VERSION ""

NS_ :

BS_:

BU_: WCM4 WCM3 WCM2 WCM VPM VLM VKM VICM VECM VDM VCU_RTOS_ETH VCU_ENTRY_ETH VCU_AGVM_ETH VCU UVM UPM TIM TEST_TOOL_1 TCP_ETH TCP TCM TCCM SRR_SRR_ETH SRR_SRR SRR_SLR_ETH SRR_SLR SRR_RR SRR_RF_ETH SRR_RF SRR_LR_CR SRR_LF_ETH SRR_LF SIB SDM SCL SBZA_R SBZA_L SBM SAM_RR SAM_RF SAM_LR SAM_LF SAM_BH SADS RadioLow_ETH RadioLow RSI_RTOS_ETH RSI RDCM PTM PLCM PFCM PDR_ETH PDR PCM PA ODS2 ODS NVM MTCM_R MTCM_L MSM_RR MSM_P MSM_LR MSM_D MSB2 MSB1 MRCM_R MRCM_L MFC LRR_RR_ETH LRR_LR_ETH LRR_CF_ETH LRR LRL_CF_ETH LIB_48V LIB1 IPC_INT IPC_GP IPC ICS_Info ICCM HVAC_FP_R HVAC_FP_F HUD_CAN HDLM FPI_RTOS_ETH FPI FOPM FCM_LC FCM EPSb EPS_1 EPSRAb EPSRAa EPS EOCM_HC_Superset EOCM_HCP2 EOCM ELM ECP_X1 ECP_S2 ECP_S ECP_MC ECP_H3 ECP_H2 ECP_H1 ECP_E ECM EBCM DMS DEFC DCM CSM_ETH CSM_AV CSM CGM_OTA_ETH CGM BSM_MH BSM_HEV BSM BCM ARS ARB APA AOS AMP ALC AHS AHL_AFL ADIMb ADIMa ACP2_MCU

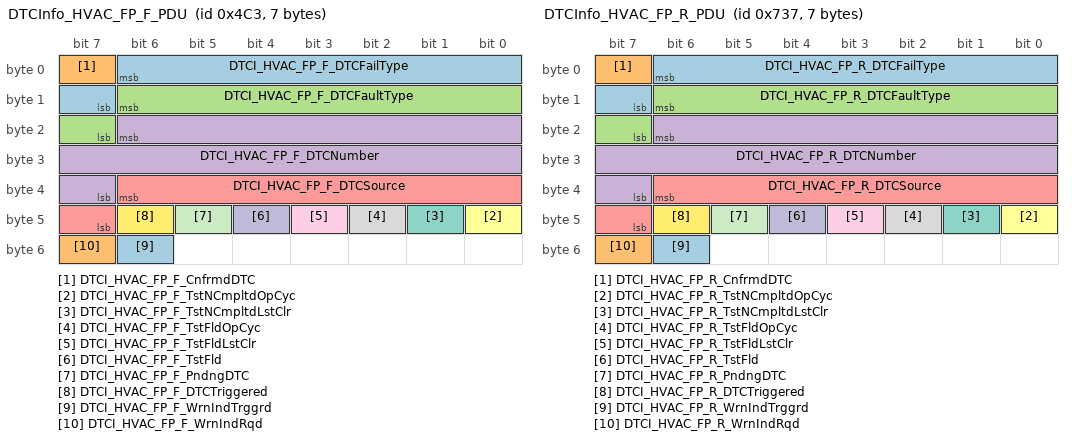
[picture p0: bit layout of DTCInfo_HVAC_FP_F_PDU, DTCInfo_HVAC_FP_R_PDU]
BO_ 1219 DTCInfo_HVAC_FP_F_PDU: 7 HVAC_FP_F
 SG_ DTCI_HVAC_FP_F_DTCFailType : 6|8@0+ (1,0) [0|255] "" TCP,CSM
 SG_ DTCI_HVAC_FP_F_CnfrmdDTC : 7|1@0+ (1,0) [0|1] "" TCP,CSM
 SG_ DTCI_HVAC_FP_F_DTCFaultType : 14|8@0+ (1,0) [0|3] "" TCP,CSM
 SG_ DTCI_HVAC_FP_F_DTCNumber : 22|16@0+ (1,0) [0|65535] "" TCP,CSM
 SG_ DTCI_HVAC_FP_F_DTCSource : 38|8@0+ (1,0) [0|255] "" CGM,TCP,CSM
 SG_ DTCI_HVAC_FP_F_TstNCmpltdOpCyc : 40|1@0+ (1,0) [0|1] "" TCP,CSM
 SG_ DTCI_HVAC_FP_F_TstNCmpltdLstClr : 41|1@0+ (1,0) [0|1] "" TCP,CSM
 SG_ DTCI_HVAC_FP_F_TstFldOpCyc : 42|1@0+ (1,0) [0|1] "" TCP,CSM
 SG_ DTCI_HVAC_FP_F_TstFldLstClr : 43|1@0+ (1,0) [0|1] "" TCP,CSM
 SG_ DTCI_HVAC_FP_F_TstFld : 44|1@0+ (1,0) [0|1] "" TCP,CSM
 SG_ DTCI_HVAC_FP_F_PndngDTC : 45|1@0+ (1,0) [0|1] "" TCP,CSM
 SG_ DTCI_HVAC_FP_F_DTCTriggered : 46|1@0+ (1,0) [0|1] "" TCP,CSM
 SG_ DTCI_HVAC_FP_F_WrnIndTrggrd : 54|1@0+ (1,0) [0|1] "" TCP,CSM
 SG_ DTCI_HVAC_FP_F_WrnIndRqd : 55|1@0+ (1,0) [0|1] "" TCP,CSM

BO_ 1847 DTCInfo_HVAC_FP_R_PDU: 7 HVAC_FP_R
 SG_ DTCI_HVAC_FP_R_DTCFailType : 6|8@0+ (1,0) [0|255] "" TCP,CSM
 SG_ DTCI_HVAC_FP_R_CnfrmdDTC : 7|1@0+ (1,0) [0|1] "" TCP,CSM
 SG_ DTCI_HVAC_FP_R_DTCFaultType : 14|8@0+ (1,0) [0|3] "" TCP,CSM
 SG_ DTCI_HVAC_FP_R_DTCNumber : 22|16@0+ (1,0) [0|65535] "" TCP,CSM
 SG_ DTCI_HVAC_FP_R_DTCSource : 38|8@0+ (1,0) [0|255] "" CGM,TCP,CSM
 SG_ DTCI_HVAC_FP_R_TstNCmpltdOpCyc : 40|1@0+ (1,0) [0|1] "" TCP,CSM
 SG_ DTCI_HVAC_FP_R_TstNCmpltdLstClr : 41|1@0+ (1,0) [0|1] "" TCP,CSM
 SG_ DTCI_HVAC_FP_R_TstFldOpCyc : 42|1@0+ (1,0) [0|1] "" TCP,CSM
 SG_ DTCI_HVAC_FP_R_TstFldLstClr : 43|1@0+ (1,0) [0|1] "" TCP,CSM
 SG_ DTCI_HVAC_FP_R_TstFld : 44|1@0+ (1,0) [0|1] "" TCP,CSM
 SG_ DTCI_HVAC_FP_R_PndngDTC : 45|1@0+ (1,0) [0|1] "" TCP,CSM
 SG_ DTCI_HVAC_FP_R_DTCTriggered : 46|1@0+ (1,0) [0|1] "" TCP,CSM
 SG_ DTCI_HVAC_FP_R_WrnIndTrggrd : 54|1@0+ (1,0) [0|1] "" TCP,CSM
 SG_ DTCI_HVAC_FP_R_WrnIndRqd : 55|1@0+ (1,0) [0|1] "" TCP,CSM

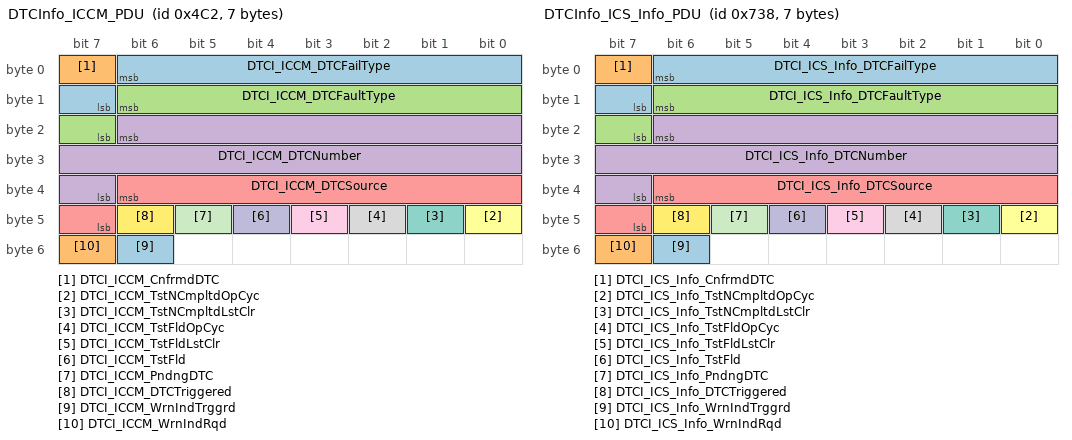
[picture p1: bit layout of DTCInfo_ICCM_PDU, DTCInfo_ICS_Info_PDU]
BO_ 1218 DTCInfo_ICCM_PDU: 7 CGM
 SG_ DTCI_ICCM_DTCFailType : 6|8@0+ (1,0) [0|255] "" TCP,CSM
 SG_ DTCI_ICCM_CnfrmdDTC : 7|1@0+ (1,0) [0|1] "" TCP,CSM
 SG_ DTCI_ICCM_DTCFaultType : 14|8@0+ (1,0) [0|3] "" TCP,CSM
 SG_ DTCI_ICCM_DTCNumber : 22|16@0+ (1,0) [0|65535] "" TCP,CSM
 SG_ DTCI_ICCM_DTCSource : 38|8@0+ (1,0) [0|255] "" TCP,CSM
 SG_ DTCI_ICCM_TstNCmpltdOpCyc : 40|1@0+ (1,0) [0|1] "" TCP,CSM
 SG_ DTCI_ICCM_TstNCmpltdLstClr : 41|1@0+ (1,0) [0|1] "" TCP,CSM
 SG_ DTCI_ICCM_TstFldOpCyc : 42|1@0+ (1,0) [0|1] "" TCP,CSM
 SG_ DTCI_ICCM_TstFldLstClr : 43|1@0+ (1,0) [0|1] "" TCP,CSM
 SG_ DTCI_ICCM_TstFld : 44|1@0+ (1,0) [0|1] "" TCP,CSM
 SG_ DTCI_ICCM_PndngDTC : 45|1@0+ (1,0) [0|1] "" TCP,CSM
 SG_ DTCI_ICCM_DTCTriggered : 46|1@0+ (1,0) [0|1] "" TCP,CSM
 SG_ DTCI_ICCM_WrnIndTrggrd : 54|1@0+ (1,0) [0|1] "" TCP,CSM
 SG_ DTCI_ICCM_WrnIndRqd : 55|1@0+ (1,0) [0|1] "" TCP,CSM

BO_ 1848 DTCInfo_ICS_Info_PDU: 7 ICS_Info
 SG_ DTCI_ICS_Info_DTCFailType : 6|8@0+ (1,0) [0|255] "" TCP,CSM
 SG_ DTCI_ICS_Info_CnfrmdDTC : 7|1@0+ (1,0) [0|1] "" TCP,CSM
 SG_ DTCI_ICS_Info_DTCFaultType : 14|8@0+ (1,0) [0|3] "" TCP,CSM
 SG_ DTCI_ICS_Info_DTCNumber : 22|16@0+ (1,0) [0|65535] "" TCP,CSM
 SG_ DTCI_ICS_Info_DTCSource : 38|8@0+ (1,0) [0|255] "" CGM,TCP,CSM
 SG_ DTCI_ICS_Info_TstNCmpltdOpCyc : 40|1@0+ (1,0) [0|1] "" TCP,CSM
 SG_ DTCI_ICS_Info_TstNCmpltdLstClr : 41|1@0+ (1,0) [0|1] "" TCP,CSM
 SG_ DTCI_ICS_Info_TstFldOpCyc : 42|1@0+ (1,0) [0|1] "" TCP,CSM
 SG_ DTCI_ICS_Info_TstFldLstClr : 43|1@0+ (1,0) [0|1] "" TCP,CSM
 SG_ DTCI_ICS_Info_TstFld : 44|1@0+ (1,0) [0|1] "" TCP,CSM
 SG_ DTCI_ICS_Info_PndngDTC : 45|1@0+ (1,0) [0|1] "" TCP,CSM
 SG_ DTCI_ICS_Info_DTCTriggered : 46|1@0+ (1,0) [0|1] "" TCP,CSM
 SG_ DTCI_ICS_Info_WrnIndTrggrd : 54|1@0+ (1,0) [0|1] "" TCP,CSM
 SG_ DTCI_ICS_Info_WrnIndRqd : 55|1@0+ (1,0) [0|1] "" TCP,CSM

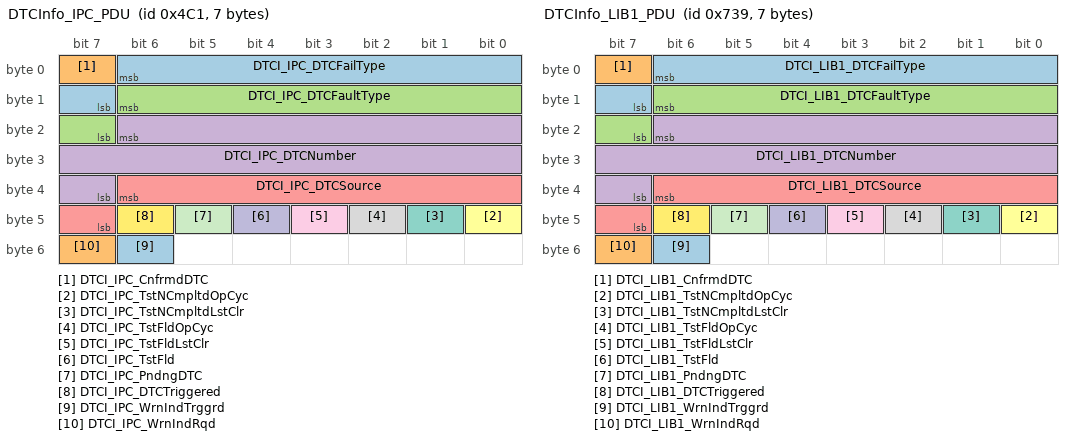
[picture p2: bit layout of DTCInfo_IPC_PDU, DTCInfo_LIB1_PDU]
BO_ 1217 DTCInfo_IPC_PDU: 7 IPC
 SG_ DTCI_IPC_DTCFailType : 6|8@0+ (1,0) [0|255] "" CGM,TCP,CSM
 SG_ DTCI_IPC_CnfrmdDTC : 7|1@0+ (1,0) [0|1] "" CGM,TCP,CSM
 SG_ DTCI_IPC_DTCFaultType : 14|8@0+ (1,0) [0|3] "" CGM,TCP,CSM
 SG_ DTCI_IPC_DTCNumber : 22|16@0+ (1,0) [0|65535] "" CGM,TCP,CSM
 SG_ DTCI_IPC_DTCSource : 38|8@0+ (1,0) [0|255] "" CGM,TCP,CSM
 SG_ DTCI_IPC_TstNCmpltdOpCyc : 40|1@0+ (1,0) [0|1] "" CGM,TCP,CSM
 SG_ DTCI_IPC_TstNCmpltdLstClr : 41|1@0+ (1,0) [0|1] "" CGM,TCP,CSM
 SG_ DTCI_IPC_TstFldOpCyc : 42|1@0+ (1,0) [0|1] "" CGM,TCP,CSM
 SG_ DTCI_IPC_TstFldLstClr : 43|1@0+ (1,0) [0|1] "" CGM,TCP,CSM
 SG_ DTCI_IPC_TstFld : 44|1@0+ (1,0) [0|1] "" CGM,TCP,CSM
 SG_ DTCI_IPC_PndngDTC : 45|1@0+ (1,0) [0|1] "" CGM,TCP,CSM
 SG_ DTCI_IPC_DTCTriggered : 46|1@0+ (1,0) [0|1] "" CGM,TCP,CSM
 SG_ DTCI_IPC_WrnIndTrggrd : 54|1@0+ (1,0) [0|1] "" CGM,TCP,CSM
 SG_ DTCI_IPC_WrnIndRqd : 55|1@0+ (1,0) [0|1] "" CGM,TCP,CSM

BO_ 1849 DTCInfo_LIB1_PDU: 7 CGM
 SG_ DTCI_LIB1_DTCFailType : 6|8@0+ (1,0) [0|255] "" TCP,CSM
 SG_ DTCI_LIB1_CnfrmdDTC : 7|1@0+ (1,0) [0|1] "" TCP,CSM
 SG_ DTCI_LIB1_DTCFaultType : 14|8@0+ (1,0) [0|3] "" TCP,CSM
 SG_ DTCI_LIB1_DTCNumber : 22|16@0+ (1,0) [0|65535] "" TCP,CSM
 SG_ DTCI_LIB1_DTCSource : 38|8@0+ (1,0) [0|255] "" TCP,CSM
 SG_ DTCI_LIB1_TstNCmpltdOpCyc : 40|1@0+ (1,0) [0|1] "" TCP,CSM
 SG_ DTCI_LIB1_TstNCmpltdLstClr : 41|1@0+ (1,0) [0|1] "" TCP,CSM
 SG_ DTCI_LIB1_TstFldOpCyc : 42|1@0+ (1,0) [0|1] "" TCP,CSM
 SG_ DTCI_LIB1_TstFldLstClr : 43|1@0+ (1,0) [0|1] "" TCP,CSM
 SG_ DTCI_LIB1_TstFld : 44|1@0+ (1,0) [0|1] "" TCP,CSM
 SG_ DTCI_LIB1_PndngDTC : 45|1@0+ (1,0) [0|1] "" TCP,CSM
 SG_ DTCI_LIB1_DTCTriggered : 46|1@0+ (1,0) [0|1] "" TCP,CSM
 SG_ DTCI_LIB1_WrnIndTrggrd : 54|1@0+ (1,0) [0|1] "" TCP,CSM
 SG_ DTCI_LIB1_WrnIndRqd : 55|1@0+ (1,0) [0|1] "" TCP,CSM

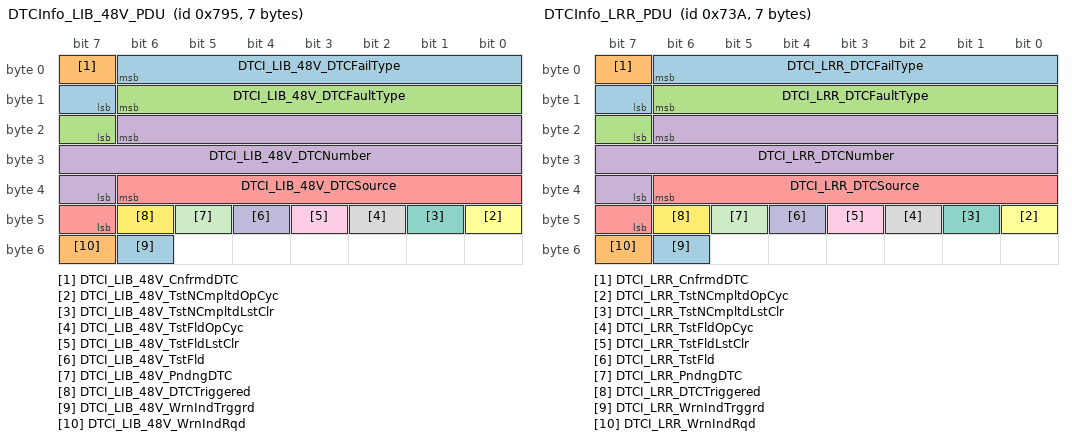
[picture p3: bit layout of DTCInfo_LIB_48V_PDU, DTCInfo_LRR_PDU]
BO_ 1941 DTCInfo_LIB_48V_PDU: 7 CGM
 SG_ DTCI_LIB_48V_DTCFailType : 6|8@0+ (1,0) [0|255] "" TCP
 SG_ DTCI_LIB_48V_CnfrmdDTC : 7|1@0+ (1,0) [0|1] "" TCP
 SG_ DTCI_LIB_48V_DTCFaultType : 14|8@0+ (1,0) [0|3] "" TCP
 SG_ DTCI_LIB_48V_DTCNumber : 22|16@0+ (1,0) [0|65535] "" TCP
 SG_ DTCI_LIB_48V_DTCSource : 38|8@0+ (1,0) [0|255] "" TCP
 SG_ DTCI_LIB_48V_TstNCmpltdOpCyc : 40|1@0+ (1,0) [0|1] "" TCP
 SG_ DTCI_LIB_48V_TstNCmpltdLstClr : 41|1@0+ (1,0) [0|1] "" TCP
 SG_ DTCI_LIB_48V_TstFldOpCyc : 42|1@0+ (1,0) [0|1] "" TCP
 SG_ DTCI_LIB_48V_TstFldLstClr : 43|1@0+ (1,0) [0|1] "" TCP
 SG_ DTCI_LIB_48V_TstFld : 44|1@0+ (1,0) [0|1] "" TCP
 SG_ DTCI_LIB_48V_PndngDTC : 45|1@0+ (1,0) [0|1] "" TCP
 SG_ DTCI_LIB_48V_DTCTriggered : 46|1@0+ (1,0) [0|1] "" TCP
 SG_ DTCI_LIB_48V_WrnIndTrggrd : 54|1@0+ (1,0) [0|1] "" TCP
 SG_ DTCI_LIB_48V_WrnIndRqd : 55|1@0+ (1,0) [0|1] "" TCP

BO_ 1850 DTCInfo_LRR_PDU: 7 CGM
 SG_ DTCI_LRR_DTCFailType : 6|8@0+ (1,0) [0|255] "" TCP,CSM
 SG_ DTCI_LRR_CnfrmdDTC : 7|1@0+ (1,0) [0|1] "" TCP,CSM
 SG_ DTCI_LRR_DTCFaultType : 14|8@0+ (1,0) [0|3] "" TCP,CSM
 SG_ DTCI_LRR_DTCNumber : 22|16@0+ (1,0) [0|65535] "" TCP,CSM
 SG_ DTCI_LRR_DTCSource : 38|8@0+ (1,0) [0|255] "" TCP,CSM
 SG_ DTCI_LRR_TstNCmpltdOpCyc : 40|1@0+ (1,0) [0|1] "" TCP,CSM
 SG_ DTCI_LRR_TstNCmpltdLstClr : 41|1@0+ (1,0) [0|1] "" TCP,CSM
 SG_ DTCI_LRR_TstFldOpCyc : 42|1@0+ (1,0) [0|1] "" TCP,CSM
 SG_ DTCI_LRR_TstFldLstClr : 43|1@0+ (1,0) [0|1] "" TCP,CSM
 SG_ DTCI_LRR_TstFld : 44|1@0+ (1,0) [0|1] "" TCP,CSM
 SG_ DTCI_LRR_PndngDTC : 45|1@0+ (1,0) [0|1] "" TCP,CSM
 SG_ DTCI_LRR_DTCTriggered : 46|1@0+ (1,0) [0|1] "" TCP,CSM
 SG_ DTCI_LRR_WrnIndTrggrd : 54|1@0+ (1,0) [0|1] "" TCP,CSM
 SG_ DTCI_LRR_WrnIndRqd : 55|1@0+ (1,0) [0|1] "" TCP,CSM

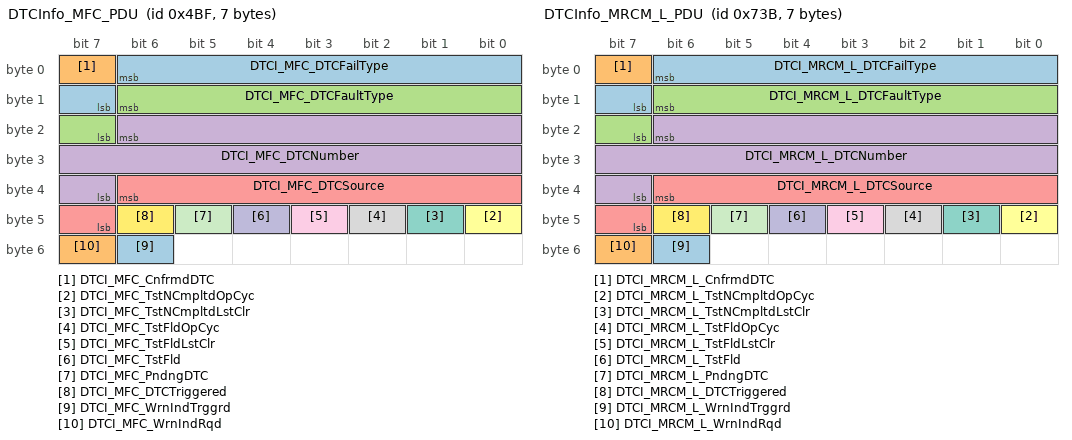
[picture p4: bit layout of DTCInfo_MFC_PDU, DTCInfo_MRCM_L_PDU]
BO_ 1215 DTCInfo_MFC_PDU: 7 MFC
 SG_ DTCI_MFC_DTCFailType : 6|8@0+ (1,0) [0|255] "" TCP,CSM
 SG_ DTCI_MFC_CnfrmdDTC : 7|1@0+ (1,0) [0|1] "" TCP,CSM
 SG_ DTCI_MFC_DTCFaultType : 14|8@0+ (1,0) [0|3] "" TCP,CSM
 SG_ DTCI_MFC_DTCNumber : 22|16@0+ (1,0) [0|65535] "" TCP,CSM
 SG_ DTCI_MFC_DTCSource : 38|8@0+ (1,0) [0|255] "" CGM,TCP,CSM
 SG_ DTCI_MFC_TstNCmpltdOpCyc : 40|1@0+ (1,0) [0|1] "" TCP,CSM
 SG_ DTCI_MFC_TstNCmpltdLstClr : 41|1@0+ (1,0) [0|1] "" TCP,CSM
 SG_ DTCI_MFC_TstFldOpCyc : 42|1@0+ (1,0) [0|1] "" TCP,CSM
 SG_ DTCI_MFC_TstFldLstClr : 43|1@0+ (1,0) [0|1] "" TCP,CSM
 SG_ DTCI_MFC_TstFld : 44|1@0+ (1,0) [0|1] "" TCP,CSM
 SG_ DTCI_MFC_PndngDTC : 45|1@0+ (1,0) [0|1] "" TCP,CSM
 SG_ DTCI_MFC_DTCTriggered : 46|1@0+ (1,0) [0|1] "" TCP,CSM
 SG_ DTCI_MFC_WrnIndTrggrd : 54|1@0+ (1,0) [0|1] "" TCP,CSM
 SG_ DTCI_MFC_WrnIndRqd : 55|1@0+ (1,0) [0|1] "" TCP,CSM

BO_ 1851 DTCInfo_MRCM_L_PDU: 7 CGM
 SG_ DTCI_MRCM_L_DTCFailType : 6|8@0+ (1,0) [0|255] "" TCP,CSM
 SG_ DTCI_MRCM_L_CnfrmdDTC : 7|1@0+ (1,0) [0|1] "" TCP,CSM
 SG_ DTCI_MRCM_L_DTCFaultType : 14|8@0+ (1,0) [0|3] "" TCP,CSM
 SG_ DTCI_MRCM_L_DTCNumber : 22|16@0+ (1,0) [0|65535] "" TCP,CSM
 SG_ DTCI_MRCM_L_DTCSource : 38|8@0+ (1,0) [0|255] "" TCP,CSM
 SG_ DTCI_MRCM_L_TstNCmpltdOpCyc : 40|1@0+ (1,0) [0|1] "" TCP,CSM
 SG_ DTCI_MRCM_L_TstNCmpltdLstClr : 41|1@0+ (1,0) [0|1] "" TCP,CSM
 SG_ DTCI_MRCM_L_TstFldOpCyc : 42|1@0+ (1,0) [0|1] "" TCP,CSM
 SG_ DTCI_MRCM_L_TstFldLstClr : 43|1@0+ (1,0) [0|1] "" TCP,CSM
 SG_ DTCI_MRCM_L_TstFld : 44|1@0+ (1,0) [0|1] "" TCP,CSM
 SG_ DTCI_MRCM_L_PndngDTC : 45|1@0+ (1,0) [0|1] "" TCP,CSM
 SG_ DTCI_MRCM_L_DTCTriggered : 46|1@0+ (1,0) [0|1] "" TCP,CSM
 SG_ DTCI_MRCM_L_WrnIndTrggrd : 54|1@0+ (1,0) [0|1] "" TCP,CSM
 SG_ DTCI_MRCM_L_WrnIndRqd : 55|1@0+ (1,0) [0|1] "" TCP,CSM

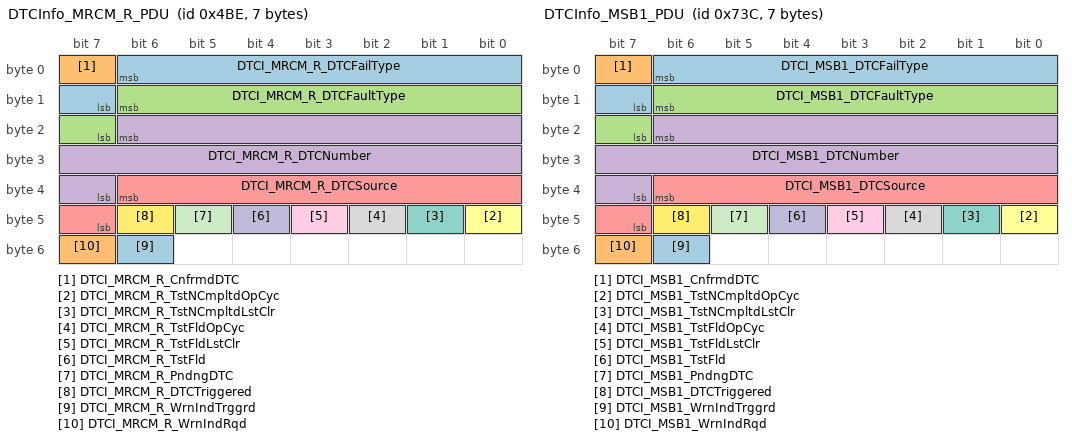
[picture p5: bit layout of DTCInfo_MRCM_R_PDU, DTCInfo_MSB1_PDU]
BO_ 1214 DTCInfo_MRCM_R_PDU: 7 CGM
 SG_ DTCI_MRCM_R_DTCFailType : 6|8@0+ (1,0) [0|255] "" TCP,CSM
 SG_ DTCI_MRCM_R_CnfrmdDTC : 7|1@0+ (1,0) [0|1] "" TCP,CSM
 SG_ DTCI_MRCM_R_DTCFaultType : 14|8@0+ (1,0) [0|3] "" TCP,CSM
 SG_ DTCI_MRCM_R_DTCNumber : 22|16@0+ (1,0) [0|65535] "" TCP,CSM
 SG_ DTCI_MRCM_R_DTCSource : 38|8@0+ (1,0) [0|255] "" TCP,CSM
 SG_ DTCI_MRCM_R_TstNCmpltdOpCyc : 40|1@0+ (1,0) [0|1] "" TCP,CSM
 SG_ DTCI_MRCM_R_TstNCmpltdLstClr : 41|1@0+ (1,0) [0|1] "" TCP,CSM
 SG_ DTCI_MRCM_R_TstFldOpCyc : 42|1@0+ (1,0) [0|1] "" TCP,CSM
 SG_ DTCI_MRCM_R_TstFldLstClr : 43|1@0+ (1,0) [0|1] "" TCP,CSM
 SG_ DTCI_MRCM_R_TstFld : 44|1@0+ (1,0) [0|1] "" TCP,CSM
 SG_ DTCI_MRCM_R_PndngDTC : 45|1@0+ (1,0) [0|1] "" TCP,CSM
 SG_ DTCI_MRCM_R_DTCTriggered : 46|1@0+ (1,0) [0|1] "" TCP,CSM
 SG_ DTCI_MRCM_R_WrnIndTrggrd : 54|1@0+ (1,0) [0|1] "" TCP,CSM
 SG_ DTCI_MRCM_R_WrnIndRqd : 55|1@0+ (1,0) [0|1] "" TCP,CSM

BO_ 1852 DTCInfo_MSB1_PDU: 7 CGM
 SG_ DTCI_MSB1_DTCFailType : 6|8@0+ (1,0) [0|255] "" TCP,CSM
 SG_ DTCI_MSB1_CnfrmdDTC : 7|1@0+ (1,0) [0|1] "" TCP,CSM
 SG_ DTCI_MSB1_DTCFaultType : 14|8@0+ (1,0) [0|3] "" TCP,CSM
 SG_ DTCI_MSB1_DTCNumber : 22|16@0+ (1,0) [0|65535] "" TCP,CSM
 SG_ DTCI_MSB1_DTCSource : 38|8@0+ (1,0) [0|255] "" TCP,CSM
 SG_ DTCI_MSB1_TstNCmpltdOpCyc : 40|1@0+ (1,0) [0|1] "" TCP,CSM
 SG_ DTCI_MSB1_TstNCmpltdLstClr : 41|1@0+ (1,0) [0|1] "" TCP,CSM
 SG_ DTCI_MSB1_TstFldOpCyc : 42|1@0+ (1,0) [0|1] "" TCP,CSM
 SG_ DTCI_MSB1_TstFldLstClr : 43|1@0+ (1,0) [0|1] "" TCP,CSM
 SG_ DTCI_MSB1_TstFld : 44|1@0+ (1,0) [0|1] "" TCP,CSM
 SG_ DTCI_MSB1_PndngDTC : 45|1@0+ (1,0) [0|1] "" TCP,CSM
 SG_ DTCI_MSB1_DTCTriggered : 46|1@0+ (1,0) [0|1] "" TCP,CSM
 SG_ DTCI_MSB1_WrnIndTrggrd : 54|1@0+ (1,0) [0|1] "" TCP,CSM
 SG_ DTCI_MSB1_WrnIndRqd : 55|1@0+ (1,0) [0|1] "" TCP,CSM

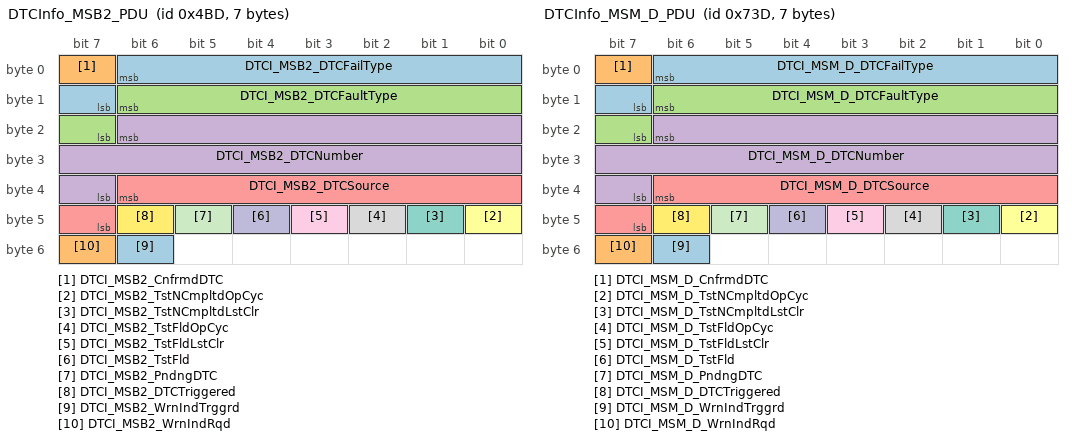
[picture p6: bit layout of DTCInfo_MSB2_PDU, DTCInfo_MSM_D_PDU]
BO_ 1213 DTCInfo_MSB2_PDU: 7 CGM
 SG_ DTCI_MSB2_DTCFailType : 6|8@0+ (1,0) [0|255] "" TCP,CSM
 SG_ DTCI_MSB2_CnfrmdDTC : 7|1@0+ (1,0) [0|1] "" TCP,CSM
 SG_ DTCI_MSB2_DTCFaultType : 14|8@0+ (1,0) [0|3] "" TCP,CSM
 SG_ DTCI_MSB2_DTCNumber : 22|16@0+ (1,0) [0|65535] "" TCP,CSM
 SG_ DTCI_MSB2_DTCSource : 38|8@0+ (1,0) [0|255] "" TCP,CSM
 SG_ DTCI_MSB2_TstNCmpltdOpCyc : 40|1@0+ (1,0) [0|1] "" TCP,CSM
 SG_ DTCI_MSB2_TstNCmpltdLstClr : 41|1@0+ (1,0) [0|1] "" TCP,CSM
 SG_ DTCI_MSB2_TstFldOpCyc : 42|1@0+ (1,0) [0|1] "" TCP,CSM
 SG_ DTCI_MSB2_TstFldLstClr : 43|1@0+ (1,0) [0|1] "" TCP,CSM
 SG_ DTCI_MSB2_TstFld : 44|1@0+ (1,0) [0|1] "" TCP,CSM
 SG_ DTCI_MSB2_PndngDTC : 45|1@0+ (1,0) [0|1] "" TCP,CSM
 SG_ DTCI_MSB2_DTCTriggered : 46|1@0+ (1,0) [0|1] "" TCP,CSM
 SG_ DTCI_MSB2_WrnIndTrggrd : 54|1@0+ (1,0) [0|1] "" TCP,CSM
 SG_ DTCI_MSB2_WrnIndRqd : 55|1@0+ (1,0) [0|1] "" TCP,CSM

BO_ 1853 DTCInfo_MSM_D_PDU: 7 CGM
 SG_ DTCI_MSM_D_DTCFailType : 6|8@0+ (1,0) [0|255] "" TCP,CSM
 SG_ DTCI_MSM_D_CnfrmdDTC : 7|1@0+ (1,0) [0|1] "" TCP,CSM
 SG_ DTCI_MSM_D_DTCFaultType : 14|8@0+ (1,0) [0|3] "" TCP,CSM
 SG_ DTCI_MSM_D_DTCNumber : 22|16@0+ (1,0) [0|65535] "" TCP,CSM
 SG_ DTCI_MSM_D_DTCSource : 38|8@0+ (1,0) [0|255] "" TCP,CSM
 SG_ DTCI_MSM_D_TstNCmpltdOpCyc : 40|1@0+ (1,0) [0|1] "" TCP,CSM
 SG_ DTCI_MSM_D_TstNCmpltdLstClr : 41|1@0+ (1,0) [0|1] "" TCP,CSM
 SG_ DTCI_MSM_D_TstFldOpCyc : 42|1@0+ (1,0) [0|1] "" TCP,CSM
 SG_ DTCI_MSM_D_TstFldLstClr : 43|1@0+ (1,0) [0|1] "" TCP,CSM
 SG_ DTCI_MSM_D_TstFld : 44|1@0+ (1,0) [0|1] "" TCP,CSM
 SG_ DTCI_MSM_D_PndngDTC : 45|1@0+ (1,0) [0|1] "" TCP,CSM
 SG_ DTCI_MSM_D_DTCTriggered : 46|1@0+ (1,0) [0|1] "" TCP,CSM
 SG_ DTCI_MSM_D_WrnIndTrggrd : 54|1@0+ (1,0) [0|1] "" TCP,CSM
 SG_ DTCI_MSM_D_WrnIndRqd : 55|1@0+ (1,0) [0|1] "" TCP,CSM

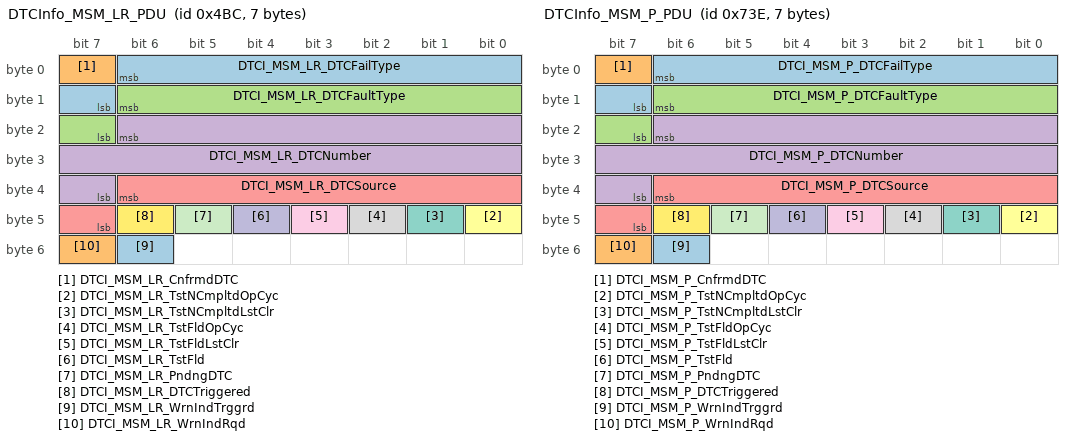
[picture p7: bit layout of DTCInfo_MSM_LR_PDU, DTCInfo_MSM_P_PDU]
BO_ 1212 DTCInfo_MSM_LR_PDU: 7 CGM
 SG_ DTCI_MSM_LR_DTCFailType : 6|8@0+ (1,0) [0|255] "" TCP,CSM
 SG_ DTCI_MSM_LR_CnfrmdDTC : 7|1@0+ (1,0) [0|1] "" TCP,CSM
 SG_ DTCI_MSM_LR_DTCFaultType : 14|8@0+ (1,0) [0|3] "" TCP,CSM
 SG_ DTCI_MSM_LR_DTCNumber : 22|16@0+ (1,0) [0|65535] "" TCP,CSM
 SG_ DTCI_MSM_LR_DTCSource : 38|8@0+ (1,0) [0|255] "" TCP,CSM
 SG_ DTCI_MSM_LR_TstNCmpltdOpCyc : 40|1@0+ (1,0) [0|1] "" TCP,CSM
 SG_ DTCI_MSM_LR_TstNCmpltdLstClr : 41|1@0+ (1,0) [0|1] "" TCP,CSM
 SG_ DTCI_MSM_LR_TstFldOpCyc : 42|1@0+ (1,0) [0|1] "" TCP,CSM
 SG_ DTCI_MSM_LR_TstFldLstClr : 43|1@0+ (1,0) [0|1] "" TCP,CSM
 SG_ DTCI_MSM_LR_TstFld : 44|1@0+ (1,0) [0|1] "" TCP,CSM
 SG_ DTCI_MSM_LR_PndngDTC : 45|1@0+ (1,0) [0|1] "" TCP,CSM
 SG_ DTCI_MSM_LR_DTCTriggered : 46|1@0+ (1,0) [0|1] "" TCP,CSM
 SG_ DTCI_MSM_LR_WrnIndTrggrd : 54|1@0+ (1,0) [0|1] "" TCP,CSM
 SG_ DTCI_MSM_LR_WrnIndRqd : 55|1@0+ (1,0) [0|1] "" TCP,CSM

BO_ 1854 DTCInfo_MSM_P_PDU: 7 CGM
 SG_ DTCI_MSM_P_DTCFailType : 6|8@0+ (1,0) [0|255] "" TCP,CSM
 SG_ DTCI_MSM_P_CnfrmdDTC : 7|1@0+ (1,0) [0|1] "" TCP,CSM
 SG_ DTCI_MSM_P_DTCFaultType : 14|8@0+ (1,0) [0|3] "" TCP,CSM
 SG_ DTCI_MSM_P_DTCNumber : 22|16@0+ (1,0) [0|65535] "" TCP,CSM
 SG_ DTCI_MSM_P_DTCSource : 38|8@0+ (1,0) [0|255] "" TCP,CSM
 SG_ DTCI_MSM_P_TstNCmpltdOpCyc : 40|1@0+ (1,0) [0|1] "" TCP,CSM
 SG_ DTCI_MSM_P_TstNCmpltdLstClr : 41|1@0+ (1,0) [0|1] "" TCP,CSM
 SG_ DTCI_MSM_P_TstFldOpCyc : 42|1@0+ (1,0) [0|1] "" TCP,CSM
 SG_ DTCI_MSM_P_TstFldLstClr : 43|1@0+ (1,0) [0|1] "" TCP,CSM
 SG_ DTCI_MSM_P_TstFld : 44|1@0+ (1,0) [0|1] "" TCP,CSM
 SG_ DTCI_MSM_P_PndngDTC : 45|1@0+ (1,0) [0|1] "" TCP,CSM
 SG_ DTCI_MSM_P_DTCTriggered : 46|1@0+ (1,0) [0|1] "" TCP,CSM
 SG_ DTCI_MSM_P_WrnIndTrggrd : 54|1@0+ (1,0) [0|1] "" TCP,CSM
 SG_ DTCI_MSM_P_WrnIndRqd : 55|1@0+ (1,0) [0|1] "" TCP,CSM

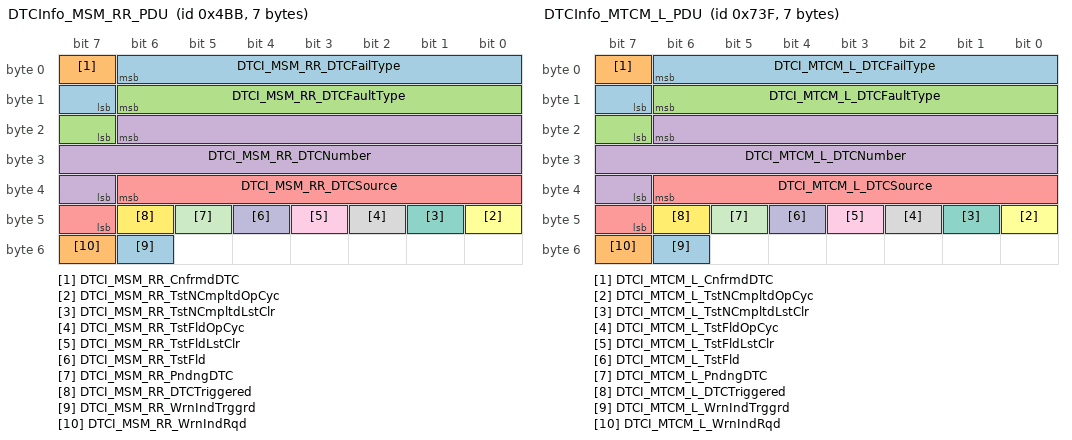
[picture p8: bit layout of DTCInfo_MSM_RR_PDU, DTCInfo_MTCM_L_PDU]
BO_ 1211 DTCInfo_MSM_RR_PDU: 7 CGM
 SG_ DTCI_MSM_RR_DTCFailType : 6|8@0+ (1,0) [0|255] "" TCP,CSM
 SG_ DTCI_MSM_RR_CnfrmdDTC : 7|1@0+ (1,0) [0|1] "" TCP,CSM
 SG_ DTCI_MSM_RR_DTCFaultType : 14|8@0+ (1,0) [0|3] "" TCP,CSM
 SG_ DTCI_MSM_RR_DTCNumber : 22|16@0+ (1,0) [0|65535] "" TCP,CSM
 SG_ DTCI_MSM_RR_DTCSource : 38|8@0+ (1,0) [0|255] "" TCP,CSM
 SG_ DTCI_MSM_RR_TstNCmpltdOpCyc : 40|1@0+ (1,0) [0|1] "" TCP,CSM
 SG_ DTCI_MSM_RR_TstNCmpltdLstClr : 41|1@0+ (1,0) [0|1] "" TCP,CSM
 SG_ DTCI_MSM_RR_TstFldOpCyc : 42|1@0+ (1,0) [0|1] "" TCP,CSM
 SG_ DTCI_MSM_RR_TstFldLstClr : 43|1@0+ (1,0) [0|1] "" TCP,CSM
 SG_ DTCI_MSM_RR_TstFld : 44|1@0+ (1,0) [0|1] "" TCP,CSM
 SG_ DTCI_MSM_RR_PndngDTC : 45|1@0+ (1,0) [0|1] "" TCP,CSM
 SG_ DTCI_MSM_RR_DTCTriggered : 46|1@0+ (1,0) [0|1] "" TCP,CSM
 SG_ DTCI_MSM_RR_WrnIndTrggrd : 54|1@0+ (1,0) [0|1] "" TCP,CSM
 SG_ DTCI_MSM_RR_WrnIndRqd : 55|1@0+ (1,0) [0|1] "" TCP,CSM

BO_ 1855 DTCInfo_MTCM_L_PDU: 7 CGM
 SG_ DTCI_MTCM_L_DTCFailType : 6|8@0+ (1,0) [0|255] "" TCP,CSM
 SG_ DTCI_MTCM_L_CnfrmdDTC : 7|1@0+ (1,0) [0|1] "" TCP,CSM
 SG_ DTCI_MTCM_L_DTCFaultType : 14|8@0+ (1,0) [0|3] "" TCP,CSM
 SG_ DTCI_MTCM_L_DTCNumber : 22|16@0+ (1,0) [0|65535] "" TCP,CSM
 SG_ DTCI_MTCM_L_DTCSource : 38|8@0+ (1,0) [0|255] "" TCP,CSM
 SG_ DTCI_MTCM_L_TstNCmpltdOpCyc : 40|1@0+ (1,0) [0|1] "" TCP,CSM
 SG_ DTCI_MTCM_L_TstNCmpltdLstClr : 41|1@0+ (1,0) [0|1] "" TCP,CSM
 SG_ DTCI_MTCM_L_TstFldOpCyc : 42|1@0+ (1,0) [0|1] "" TCP,CSM
 SG_ DTCI_MTCM_L_TstFldLstClr : 43|1@0+ (1,0) [0|1] "" TCP,CSM
 SG_ DTCI_MTCM_L_TstFld : 44|1@0+ (1,0) [0|1] "" TCP,CSM
 SG_ DTCI_MTCM_L_PndngDTC : 45|1@0+ (1,0) [0|1] "" TCP,CSM
 SG_ DTCI_MTCM_L_DTCTriggered : 46|1@0+ (1,0) [0|1] "" TCP,CSM
 SG_ DTCI_MTCM_L_WrnIndTrggrd : 54|1@0+ (1,0) [0|1] "" TCP,CSM
 SG_ DTCI_MTCM_L_WrnIndRqd : 55|1@0+ (1,0) [0|1] "" TCP,CSM

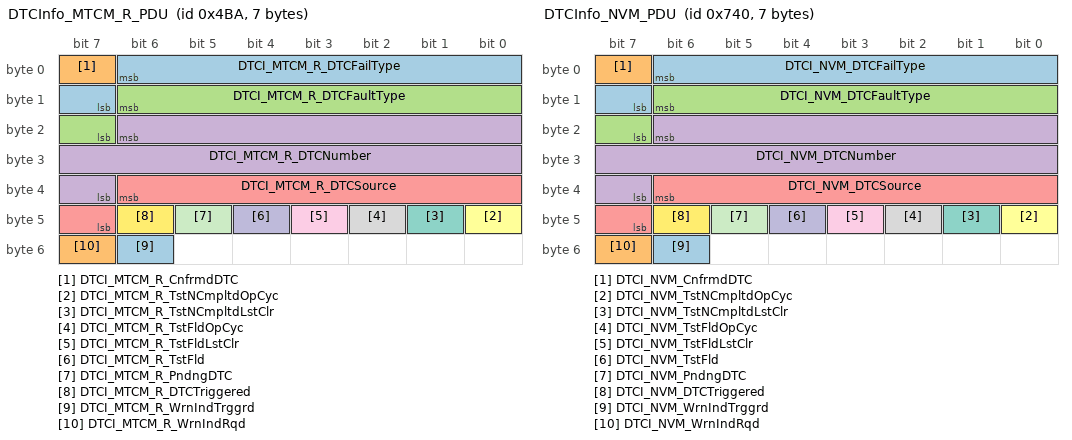
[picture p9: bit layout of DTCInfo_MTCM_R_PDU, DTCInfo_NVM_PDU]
BO_ 1210 DTCInfo_MTCM_R_PDU: 7 CGM
 SG_ DTCI_MTCM_R_DTCFailType : 6|8@0+ (1,0) [0|255] "" TCP,CSM
 SG_ DTCI_MTCM_R_CnfrmdDTC : 7|1@0+ (1,0) [0|1] "" TCP,CSM
 SG_ DTCI_MTCM_R_DTCFaultType : 14|8@0+ (1,0) [0|3] "" TCP,CSM
 SG_ DTCI_MTCM_R_DTCNumber : 22|16@0+ (1,0) [0|65535] "" TCP,CSM
 SG_ DTCI_MTCM_R_DTCSource : 38|8@0+ (1,0) [0|255] "" TCP,CSM
 SG_ DTCI_MTCM_R_TstNCmpltdOpCyc : 40|1@0+ (1,0) [0|1] "" TCP,CSM
 SG_ DTCI_MTCM_R_TstNCmpltdLstClr : 41|1@0+ (1,0) [0|1] "" TCP,CSM
 SG_ DTCI_MTCM_R_TstFldOpCyc : 42|1@0+ (1,0) [0|1] "" TCP,CSM
 SG_ DTCI_MTCM_R_TstFldLstClr : 43|1@0+ (1,0) [0|1] "" TCP,CSM
 SG_ DTCI_MTCM_R_TstFld : 44|1@0+ (1,0) [0|1] "" TCP,CSM
 SG_ DTCI_MTCM_R_PndngDTC : 45|1@0+ (1,0) [0|1] "" TCP,CSM
 SG_ DTCI_MTCM_R_DTCTriggered : 46|1@0+ (1,0) [0|1] "" TCP,CSM
 SG_ DTCI_MTCM_R_WrnIndTrggrd : 54|1@0+ (1,0) [0|1] "" TCP,CSM
 SG_ DTCI_MTCM_R_WrnIndRqd : 55|1@0+ (1,0) [0|1] "" TCP,CSM

BO_ 1856 DTCInfo_NVM_PDU: 7 CGM
 SG_ DTCI_NVM_DTCFailType : 6|8@0+ (1,0) [0|255] "" TCP,CSM
 SG_ DTCI_NVM_CnfrmdDTC : 7|1@0+ (1,0) [0|1] "" TCP,CSM
 SG_ DTCI_NVM_DTCFaultType : 14|8@0+ (1,0) [0|3] "" TCP,CSM
 SG_ DTCI_NVM_DTCNumber : 22|16@0+ (1,0) [0|65535] "" TCP,CSM
 SG_ DTCI_NVM_DTCSource : 38|8@0+ (1,0) [0|255] "" TCP,CSM
 SG_ DTCI_NVM_TstNCmpltdOpCyc : 40|1@0+ (1,0) [0|1] "" TCP,CSM
 SG_ DTCI_NVM_TstNCmpltdLstClr : 41|1@0+ (1,0) [0|1] "" TCP,CSM
 SG_ DTCI_NVM_TstFldOpCyc : 42|1@0+ (1,0) [0|1] "" TCP,CSM
 SG_ DTCI_NVM_TstFldLstClr : 43|1@0+ (1,0) [0|1] "" TCP,CSM
 SG_ DTCI_NVM_TstFld : 44|1@0+ (1,0) [0|1] "" TCP,CSM
 SG_ DTCI_NVM_PndngDTC : 45|1@0+ (1,0) [0|1] "" TCP,CSM
 SG_ DTCI_NVM_DTCTriggered : 46|1@0+ (1,0) [0|1] "" TCP,CSM
 SG_ DTCI_NVM_WrnIndTrggrd : 54|1@0+ (1,0) [0|1] "" TCP,CSM
 SG_ DTCI_NVM_WrnIndRqd : 55|1@0+ (1,0) [0|1] "" TCP,CSM

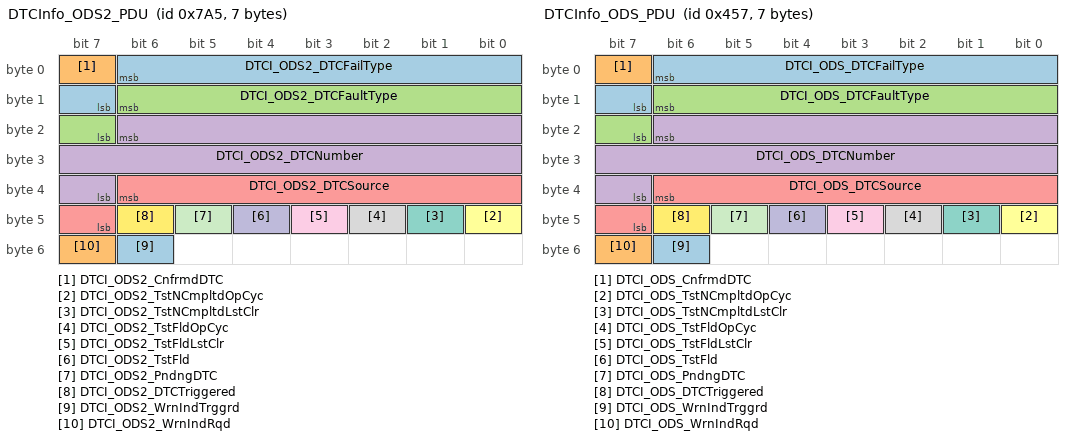
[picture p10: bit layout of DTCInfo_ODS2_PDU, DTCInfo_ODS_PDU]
BO_ 1957 DTCInfo_ODS2_PDU: 7 CGM
 SG_ DTCI_ODS2_DTCFailType : 6|8@0+ (1,0) [0|255] "" TCP
 SG_ DTCI_ODS2_CnfrmdDTC : 7|1@0+ (1,0) [0|1] "" TCP
 SG_ DTCI_ODS2_DTCFaultType : 14|8@0+ (1,0) [0|3] "" TCP
 SG_ DTCI_ODS2_DTCNumber : 22|16@0+ (1,0) [0|65535] "" TCP
 SG_ DTCI_ODS2_DTCSource : 38|8@0+ (1,0) [0|255] "" TCP
 SG_ DTCI_ODS2_TstNCmpltdOpCyc : 40|1@0+ (1,0) [0|1] "" TCP
 SG_ DTCI_ODS2_TstNCmpltdLstClr : 41|1@0+ (1,0) [0|1] "" TCP
 SG_ DTCI_ODS2_TstFldOpCyc : 42|1@0+ (1,0) [0|1] "" TCP
 SG_ DTCI_ODS2_TstFldLstClr : 43|1@0+ (1,0) [0|1] "" TCP
 SG_ DTCI_ODS2_TstFld : 44|1@0+ (1,0) [0|1] "" TCP
 SG_ DTCI_ODS2_PndngDTC : 45|1@0+ (1,0) [0|1] "" TCP
 SG_ DTCI_ODS2_DTCTriggered : 46|1@0+ (1,0) [0|1] "" TCP
 SG_ DTCI_ODS2_WrnIndTrggrd : 54|1@0+ (1,0) [0|1] "" TCP
 SG_ DTCI_ODS2_WrnIndRqd : 55|1@0+ (1,0) [0|1] "" TCP

BO_ 1111 DTCInfo_ODS_PDU: 7 CGM
 SG_ DTCI_ODS_DTCFailType : 6|8@0+ (1,0) [0|255] "" TCP
 SG_ DTCI_ODS_CnfrmdDTC : 7|1@0+ (1,0) [0|1] "" TCP
 SG_ DTCI_ODS_DTCFaultType : 14|8@0+ (1,0) [0|3] "" TCP
 SG_ DTCI_ODS_DTCNumber : 22|16@0+ (1,0) [0|65535] "" TCP
 SG_ DTCI_ODS_DTCSource : 38|8@0+ (1,0) [0|255] "" TCP
 SG_ DTCI_ODS_TstNCmpltdOpCyc : 40|1@0+ (1,0) [0|1] "" TCP
 SG_ DTCI_ODS_TstNCmpltdLstClr : 41|1@0+ (1,0) [0|1] "" TCP
 SG_ DTCI_ODS_TstFldOpCyc : 42|1@0+ (1,0) [0|1] "" TCP
 SG_ DTCI_ODS_TstFldLstClr : 43|1@0+ (1,0) [0|1] "" TCP
 SG_ DTCI_ODS_TstFld : 44|1@0+ (1,0) [0|1] "" TCP
 SG_ DTCI_ODS_PndngDTC : 45|1@0+ (1,0) [0|1] "" TCP
 SG_ DTCI_ODS_DTCTriggered : 46|1@0+ (1,0) [0|1] "" TCP
 SG_ DTCI_ODS_WrnIndTrggrd : 54|1@0+ (1,0) [0|1] "" TCP
 SG_ DTCI_ODS_WrnIndRqd : 55|1@0+ (1,0) [0|1] "" TCP

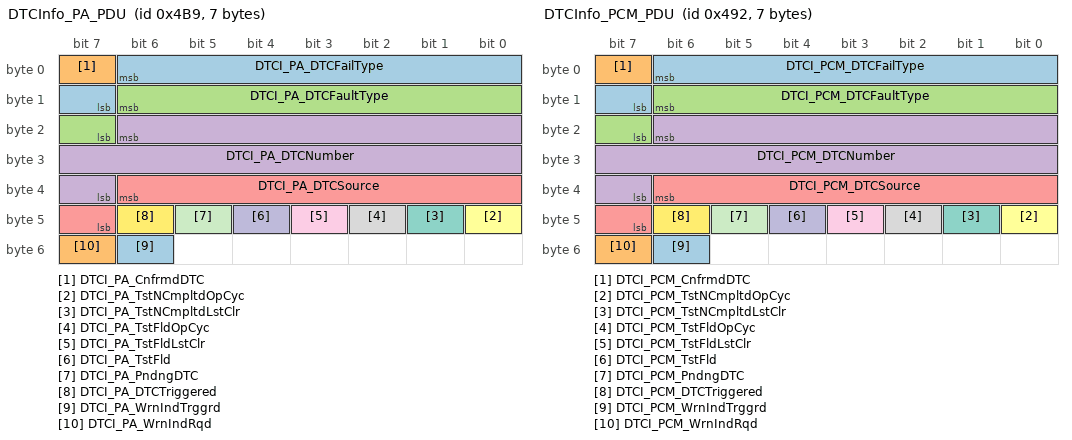
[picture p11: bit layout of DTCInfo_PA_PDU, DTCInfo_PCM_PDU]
BO_ 1209 DTCInfo_PA_PDU: 7 CGM
 SG_ DTCI_PA_DTCFailType : 6|8@0+ (1,0) [0|255] "" TCP,CSM
 SG_ DTCI_PA_CnfrmdDTC : 7|1@0+ (1,0) [0|1] "" TCP,CSM
 SG_ DTCI_PA_DTCFaultType : 14|8@0+ (1,0) [0|3] "" TCP,CSM
 SG_ DTCI_PA_DTCNumber : 22|16@0+ (1,0) [0|65535] "" TCP,CSM
 SG_ DTCI_PA_DTCSource : 38|8@0+ (1,0) [0|255] "" TCP,CSM
 SG_ DTCI_PA_TstNCmpltdOpCyc : 40|1@0+ (1,0) [0|1] "" TCP,CSM
 SG_ DTCI_PA_TstNCmpltdLstClr : 41|1@0+ (1,0) [0|1] "" TCP,CSM
 SG_ DTCI_PA_TstFldOpCyc : 42|1@0+ (1,0) [0|1] "" TCP,CSM
 SG_ DTCI_PA_TstFldLstClr : 43|1@0+ (1,0) [0|1] "" TCP,CSM
 SG_ DTCI_PA_TstFld : 44|1@0+ (1,0) [0|1] "" TCP,CSM
 SG_ DTCI_PA_PndngDTC : 45|1@0+ (1,0) [0|1] "" TCP,CSM
 SG_ DTCI_PA_DTCTriggered : 46|1@0+ (1,0) [0|1] "" TCP,CSM
 SG_ DTCI_PA_WrnIndTrggrd : 54|1@0+ (1,0) [0|1] "" TCP,CSM
 SG_ DTCI_PA_WrnIndRqd : 55|1@0+ (1,0) [0|1] "" TCP,CSM

BO_ 1170 DTCInfo_PCM_PDU: 7 CGM
 SG_ DTCI_PCM_DTCFailType : 6|8@0+ (1,0) [0|255] "" TCP
 SG_ DTCI_PCM_CnfrmdDTC : 7|1@0+ (1,0) [0|1] "" TCP
 SG_ DTCI_PCM_DTCFaultType : 14|8@0+ (1,0) [0|3] "" TCP
 SG_ DTCI_PCM_DTCNumber : 22|16@0+ (1,0) [0|65535] "" TCP
 SG_ DTCI_PCM_DTCSource : 38|8@0+ (1,0) [0|255] "" TCP
 SG_ DTCI_PCM_TstNCmpltdOpCyc : 40|1@0+ (1,0) [0|1] "" TCP
 SG_ DTCI_PCM_TstNCmpltdLstClr : 41|1@0+ (1,0) [0|1] "" TCP
 SG_ DTCI_PCM_TstFldOpCyc : 42|1@0+ (1,0) [0|1] "" TCP
 SG_ DTCI_PCM_TstFldLstClr : 43|1@0+ (1,0) [0|1] "" TCP
 SG_ DTCI_PCM_TstFld : 44|1@0+ (1,0) [0|1] "" TCP
 SG_ DTCI_PCM_PndngDTC : 45|1@0+ (1,0) [0|1] "" TCP
 SG_ DTCI_PCM_DTCTriggered : 46|1@0+ (1,0) [0|1] "" TCP
 SG_ DTCI_PCM_WrnIndTrggrd : 54|1@0+ (1,0) [0|1] "" TCP
 SG_ DTCI_PCM_WrnIndRqd : 55|1@0+ (1,0) [0|1] "" TCP

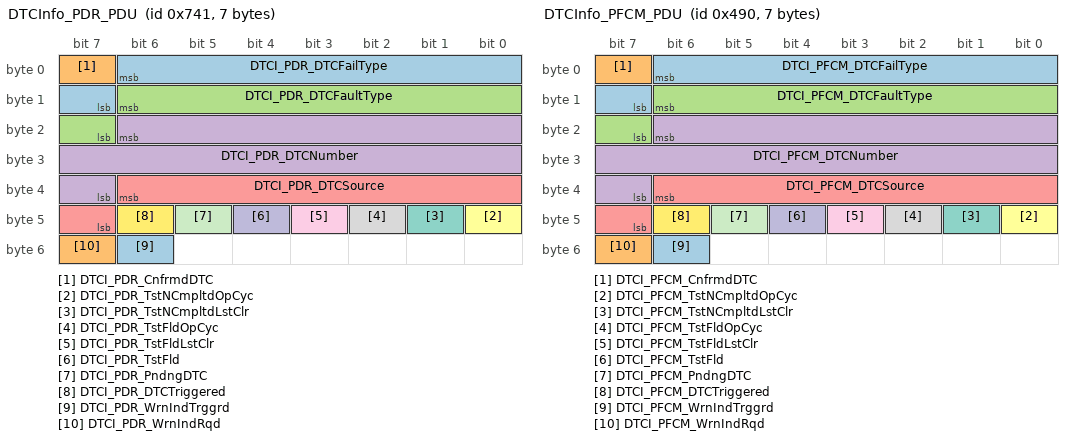
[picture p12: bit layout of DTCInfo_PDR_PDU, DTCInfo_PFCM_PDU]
BO_ 1857 DTCInfo_PDR_PDU: 7 PDR
 SG_ DTCI_PDR_DTCFailType : 6|8@0+ (1,0) [0|255] "" TCP,CSM
 SG_ DTCI_PDR_CnfrmdDTC : 7|1@0+ (1,0) [0|1] "" TCP,CSM
 SG_ DTCI_PDR_DTCFaultType : 14|8@0+ (1,0) [0|3] "" TCP,CSM
 SG_ DTCI_PDR_DTCNumber : 22|16@0+ (1,0) [0|65535] "" TCP,CSM
 SG_ DTCI_PDR_DTCSource : 38|8@0+ (1,0) [0|255] "" CGM,TCP,CSM
 SG_ DTCI_PDR_TstNCmpltdOpCyc : 40|1@0+ (1,0) [0|1] "" TCP,CSM
 SG_ DTCI_PDR_TstNCmpltdLstClr : 41|1@0+ (1,0) [0|1] "" TCP,CSM
 SG_ DTCI_PDR_TstFldOpCyc : 42|1@0+ (1,0) [0|1] "" TCP,CSM
 SG_ DTCI_PDR_TstFldLstClr : 43|1@0+ (1,0) [0|1] "" TCP,CSM
 SG_ DTCI_PDR_TstFld : 44|1@0+ (1,0) [0|1] "" TCP,CSM
 SG_ DTCI_PDR_PndngDTC : 45|1@0+ (1,0) [0|1] "" TCP,CSM
 SG_ DTCI_PDR_DTCTriggered : 46|1@0+ (1,0) [0|1] "" TCP,CSM
 SG_ DTCI_PDR_WrnIndTrggrd : 54|1@0+ (1,0) [0|1] "" TCP,CSM
 SG_ DTCI_PDR_WrnIndRqd : 55|1@0+ (1,0) [0|1] "" TCP,CSM

BO_ 1168 DTCInfo_PFCM_PDU: 7 CGM
 SG_ DTCI_PFCM_DTCFailType : 6|8@0+ (1,0) [0|255] "" TCP
 SG_ DTCI_PFCM_CnfrmdDTC : 7|1@0+ (1,0) [0|1] "" TCP
 SG_ DTCI_PFCM_DTCFaultType : 14|8@0+ (1,0) [0|3] "" TCP
 SG_ DTCI_PFCM_DTCNumber : 22|16@0+ (1,0) [0|65535] "" TCP
 SG_ DTCI_PFCM_DTCSource : 38|8@0+ (1,0) [0|255] "" TCP
 SG_ DTCI_PFCM_TstNCmpltdOpCyc : 40|1@0+ (1,0) [0|1] "" TCP
 SG_ DTCI_PFCM_TstNCmpltdLstClr : 41|1@0+ (1,0) [0|1] "" TCP
 SG_ DTCI_PFCM_TstFldOpCyc : 42|1@0+ (1,0) [0|1] "" TCP
 SG_ DTCI_PFCM_TstFldLstClr : 43|1@0+ (1,0) [0|1] "" TCP
 SG_ DTCI_PFCM_TstFld : 44|1@0+ (1,0) [0|1] "" TCP
 SG_ DTCI_PFCM_PndngDTC : 45|1@0+ (1,0) [0|1] "" TCP
 SG_ DTCI_PFCM_DTCTriggered : 46|1@0+ (1,0) [0|1] "" TCP
 SG_ DTCI_PFCM_WrnIndTrggrd : 54|1@0+ (1,0) [0|1] "" TCP
 SG_ DTCI_PFCM_WrnIndRqd : 55|1@0+ (1,0) [0|1] "" TCP

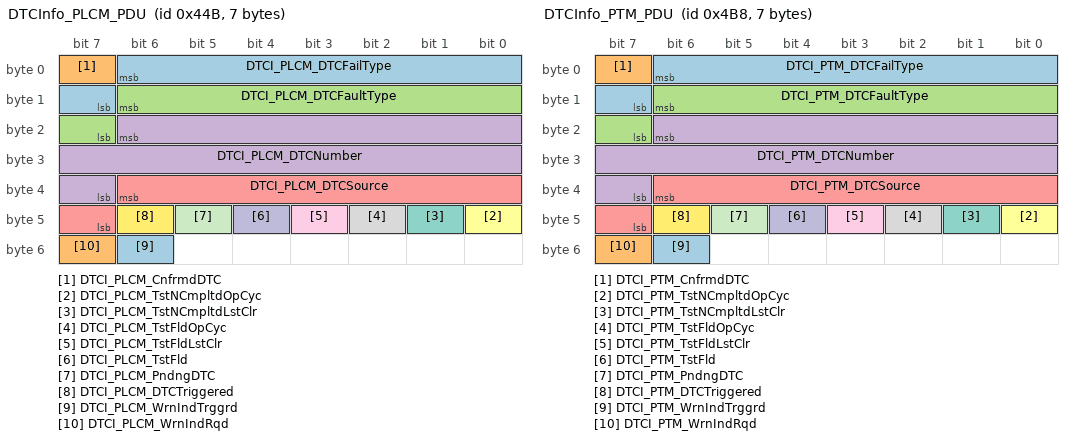
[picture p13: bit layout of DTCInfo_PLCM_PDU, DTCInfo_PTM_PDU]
BO_ 1099 DTCInfo_PLCM_PDU: 7 PLCM
 SG_ DTCI_PLCM_DTCFailType : 6|8@0+ (1,0) [0|255] "" TCP
 SG_ DTCI_PLCM_CnfrmdDTC : 7|1@0+ (1,0) [0|1] "" TCP
 SG_ DTCI_PLCM_DTCFaultType : 14|8@0+ (1,0) [0|3] "" TCP
 SG_ DTCI_PLCM_DTCNumber : 22|16@0+ (1,0) [0|65535] "" TCP
 SG_ DTCI_PLCM_DTCSource : 38|8@0+ (1,0) [0|255] "" CGM,TCP
 SG_ DTCI_PLCM_TstNCmpltdOpCyc : 40|1@0+ (1,0) [0|1] "" TCP
 SG_ DTCI_PLCM_TstNCmpltdLstClr : 41|1@0+ (1,0) [0|1] "" TCP
 SG_ DTCI_PLCM_TstFldOpCyc : 42|1@0+ (1,0) [0|1] "" TCP
 SG_ DTCI_PLCM_TstFldLstClr : 43|1@0+ (1,0) [0|1] "" TCP
 SG_ DTCI_PLCM_TstFld : 44|1@0+ (1,0) [0|1] "" TCP
 SG_ DTCI_PLCM_PndngDTC : 45|1@0+ (1,0) [0|1] "" TCP
 SG_ DTCI_PLCM_DTCTriggered : 46|1@0+ (1,0) [0|1] "" TCP
 SG_ DTCI_PLCM_WrnIndTrggrd : 54|1@0+ (1,0) [0|1] "" TCP
 SG_ DTCI_PLCM_WrnIndRqd : 55|1@0+ (1,0) [0|1] "" TCP

BO_ 1208 DTCInfo_PTM_PDU: 7 CGM
 SG_ DTCI_PTM_DTCFailType : 6|8@0+ (1,0) [0|255] "" TCP,CSM
 SG_ DTCI_PTM_CnfrmdDTC : 7|1@0+ (1,0) [0|1] "" TCP,CSM
 SG_ DTCI_PTM_DTCFaultType : 14|8@0+ (1,0) [0|3] "" TCP,CSM
 SG_ DTCI_PTM_DTCNumber : 22|16@0+ (1,0) [0|65535] "" TCP,CSM
 SG_ DTCI_PTM_DTCSource : 38|8@0+ (1,0) [0|255] "" TCP,CSM
 SG_ DTCI_PTM_TstNCmpltdOpCyc : 40|1@0+ (1,0) [0|1] "" TCP,CSM
 SG_ DTCI_PTM_TstNCmpltdLstClr : 41|1@0+ (1,0) [0|1] "" TCP,CSM
 SG_ DTCI_PTM_TstFldOpCyc : 42|1@0+ (1,0) [0|1] "" TCP,CSM
 SG_ DTCI_PTM_TstFldLstClr : 43|1@0+ (1,0) [0|1] "" TCP,CSM
 SG_ DTCI_PTM_TstFld : 44|1@0+ (1,0) [0|1] "" TCP,CSM
 SG_ DTCI_PTM_PndngDTC : 45|1@0+ (1,0) [0|1] "" TCP,CSM
 SG_ DTCI_PTM_DTCTriggered : 46|1@0+ (1,0) [0|1] "" TCP,CSM
 SG_ DTCI_PTM_WrnIndTrggrd : 54|1@0+ (1,0) [0|1] "" TCP,CSM
 SG_ DTCI_PTM_WrnIndRqd : 55|1@0+ (1,0) [0|1] "" TCP,CSM

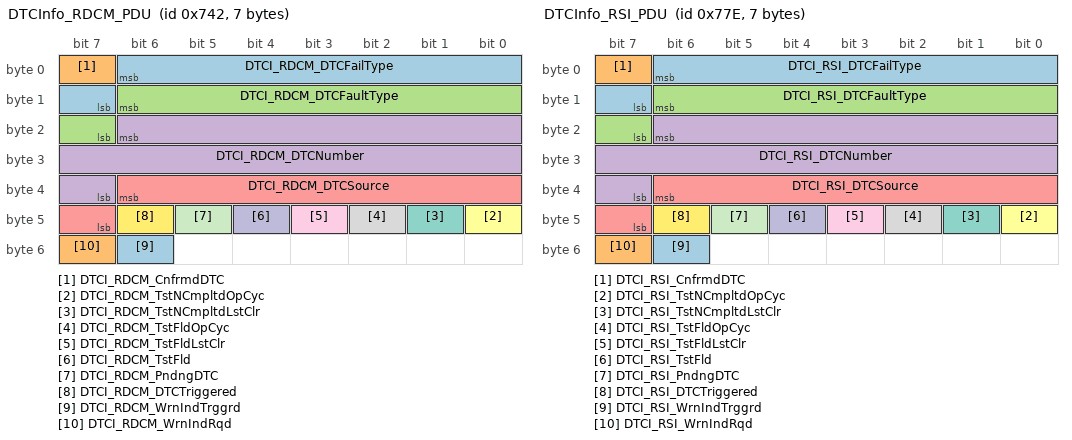
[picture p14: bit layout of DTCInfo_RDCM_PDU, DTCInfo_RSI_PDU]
BO_ 1858 DTCInfo_RDCM_PDU: 7 CGM
 SG_ DTCI_RDCM_DTCFailType : 6|8@0+ (1,0) [0|255] "" TCP,CSM
 SG_ DTCI_RDCM_CnfrmdDTC : 7|1@0+ (1,0) [0|1] "" TCP,CSM
 SG_ DTCI_RDCM_DTCFaultType : 14|8@0+ (1,0) [0|3] "" TCP,CSM
 SG_ DTCI_RDCM_DTCNumber : 22|16@0+ (1,0) [0|65535] "" TCP,CSM
 SG_ DTCI_RDCM_DTCSource : 38|8@0+ (1,0) [0|255] "" TCP,CSM
 SG_ DTCI_RDCM_TstNCmpltdOpCyc : 40|1@0+ (1,0) [0|1] "" TCP,CSM
 SG_ DTCI_RDCM_TstNCmpltdLstClr : 41|1@0+ (1,0) [0|1] "" TCP,CSM
 SG_ DTCI_RDCM_TstFldOpCyc : 42|1@0+ (1,0) [0|1] "" TCP,CSM
 SG_ DTCI_RDCM_TstFldLstClr : 43|1@0+ (1,0) [0|1] "" TCP,CSM
 SG_ DTCI_RDCM_TstFld : 44|1@0+ (1,0) [0|1] "" TCP,CSM
 SG_ DTCI_RDCM_PndngDTC : 45|1@0+ (1,0) [0|1] "" TCP,CSM
 SG_ DTCI_RDCM_DTCTriggered : 46|1@0+ (1,0) [0|1] "" TCP,CSM
 SG_ DTCI_RDCM_WrnIndTrggrd : 54|1@0+ (1,0) [0|1] "" TCP,CSM
 SG_ DTCI_RDCM_WrnIndRqd : 55|1@0+ (1,0) [0|1] "" TCP,CSM

BO_ 1918 DTCInfo_RSI_PDU: 7 RSI
 SG_ DTCI_RSI_DTCFailType : 6|8@0+ (1,0) [0|255] "" TCP
 SG_ DTCI_RSI_CnfrmdDTC : 7|1@0+ (1,0) [0|1] "" TCP
 SG_ DTCI_RSI_DTCFaultType : 14|8@0+ (1,0) [0|3] "" TCP
 SG_ DTCI_RSI_DTCNumber : 22|16@0+ (1,0) [0|65535] "" TCP
 SG_ DTCI_RSI_DTCSource : 38|8@0+ (1,0) [0|255] "" CGM,TCP
 SG_ DTCI_RSI_TstNCmpltdOpCyc : 40|1@0+ (1,0) [0|1] "" TCP
 SG_ DTCI_RSI_TstNCmpltdLstClr : 41|1@0+ (1,0) [0|1] "" TCP
 SG_ DTCI_RSI_TstFldOpCyc : 42|1@0+ (1,0) [0|1] "" TCP
 SG_ DTCI_RSI_TstFldLstClr : 43|1@0+ (1,0) [0|1] "" TCP
 SG_ DTCI_RSI_TstFld : 44|1@0+ (1,0) [0|1] "" TCP
 SG_ DTCI_RSI_PndngDTC : 45|1@0+ (1,0) [0|1] "" TCP
 SG_ DTCI_RSI_DTCTriggered : 46|1@0+ (1,0) [0|1] "" TCP
 SG_ DTCI_RSI_WrnIndTrggrd : 54|1@0+ (1,0) [0|1] "" TCP
 SG_ DTCI_RSI_WrnIndRqd : 55|1@0+ (1,0) [0|1] "" TCP

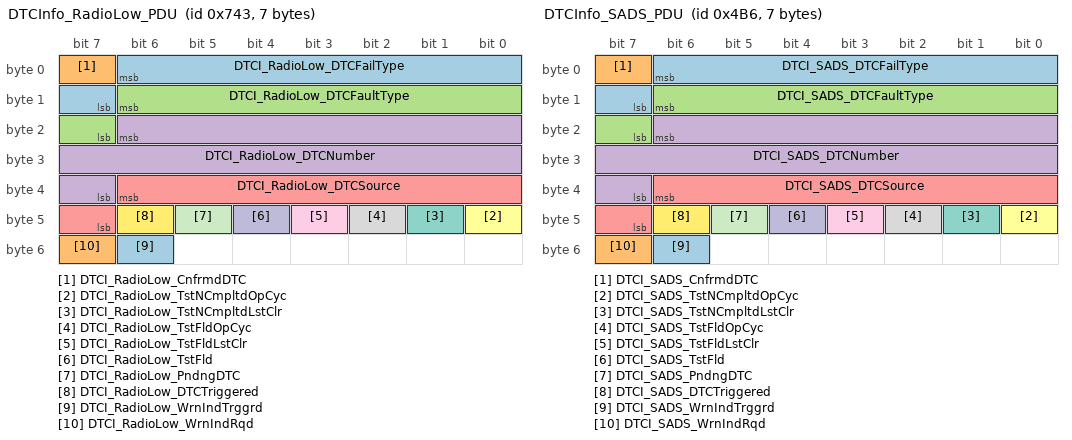
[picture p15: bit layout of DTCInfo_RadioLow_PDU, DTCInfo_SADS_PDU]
BO_ 1859 DTCInfo_RadioLow_PDU: 7 RadioLow
 SG_ DTCI_RadioLow_DTCFailType : 6|8@0+ (1,0) [0|255] "" TCP,CSM
 SG_ DTCI_RadioLow_CnfrmdDTC : 7|1@0+ (1,0) [0|1] "" TCP,CSM
 SG_ DTCI_RadioLow_DTCFaultType : 14|8@0+ (1,0) [0|3] "" TCP,CSM
 SG_ DTCI_RadioLow_DTCNumber : 22|16@0+ (1,0) [0|65535] "" TCP,CSM
 SG_ DTCI_RadioLow_DTCSource : 38|8@0+ (1,0) [0|255] "" CGM,TCP,CSM
 SG_ DTCI_RadioLow_TstNCmpltdOpCyc : 40|1@0+ (1,0) [0|1] "" TCP,CSM
 SG_ DTCI_RadioLow_TstNCmpltdLstClr : 41|1@0+ (1,0) [0|1] "" TCP,CSM
 SG_ DTCI_RadioLow_TstFldOpCyc : 42|1@0+ (1,0) [0|1] "" TCP,CSM
 SG_ DTCI_RadioLow_TstFldLstClr : 43|1@0+ (1,0) [0|1] "" TCP,CSM
 SG_ DTCI_RadioLow_TstFld : 44|1@0+ (1,0) [0|1] "" TCP,CSM
 SG_ DTCI_RadioLow_PndngDTC : 45|1@0+ (1,0) [0|1] "" TCP,CSM
 SG_ DTCI_RadioLow_DTCTriggered : 46|1@0+ (1,0) [0|1] "" TCP,CSM
 SG_ DTCI_RadioLow_WrnIndTrggrd : 54|1@0+ (1,0) [0|1] "" TCP,CSM
 SG_ DTCI_RadioLow_WrnIndRqd : 55|1@0+ (1,0) [0|1] "" TCP,CSM

BO_ 1206 DTCInfo_SADS_PDU: 7 CGM
 SG_ DTCI_SADS_DTCFailType : 6|8@0+ (1,0) [0|255] "" TCP,CSM
 SG_ DTCI_SADS_CnfrmdDTC : 7|1@0+ (1,0) [0|1] "" TCP,CSM
 SG_ DTCI_SADS_DTCFaultType : 14|8@0+ (1,0) [0|3] "" TCP,CSM
 SG_ DTCI_SADS_DTCNumber : 22|16@0+ (1,0) [0|65535] "" TCP,CSM
 SG_ DTCI_SADS_DTCSource : 38|8@0+ (1,0) [0|255] "" TCP,CSM
 SG_ DTCI_SADS_TstNCmpltdOpCyc : 40|1@0+ (1,0) [0|1] "" TCP,CSM
 SG_ DTCI_SADS_TstNCmpltdLstClr : 41|1@0+ (1,0) [0|1] "" TCP,CSM
 SG_ DTCI_SADS_TstFldOpCyc : 42|1@0+ (1,0) [0|1] "" TCP,CSM
 SG_ DTCI_SADS_TstFldLstClr : 43|1@0+ (1,0) [0|1] "" TCP,CSM
 SG_ DTCI_SADS_TstFld : 44|1@0+ (1,0) [0|1] "" TCP,CSM
 SG_ DTCI_SADS_PndngDTC : 45|1@0+ (1,0) [0|1] "" TCP,CSM
 SG_ DTCI_SADS_DTCTriggered : 46|1@0+ (1,0) [0|1] "" TCP,CSM
 SG_ DTCI_SADS_WrnIndTrggrd : 54|1@0+ (1,0) [0|1] "" TCP,CSM
 SG_ DTCI_SADS_WrnIndRqd : 55|1@0+ (1,0) [0|1] "" TCP,CSM

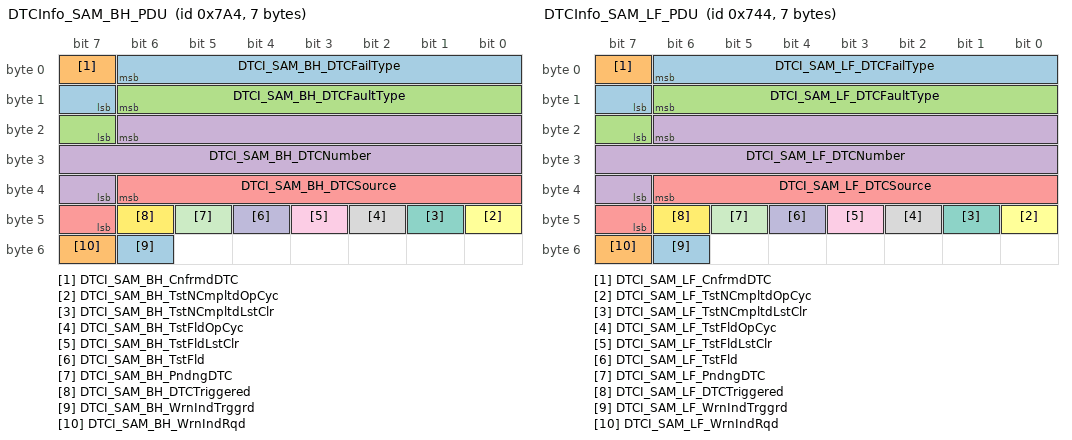
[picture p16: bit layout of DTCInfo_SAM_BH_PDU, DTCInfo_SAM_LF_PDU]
BO_ 1956 DTCInfo_SAM_BH_PDU: 7 CGM
 SG_ DTCI_SAM_BH_DTCFailType : 6|8@0+ (1,0) [0|255] "" TCP
 SG_ DTCI_SAM_BH_CnfrmdDTC : 7|1@0+ (1,0) [0|1] "" TCP
 SG_ DTCI_SAM_BH_DTCFaultType : 14|8@0+ (1,0) [0|3] "" TCP
 SG_ DTCI_SAM_BH_DTCNumber : 22|16@0+ (1,0) [0|65535] "" TCP
 SG_ DTCI_SAM_BH_DTCSource : 38|8@0+ (1,0) [0|255] "" TCP
 SG_ DTCI_SAM_BH_TstNCmpltdOpCyc : 40|1@0+ (1,0) [0|1] "" TCP
 SG_ DTCI_SAM_BH_TstNCmpltdLstClr : 41|1@0+ (1,0) [0|1] "" TCP
 SG_ DTCI_SAM_BH_TstFldOpCyc : 42|1@0+ (1,0) [0|1] "" TCP
 SG_ DTCI_SAM_BH_TstFldLstClr : 43|1@0+ (1,0) [0|1] "" TCP
 SG_ DTCI_SAM_BH_TstFld : 44|1@0+ (1,0) [0|1] "" TCP
 SG_ DTCI_SAM_BH_PndngDTC : 45|1@0+ (1,0) [0|1] "" TCP
 SG_ DTCI_SAM_BH_DTCTriggered : 46|1@0+ (1,0) [0|1] "" TCP
 SG_ DTCI_SAM_BH_WrnIndTrggrd : 54|1@0+ (1,0) [0|1] "" TCP
 SG_ DTCI_SAM_BH_WrnIndRqd : 55|1@0+ (1,0) [0|1] "" TCP

BO_ 1860 DTCInfo_SAM_LF_PDU: 7 CGM
 SG_ DTCI_SAM_LF_DTCFailType : 6|8@0+ (1,0) [0|255] "" TCP
 SG_ DTCI_SAM_LF_CnfrmdDTC : 7|1@0+ (1,0) [0|1] "" TCP
 SG_ DTCI_SAM_LF_DTCFaultType : 14|8@0+ (1,0) [0|3] "" TCP
 SG_ DTCI_SAM_LF_DTCNumber : 22|16@0+ (1,0) [0|65535] "" TCP
 SG_ DTCI_SAM_LF_DTCSource : 38|8@0+ (1,0) [0|255] "" TCP
 SG_ DTCI_SAM_LF_TstNCmpltdOpCyc : 40|1@0+ (1,0) [0|1] "" TCP
 SG_ DTCI_SAM_LF_TstNCmpltdLstClr : 41|1@0+ (1,0) [0|1] "" TCP
 SG_ DTCI_SAM_LF_TstFldOpCyc : 42|1@0+ (1,0) [0|1] "" TCP
 SG_ DTCI_SAM_LF_TstFldLstClr : 43|1@0+ (1,0) [0|1] "" TCP
 SG_ DTCI_SAM_LF_TstFld : 44|1@0+ (1,0) [0|1] "" TCP
 SG_ DTCI_SAM_LF_PndngDTC : 45|1@0+ (1,0) [0|1] "" TCP
 SG_ DTCI_SAM_LF_DTCTriggered : 46|1@0+ (1,0) [0|1] "" TCP
 SG_ DTCI_SAM_LF_WrnIndTrggrd : 54|1@0+ (1,0) [0|1] "" TCP
 SG_ DTCI_SAM_LF_WrnIndRqd : 55|1@0+ (1,0) [0|1] "" TCP

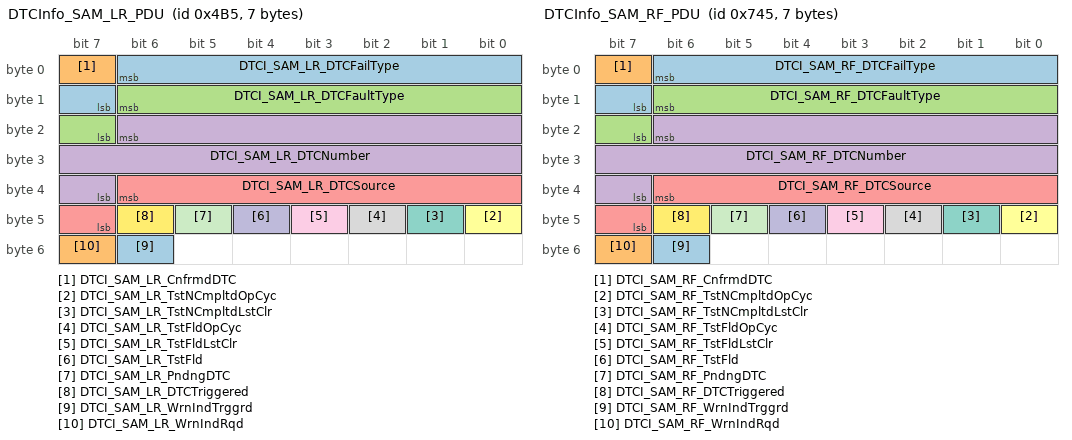
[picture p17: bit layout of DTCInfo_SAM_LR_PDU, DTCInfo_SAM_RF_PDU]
BO_ 1205 DTCInfo_SAM_LR_PDU: 7 CGM
 SG_ DTCI_SAM_LR_DTCFailType : 6|8@0+ (1,0) [0|255] "" TCP
 SG_ DTCI_SAM_LR_CnfrmdDTC : 7|1@0+ (1,0) [0|1] "" TCP
 SG_ DTCI_SAM_LR_DTCFaultType : 14|8@0+ (1,0) [0|3] "" TCP
 SG_ DTCI_SAM_LR_DTCNumber : 22|16@0+ (1,0) [0|65535] "" TCP
 SG_ DTCI_SAM_LR_DTCSource : 38|8@0+ (1,0) [0|255] "" TCP
 SG_ DTCI_SAM_LR_TstNCmpltdOpCyc : 40|1@0+ (1,0) [0|1] "" TCP
 SG_ DTCI_SAM_LR_TstNCmpltdLstClr : 41|1@0+ (1,0) [0|1] "" TCP
 SG_ DTCI_SAM_LR_TstFldOpCyc : 42|1@0+ (1,0) [0|1] "" TCP
 SG_ DTCI_SAM_LR_TstFldLstClr : 43|1@0+ (1,0) [0|1] "" TCP
 SG_ DTCI_SAM_LR_TstFld : 44|1@0+ (1,0) [0|1] "" TCP
 SG_ DTCI_SAM_LR_PndngDTC : 45|1@0+ (1,0) [0|1] "" TCP
 SG_ DTCI_SAM_LR_DTCTriggered : 46|1@0+ (1,0) [0|1] "" TCP
 SG_ DTCI_SAM_LR_WrnIndTrggrd : 54|1@0+ (1,0) [0|1] "" TCP
 SG_ DTCI_SAM_LR_WrnIndRqd : 55|1@0+ (1,0) [0|1] "" TCP

BO_ 1861 DTCInfo_SAM_RF_PDU: 7 CGM
 SG_ DTCI_SAM_RF_DTCFailType : 6|8@0+ (1,0) [0|255] "" TCP
 SG_ DTCI_SAM_RF_CnfrmdDTC : 7|1@0+ (1,0) [0|1] "" TCP
 SG_ DTCI_SAM_RF_DTCFaultType : 14|8@0+ (1,0) [0|3] "" TCP
 SG_ DTCI_SAM_RF_DTCNumber : 22|16@0+ (1,0) [0|65535] "" TCP
 SG_ DTCI_SAM_RF_DTCSource : 38|8@0+ (1,0) [0|255] "" TCP
 SG_ DTCI_SAM_RF_TstNCmpltdOpCyc : 40|1@0+ (1,0) [0|1] "" TCP
 SG_ DTCI_SAM_RF_TstNCmpltdLstClr : 41|1@0+ (1,0) [0|1] "" TCP
 SG_ DTCI_SAM_RF_TstFldOpCyc : 42|1@0+ (1,0) [0|1] "" TCP
 SG_ DTCI_SAM_RF_TstFldLstClr : 43|1@0+ (1,0) [0|1] "" TCP
 SG_ DTCI_SAM_RF_TstFld : 44|1@0+ (1,0) [0|1] "" TCP
 SG_ DTCI_SAM_RF_PndngDTC : 45|1@0+ (1,0) [0|1] "" TCP
 SG_ DTCI_SAM_RF_DTCTriggered : 46|1@0+ (1,0) [0|1] "" TCP
 SG_ DTCI_SAM_RF_WrnIndTrggrd : 54|1@0+ (1,0) [0|1] "" TCP
 SG_ DTCI_SAM_RF_WrnIndRqd : 55|1@0+ (1,0) [0|1] "" TCP

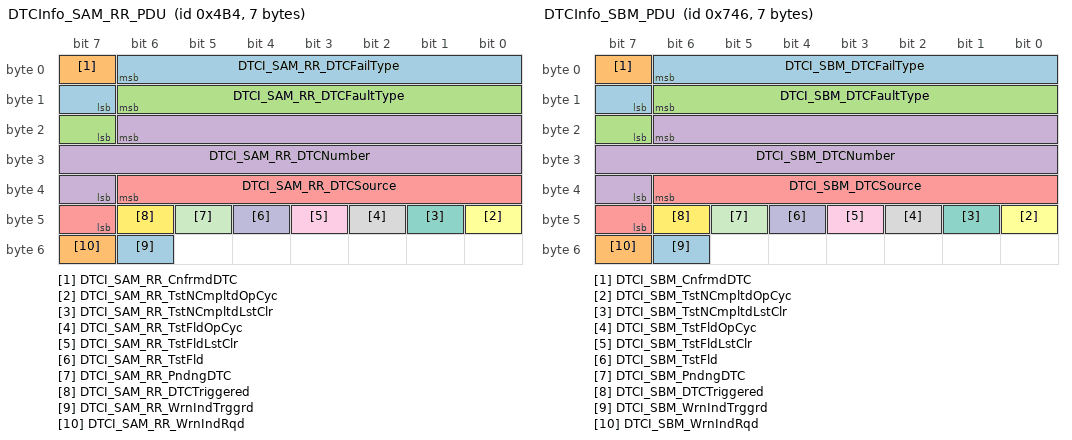
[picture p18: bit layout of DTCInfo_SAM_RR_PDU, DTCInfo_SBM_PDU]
BO_ 1204 DTCInfo_SAM_RR_PDU: 7 CGM
 SG_ DTCI_SAM_RR_DTCFailType : 6|8@0+ (1,0) [0|255] "" TCP
 SG_ DTCI_SAM_RR_CnfrmdDTC : 7|1@0+ (1,0) [0|1] "" TCP
 SG_ DTCI_SAM_RR_DTCFaultType : 14|8@0+ (1,0) [0|3] "" TCP
 SG_ DTCI_SAM_RR_DTCNumber : 22|16@0+ (1,0) [0|65535] "" TCP
 SG_ DTCI_SAM_RR_DTCSource : 38|8@0+ (1,0) [0|255] "" TCP
 SG_ DTCI_SAM_RR_TstNCmpltdOpCyc : 40|1@0+ (1,0) [0|1] "" TCP
 SG_ DTCI_SAM_RR_TstNCmpltdLstClr : 41|1@0+ (1,0) [0|1] "" TCP
 SG_ DTCI_SAM_RR_TstFldOpCyc : 42|1@0+ (1,0) [0|1] "" TCP
 SG_ DTCI_SAM_RR_TstFldLstClr : 43|1@0+ (1,0) [0|1] "" TCP
 SG_ DTCI_SAM_RR_TstFld : 44|1@0+ (1,0) [0|1] "" TCP
 SG_ DTCI_SAM_RR_PndngDTC : 45|1@0+ (1,0) [0|1] "" TCP
 SG_ DTCI_SAM_RR_DTCTriggered : 46|1@0+ (1,0) [0|1] "" TCP
 SG_ DTCI_SAM_RR_WrnIndTrggrd : 54|1@0+ (1,0) [0|1] "" TCP
 SG_ DTCI_SAM_RR_WrnIndRqd : 55|1@0+ (1,0) [0|1] "" TCP

BO_ 1862 DTCInfo_SBM_PDU: 7 CGM
 SG_ DTCI_SBM_DTCFailType : 6|8@0+ (1,0) [0|255] "" TCP,CSM
 SG_ DTCI_SBM_CnfrmdDTC : 7|1@0+ (1,0) [0|1] "" TCP,CSM
 SG_ DTCI_SBM_DTCFaultType : 14|8@0+ (1,0) [0|3] "" TCP,CSM
 SG_ DTCI_SBM_DTCNumber : 22|16@0+ (1,0) [0|65535] "" TCP,CSM
 SG_ DTCI_SBM_DTCSource : 38|8@0+ (1,0) [0|255] "" TCP,CSM
 SG_ DTCI_SBM_TstNCmpltdOpCyc : 40|1@0+ (1,0) [0|1] "" TCP,CSM
 SG_ DTCI_SBM_TstNCmpltdLstClr : 41|1@0+ (1,0) [0|1] "" TCP,CSM
 SG_ DTCI_SBM_TstFldOpCyc : 42|1@0+ (1,0) [0|1] "" TCP,CSM
 SG_ DTCI_SBM_TstFldLstClr : 43|1@0+ (1,0) [0|1] "" TCP,CSM
 SG_ DTCI_SBM_TstFld : 44|1@0+ (1,0) [0|1] "" TCP,CSM
 SG_ DTCI_SBM_PndngDTC : 45|1@0+ (1,0) [0|1] "" TCP,CSM
 SG_ DTCI_SBM_DTCTriggered : 46|1@0+ (1,0) [0|1] "" TCP,CSM
 SG_ DTCI_SBM_WrnIndTrggrd : 54|1@0+ (1,0) [0|1] "" TCP,CSM
 SG_ DTCI_SBM_WrnIndRqd : 55|1@0+ (1,0) [0|1] "" TCP,CSM

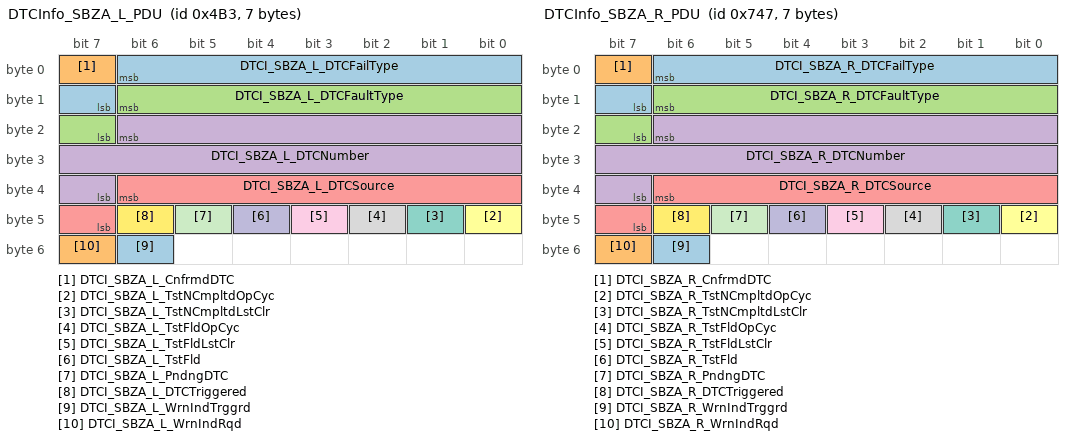
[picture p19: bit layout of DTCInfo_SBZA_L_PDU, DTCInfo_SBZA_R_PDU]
BO_ 1203 DTCInfo_SBZA_L_PDU: 7 CGM
 SG_ DTCI_SBZA_L_DTCFailType : 6|8@0+ (1,0) [0|255] "" TCP,CSM
 SG_ DTCI_SBZA_L_CnfrmdDTC : 7|1@0+ (1,0) [0|1] "" TCP,CSM
 SG_ DTCI_SBZA_L_DTCFaultType : 14|8@0+ (1,0) [0|3] "" TCP,CSM
 SG_ DTCI_SBZA_L_DTCNumber : 22|16@0+ (1,0) [0|65535] "" TCP,CSM
 SG_ DTCI_SBZA_L_DTCSource : 38|8@0+ (1,0) [0|255] "" TCP,CSM
 SG_ DTCI_SBZA_L_TstNCmpltdOpCyc : 40|1@0+ (1,0) [0|1] "" TCP,CSM
 SG_ DTCI_SBZA_L_TstNCmpltdLstClr : 41|1@0+ (1,0) [0|1] "" TCP,CSM
 SG_ DTCI_SBZA_L_TstFldOpCyc : 42|1@0+ (1,0) [0|1] "" TCP,CSM
 SG_ DTCI_SBZA_L_TstFldLstClr : 43|1@0+ (1,0) [0|1] "" TCP,CSM
 SG_ DTCI_SBZA_L_TstFld : 44|1@0+ (1,0) [0|1] "" TCP,CSM
 SG_ DTCI_SBZA_L_PndngDTC : 45|1@0+ (1,0) [0|1] "" TCP,CSM
 SG_ DTCI_SBZA_L_DTCTriggered : 46|1@0+ (1,0) [0|1] "" TCP,CSM
 SG_ DTCI_SBZA_L_WrnIndTrggrd : 54|1@0+ (1,0) [0|1] "" TCP,CSM
 SG_ DTCI_SBZA_L_WrnIndRqd : 55|1@0+ (1,0) [0|1] "" TCP,CSM

BO_ 1863 DTCInfo_SBZA_R_PDU: 7 CGM
 SG_ DTCI_SBZA_R_DTCFailType : 6|8@0+ (1,0) [0|255] "" TCP,CSM
 SG_ DTCI_SBZA_R_CnfrmdDTC : 7|1@0+ (1,0) [0|1] "" TCP,CSM
 SG_ DTCI_SBZA_R_DTCFaultType : 14|8@0+ (1,0) [0|3] "" TCP,CSM
 SG_ DTCI_SBZA_R_DTCNumber : 22|16@0+ (1,0) [0|65535] "" TCP,CSM
 SG_ DTCI_SBZA_R_DTCSource : 38|8@0+ (1,0) [0|255] "" TCP,CSM
 SG_ DTCI_SBZA_R_TstNCmpltdOpCyc : 40|1@0+ (1,0) [0|1] "" TCP,CSM
 SG_ DTCI_SBZA_R_TstNCmpltdLstClr : 41|1@0+ (1,0) [0|1] "" TCP,CSM
 SG_ DTCI_SBZA_R_TstFldOpCyc : 42|1@0+ (1,0) [0|1] "" TCP,CSM
 SG_ DTCI_SBZA_R_TstFldLstClr : 43|1@0+ (1,0) [0|1] "" TCP,CSM
 SG_ DTCI_SBZA_R_TstFld : 44|1@0+ (1,0) [0|1] "" TCP,CSM
 SG_ DTCI_SBZA_R_PndngDTC : 45|1@0+ (1,0) [0|1] "" TCP,CSM
 SG_ DTCI_SBZA_R_DTCTriggered : 46|1@0+ (1,0) [0|1] "" TCP,CSM
 SG_ DTCI_SBZA_R_WrnIndTrggrd : 54|1@0+ (1,0) [0|1] "" TCP,CSM
 SG_ DTCI_SBZA_R_WrnIndRqd : 55|1@0+ (1,0) [0|1] "" TCP,CSM

BO_ 1202 DTCInfo_SCL_PDU: 7 CGM
 SG_ DTCI_SCL_DTCFailType : 6|8@0+ (1,0) [0|255] "" TCP,CSM
 SG_ DTCI_SCL_CnfrmdDTC : 7|1@0+ (1,0) [0|1] "" TCP,CSM
 SG_ DTCI_SCL_DTCFaultType : 14|8@0+ (1,0) [0|3] "" TCP,CSM
 SG_ DTCI_SCL_DTCNumber : 22|16@0+ (1,0) [0|65535] "" TCP,CSM
 SG_ DTCI_SCL_DTCSource : 38|8@0+ (1,0) [0|255] "" TCP,CSM
 SG_ DTCI_SCL_TstNCmpltdOpCyc : 40|1@0+ (1,0) [0|1] "" TCP,CSM
 SG_ DTCI_SCL_TstNCmpltdLstClr : 41|1@0+ (1,0) [0|1] "" TCP,CSM
 SG_ DTCI_SCL_TstFldOpCyc : 42|1@0+ (1,0) [0|1] "" TCP,CSM
 SG_ DTCI_SCL_TstFldLstClr : 43|1@0+ (1,0) [0|1] "" TCP,CSM
 SG_ DTCI_SCL_TstFld : 44|1@0+ (1,0) [0|1] "" TCP,CSM
 SG_ DTCI_SCL_PndngDTC : 45|1@0+ (1,0) [0|1] "" TCP,CSM
 SG_ DTCI_SCL_DTCTriggered : 46|1@0+ (1,0) [0|1] "" TCP,CSM
 SG_ DTCI_SCL_WrnIndTrggrd : 54|1@0+ (1,0) [0|1] "" TCP,CSM
 SG_ DTCI_SCL_WrnIndRqd : 55|1@0+ (1,0) [0|1] "" TCP,CSM

BO_ 1919 DTCInfo_SDM_AV_PDU: 7 CGM
 SG_ DTCI_SDM_AV_DTCFailType : 6|8@0+ (1,0) [0|255] "" TCP
 SG_ DTCI_SDM_AV_CnfrmdDTC : 7|1@0+ (1,0) [0|1] "" TCP
 SG_ DTCI_SDM_AV_DTCFaultType : 14|8@0+ (1,0) [0|3] "" TCP
 SG_ DTCI_SDM_AV_DTCNumber : 22|16@0+ (1,0) [0|65535] "" TCP
 SG_ DTCI_SDM_AV_DTCSource : 38|8@0+ (1,0) [0|255] "" TCP
 SG_ DTCI_SDM_AV_TstNCmpltdOpCyc : 40|1@0+ (1,0) [0|1] "" TCP
 SG_ DTCI_SDM_AV_TstNCmpltdLstClr : 41|1@0+ (1,0) [0|1] "" TCP
 SG_ DTCI_SDM_AV_TstFldOpCyc : 42|1@0+ (1,0) [0|1] "" TCP
 SG_ DTCI_SDM_AV_TstFldLstClr : 43|1@0+ (1,0) [0|1] "" TCP
 SG_ DTCI_SDM_AV_TstFld : 44|1@0+ (1,0) [0|1] "" TCP
 SG_ DTCI_SDM_AV_PndngDTC : 45|1@0+ (1,0) [0|1] "" TCP
 SG_ DTCI_SDM_AV_DTCTriggered : 46|1@0+ (1,0) [0|1] "" TCP
 SG_ DTCI_SDM_AV_WrnIndTrggrd : 54|1@0+ (1,0) [0|1] "" TCP
 SG_ DTCI_SDM_AV_WrnIndRqd : 55|1@0+ (1,0) [0|1] "" TCP

BO_ 1864 DTCInfo_SDM_PDU: 7 CGM
 SG_ DTCI_SDM_DTCFailType : 6|8@0+ (1,0) [0|255] "" TCP,CSM
 SG_ DTCI_SDM_CnfrmdDTC : 7|1@0+ (1,0) [0|1] "" TCP,CSM
 SG_ DTCI_SDM_DTCFaultType : 14|8@0+ (1,0) [0|3] "" TCP,CSM
 SG_ DTCI_SDM_DTCNumber : 22|16@0+ (1,0) [0|65535] "" TCP,CSM
 SG_ DTCI_SDM_DTCSource : 38|8@0+ (1,0) [0|255] "" TCP,CSM
 SG_ DTCI_SDM_TstNCmpltdOpCyc : 40|1@0+ (1,0) [0|1] "" TCP,CSM
 SG_ DTCI_SDM_TstNCmpltdLstClr : 41|1@0+ (1,0) [0|1] "" TCP,CSM
 SG_ DTCI_SDM_TstFldOpCyc : 42|1@0+ (1,0) [0|1] "" TCP,CSM
 SG_ DTCI_SDM_TstFldLstClr : 43|1@0+ (1,0) [0|1] "" TCP,CSM
 SG_ DTCI_SDM_TstFld : 44|1@0+ (1,0) [0|1] "" TCP,CSM
 SG_ DTCI_SDM_PndngDTC : 45|1@0+ (1,0) [0|1] "" TCP,CSM
 SG_ DTCI_SDM_DTCTriggered : 46|1@0+ (1,0) [0|1] "" TCP,CSM
 SG_ DTCI_SDM_WrnIndTrggrd : 54|1@0+ (1,0) [0|1] "" TCP,CSM
 SG_ DTCI_SDM_WrnIndRqd : 55|1@0+ (1,0) [0|1] "" TCP,CSM

BO_ 1201 DTCInfo_SIB_PDU: 7 CGM
 SG_ DTCI_SIB_DTCFailType : 6|8@0+ (1,0) [0|255] "" TCP,CSM
 SG_ DTCI_SIB_CnfrmdDTC : 7|1@0+ (1,0) [0|1] "" TCP,CSM
 SG_ DTCI_SIB_DTCFaultType : 14|8@0+ (1,0) [0|3] "" TCP,CSM
 SG_ DTCI_SIB_DTCNumber : 22|16@0+ (1,0) [0|65535] "" TCP,CSM
 SG_ DTCI_SIB_DTCSource : 38|8@0+ (1,0) [0|255] "" TCP,CSM
 SG_ DTCI_SIB_TstNCmpltdOpCyc : 40|1@0+ (1,0) [0|1] "" TCP,CSM
 SG_ DTCI_SIB_TstNCmpltdLstClr : 41|1@0+ (1,0) [0|1] "" TCP,CSM
 SG_ DTCI_SIB_TstFldOpCyc : 42|1@0+ (1,0) [0|1] "" TCP,CSM
 SG_ DTCI_SIB_TstFldLstClr : 43|1@0+ (1,0) [0|1] "" TCP,CSM
 SG_ DTCI_SIB_TstFld : 44|1@0+ (1,0) [0|1] "" TCP,CSM
 SG_ DTCI_SIB_PndngDTC : 45|1@0+ (1,0) [0|1] "" TCP,CSM
 SG_ DTCI_SIB_DTCTriggered : 46|1@0+ (1,0) [0|1] "" TCP,CSM
 SG_ DTCI_SIB_WrnIndTrggrd : 54|1@0+ (1,0) [0|1] "" TCP,CSM
 SG_ DTCI_SIB_WrnIndRqd : 55|1@0+ (1,0) [0|1] "" TCP,CSM

BO_ 1865 DTCInfo_SRR_LF_PDU: 7 CGM
 SG_ DTCI_SRR_LF_DTCFailType : 6|8@0+ (1,0) [0|255] "" TCP,CSM
 SG_ DTCI_SRR_LF_CnfrmdDTC : 7|1@0+ (1,0) [0|1] "" TCP,CSM
 SG_ DTCI_SRR_LF_DTCFaultType : 14|8@0+ (1,0) [0|3] "" TCP,CSM
 SG_ DTCI_SRR_LF_DTCNumber : 22|16@0+ (1,0) [0|65535] "" TCP,CSM
 SG_ DTCI_SRR_LF_DTCSource : 38|8@0+ (1,0) [0|255] "" TCP,CSM
 SG_ DTCI_SRR_LF_TstNCmpltdOpCyc : 40|1@0+ (1,0) [0|1] "" TCP,CSM
 SG_ DTCI_SRR_LF_TstNCmpltdLstClr : 41|1@0+ (1,0) [0|1] "" TCP,CSM
 SG_ DTCI_SRR_LF_TstFldOpCyc : 42|1@0+ (1,0) [0|1] "" TCP,CSM
 SG_ DTCI_SRR_LF_TstFldLstClr : 43|1@0+ (1,0) [0|1] "" TCP,CSM
 SG_ DTCI_SRR_LF_TstFld : 44|1@0+ (1,0) [0|1] "" TCP,CSM
 SG_ DTCI_SRR_LF_PndngDTC : 45|1@0+ (1,0) [0|1] "" TCP,CSM
 SG_ DTCI_SRR_LF_DTCTriggered : 46|1@0+ (1,0) [0|1] "" TCP,CSM
 SG_ DTCI_SRR_LF_WrnIndTrggrd : 54|1@0+ (1,0) [0|1] "" TCP,CSM
 SG_ DTCI_SRR_LF_WrnIndRqd : 55|1@0+ (1,0) [0|1] "" TCP,CSM

BO_ 1200 DTCInfo_SRR_LR_CR_PDU: 7 CGM
 SG_ DTCI_SRR_LR_CR_DTCFailType : 6|8@0+ (1,0) [0|255] "" TCP,CSM
 SG_ DTCI_SRR_LR_CR_CnfrmdDTC : 7|1@0+ (1,0) [0|1] "" TCP,CSM
 SG_ DTCI_SRR_LR_CR_DTCFaultType : 14|8@0+ (1,0) [0|3] "" TCP,CSM
 SG_ DTCI_SRR_LR_CR_DTCNumber : 22|16@0+ (1,0) [0|65535] "" TCP,CSM
 SG_ DTCI_SRR_LR_CR_DTCSource : 38|8@0+ (1,0) [0|255] "" TCP,CSM
 SG_ DTCI_SRR_LR_CR_TstNCmpltdOpCyc : 40|1@0+ (1,0) [0|1] "" TCP,CSM
 SG_ DTCI_SRR_LR_CR_TstNCmpltdLstClr : 41|1@0+ (1,0) [0|1] "" TCP,CSM
 SG_ DTCI_SRR_LR_CR_TstFldOpCyc : 42|1@0+ (1,0) [0|1] "" TCP,CSM
 SG_ DTCI_SRR_LR_CR_TstFldLstClr : 43|1@0+ (1,0) [0|1] "" TCP,CSM
 SG_ DTCI_SRR_LR_CR_TstFld : 44|1@0+ (1,0) [0|1] "" TCP,CSM
 SG_ DTCI_SRR_LR_CR_PndngDTC : 45|1@0+ (1,0) [0|1] "" TCP,CSM
 SG_ DTCI_SRR_LR_CR_DTCTriggered : 46|1@0+ (1,0) [0|1] "" TCP,CSM
 SG_ DTCI_SRR_LR_CR_WrnIndTrggrd : 54|1@0+ (1,0) [0|1] "" TCP,CSM
 SG_ DTCI_SRR_LR_CR_WrnIndRqd : 55|1@0+ (1,0) [0|1] "" TCP,CSM

BO_ 1866 DTCInfo_SRR_RF_PDU: 7 CGM
 SG_ DTCI_SRR_RF_DTCFailType : 6|8@0+ (1,0) [0|255] "" TCP,CSM
 SG_ DTCI_SRR_RF_CnfrmdDTC : 7|1@0+ (1,0) [0|1] "" TCP,CSM
 SG_ DTCI_SRR_RF_DTCFaultType : 14|8@0+ (1,0) [0|3] "" TCP,CSM
 SG_ DTCI_SRR_RF_DTCNumber : 22|16@0+ (1,0) [0|65535] "" TCP,CSM
 SG_ DTCI_SRR_RF_DTCSource : 38|8@0+ (1,0) [0|255] "" TCP,CSM
 SG_ DTCI_SRR_RF_TstNCmpltdOpCyc : 40|1@0+ (1,0) [0|1] "" TCP,CSM
 SG_ DTCI_SRR_RF_TstNCmpltdLstClr : 41|1@0+ (1,0) [0|1] "" TCP,CSM
 SG_ DTCI_SRR_RF_TstFldOpCyc : 42|1@0+ (1,0) [0|1] "" TCP,CSM
 SG_ DTCI_SRR_RF_TstFldLstClr : 43|1@0+ (1,0) [0|1] "" TCP,CSM
 SG_ DTCI_SRR_RF_TstFld : 44|1@0+ (1,0) [0|1] "" TCP,CSM
 SG_ DTCI_SRR_RF_PndngDTC : 45|1@0+ (1,0) [0|1] "" TCP,CSM
 SG_ DTCI_SRR_RF_DTCTriggered : 46|1@0+ (1,0) [0|1] "" TCP,CSM
 SG_ DTCI_SRR_RF_WrnIndTrggrd : 54|1@0+ (1,0) [0|1] "" TCP,CSM
 SG_ DTCI_SRR_RF_WrnIndRqd : 55|1@0+ (1,0) [0|1] "" TCP,CSM

BA_DEF_ SG_  "SignalType" STRING ;
BA_DEF_ SG_  "SignalLongName" STRING ;
BA_DEF_ BO_  "GenMsgCycleTime" INT 0 10000;
BA_DEF_ BO_  "GenMsgSendType" ENUM "cyclicX","spontanX","cyclicIfActiveX","spontanWithDelay","cyclicAndSpontanX","cyclicAndSpontanWithDelay","spontanWithRepetition","cyclicIfActiveAndSpontanWD";
BA_DEF_DEF_  "SignalType" "";
BA_DEF_DEF_  "SignalLongName" "";
BA_DEF_DEF_  "GenMsgCycleTime" 0;
BA_DEF_DEF_  "GenMsgSendType" "cyclicX";
BA_ "GenMsgCycleTime" BO_ 1219 1000;
BA_ "GenMsgCycleTime" BO_ 1847 1000;
BA_ "GenMsgCycleTime" BO_ 1218 1000;
BA_ "GenMsgCycleTime" BO_ 1848 1000;
BA_ "GenMsgCycleTime" BO_ 1217 1000;
BA_ "GenMsgCycleTime" BO_ 1849 1000;
BA_ "GenMsgCycleTime" BO_ 1941 1000;
BA_ "GenMsgCycleTime" BO_ 1850 1000;
BA_ "GenMsgCycleTime" BO_ 1215 1000;
BA_ "GenMsgCycleTime" BO_ 1851 1000;
BA_ "GenMsgCycleTime" BO_ 1214 1000;
BA_ "GenMsgCycleTime" BO_ 1852 1000;
BA_ "GenMsgCycleTime" BO_ 1213 1000;
BA_ "GenMsgCycleTime" BO_ 1853 1000;
BA_ "GenMsgCycleTime" BO_ 1212 1000;
BA_ "GenMsgCycleTime" BO_ 1854 1000;
BA_ "GenMsgCycleTime" BO_ 1211 1000;
BA_ "GenMsgCycleTime" BO_ 1855 1000;
BA_ "GenMsgCycleTime" BO_ 1210 1000;
BA_ "GenMsgCycleTime" BO_ 1856 1000;
BA_ "GenMsgCycleTime" BO_ 1957 1000;
BA_ "GenMsgCycleTime" BO_ 1111 1000;
BA_ "GenMsgCycleTime" BO_ 1209 1000;
BA_ "GenMsgCycleTime" BO_ 1170 1000;
BA_ "GenMsgCycleTime" BO_ 1857 1000;
BA_ "GenMsgCycleTime" BO_ 1168 1000;
BA_ "GenMsgCycleTime" BO_ 1099 1000;
BA_ "GenMsgCycleTime" BO_ 1208 1000;
BA_ "GenMsgCycleTime" BO_ 1858 1000;
BA_ "GenMsgCycleTime" BO_ 1918 1000;
BA_ "GenMsgCycleTime" BO_ 1859 1000;
BA_ "GenMsgCycleTime" BO_ 1206 1000;
BA_ "GenMsgCycleTime" BO_ 1956 1000;
BA_ "GenMsgCycleTime" BO_ 1860 1000;
BA_ "GenMsgCycleTime" BO_ 1205 1000;
BA_ "GenMsgCycleTime" BO_ 1861 1000;
BA_ "GenMsgCycleTime" BO_ 1204 1000;
BA_ "GenMsgCycleTime" BO_ 1862 1000;
BA_ "GenMsgCycleTime" BO_ 1203 1000;
BA_ "GenMsgCycleTime" BO_ 1863 1000;
BA_ "GenMsgCycleTime" BO_ 1202 1000;
BA_ "GenMsgCycleTime" BO_ 1919 1000;
BA_ "GenMsgCycleTime" BO_ 1864 1000;
BA_ "GenMsgCycleTime" BO_ 1201 1000;
BA_ "GenMsgCycleTime" BO_ 1865 1000;
BA_ "GenMsgCycleTime" BO_ 1200 1000;
BA_ "GenMsgCycleTime" BO_ 1866 1000;
BA_ "SignalLongName" SG_ 1219 DTCI_HVAC_FP_F_DTCFailType "Diagnostic Trouble Code Information Extended - HVAC_FP_F : Diagnostic Trouble Code Failure Type";
BA_ "SignalType" SG_ 1219 DTCI_HVAC_FP_F_CnfrmdDTC "ENM";
BA_ "SignalLongName" SG_ 1219 DTCI_HVAC_FP_F_CnfrmdDTC "Diagnostic Trouble Code Information Extended - HVAC_FP_F : Confirmed DTC";
BA_ "SignalType" SG_ 1219 DTCI_HVAC_FP_F_DTCFaultType "ENM";
BA_ "SignalLongName" SG_ 1219 DTCI_HVAC_FP_F_DTCFaultType "Diagnostic Trouble Code Information Extended - HVAC_FP_F : Diagnostic Trouble Code Fault Type";
BA_ "SignalLongName" SG_ 1219 DTCI_HVAC_FP_F_DTCNumber "Diagnostic Trouble Code Information Extended - HVAC_FP_F : Diagnostic Trouble Code Number";
BA_ "SignalLongName" SG_ 1219 DTCI_HVAC_FP_F_DTCSource "Diagnostic Trouble Code Information Extended - HVAC_FP_F : Diagnostic Trouble Code Source";
BA_ "SignalType" SG_ 1219 DTCI_HVAC_FP_F_TstNCmpltdOpCyc "ENM";
BA_ "SignalLongName" SG_ 1219 DTCI_HVAC_FP_F_TstNCmpltdOpCyc "Diagnostic Trouble Code Information Extended - HVAC_FP_F : Test Not Completed This Operation Cycle";
BA_ "SignalType" SG_ 1219 DTCI_HVAC_FP_F_TstNCmpltdLstClr "ENM";
BA_ "SignalLongName" SG_ 1219 DTCI_HVAC_FP_F_TstNCmpltdLstClr "Diagnostic Trouble Code Information Extended - HVAC_FP_F : Test Not Completed Since Last Clear";
BA_ "SignalType" SG_ 1219 DTCI_HVAC_FP_F_TstFldOpCyc "ENM";
BA_ "SignalLongName" SG_ 1219 DTCI_HVAC_FP_F_TstFldOpCyc "Diagnostic Trouble Code Information Extended - HVAC_FP_F : Test Failed This Operation Cycle";
BA_ "SignalType" SG_ 1219 DTCI_HVAC_FP_F_TstFldLstClr "ENM";
BA_ "SignalLongName" SG_ 1219 DTCI_HVAC_FP_F_TstFldLstClr "Diagnostic Trouble Code Information Extended - HVAC_FP_F : Test Failed Since Last Clear";
BA_ "SignalType" SG_ 1219 DTCI_HVAC_FP_F_TstFld "ENM";
BA_ "SignalLongName" SG_ 1219 DTCI_HVAC_FP_F_TstFld "Diagnostic Trouble Code Information Extended - HVAC_FP_F : Test Failed";
BA_ "SignalType" SG_ 1219 DTCI_HVAC_FP_F_PndngDTC "ENM";
BA_ "SignalLongName" SG_ 1219 DTCI_HVAC_FP_F_PndngDTC "Diagnostic Trouble Code Information Extended - HVAC_FP_F : Pending DTC";
BA_ "SignalType" SG_ 1219 DTCI_HVAC_FP_F_DTCTriggered "ENM";
BA_ "SignalLongName" SG_ 1219 DTCI_HVAC_FP_F_DTCTriggered "Diagnostic Trouble Code Information Extended - HVAC_FP_F : Diagnostic Trouble Code Triggered";
BA_ "SignalType" SG_ 1219 DTCI_HVAC_FP_F_WrnIndTrggrd "ENM";
BA_ "SignalLongName" SG_ 1219 DTCI_HVAC_FP_F_WrnIndTrggrd "Diagnostic Trouble Code Information Extended - HVAC_FP_F : Warning Indicator Triggered";
BA_ "SignalType" SG_ 1219 DTCI_HVAC_FP_F_WrnIndRqd "ENM";
BA_ "SignalLongName" SG_ 1219 DTCI_HVAC_FP_F_WrnIndRqd "Diagnostic Trouble Code Information Extended - HVAC_FP_F : Warning Indicator Requested";
BA_ "SignalLongName" SG_ 1847 DTCI_HVAC_FP_R_DTCFailType "Diagnostic Trouble Code Information Extended - HVAC_FP_R : Diagnostic Trouble Code Failure Type";
BA_ "SignalType" SG_ 1847 DTCI_HVAC_FP_R_CnfrmdDTC "ENM";
BA_ "SignalLongName" SG_ 1847 DTCI_HVAC_FP_R_CnfrmdDTC "Diagnostic Trouble Code Information Extended - HVAC_FP_R : Confirmed DTC";
BA_ "SignalType" SG_ 1847 DTCI_HVAC_FP_R_DTCFaultType "ENM";
BA_ "SignalLongName" SG_ 1847 DTCI_HVAC_FP_R_DTCFaultType "Diagnostic Trouble Code Information Extended - HVAC_FP_R : Diagnostic Trouble Code Fault Type";
BA_ "SignalLongName" SG_ 1847 DTCI_HVAC_FP_R_DTCNumber "Diagnostic Trouble Code Information Extended - HVAC_FP_R : Diagnostic Trouble Code Number";
BA_ "SignalLongName" SG_ 1847 DTCI_HVAC_FP_R_DTCSource "Diagnostic Trouble Code Information Extended - HVAC_FP_R : Diagnostic Trouble Code Source";
BA_ "SignalType" SG_ 1847 DTCI_HVAC_FP_R_TstNCmpltdOpCyc "ENM";
BA_ "SignalLongName" SG_ 1847 DTCI_HVAC_FP_R_TstNCmpltdOpCyc "Diagnostic Trouble Code Information Extended - HVAC_FP_R : Test Not Completed This Operation Cycle";
BA_ "SignalType" SG_ 1847 DTCI_HVAC_FP_R_TstNCmpltdLstClr "ENM";
BA_ "SignalLongName" SG_ 1847 DTCI_HVAC_FP_R_TstNCmpltdLstClr "Diagnostic Trouble Code Information Extended - HVAC_FP_R : Test Not Completed Since Last Clear";
BA_ "SignalType" SG_ 1847 DTCI_HVAC_FP_R_TstFldOpCyc "ENM";
BA_ "SignalLongName" SG_ 1847 DTCI_HVAC_FP_R_TstFldOpCyc "Diagnostic Trouble Code Information Extended - HVAC_FP_R : Test Failed This Operation Cycle";
BA_ "SignalType" SG_ 1847 DTCI_HVAC_FP_R_TstFldLstClr "ENM";
BA_ "SignalLongName" SG_ 1847 DTCI_HVAC_FP_R_TstFldLstClr "Diagnostic Trouble Code Information Extended - HVAC_FP_R : Test Failed Since Last Clear";
BA_ "SignalType" SG_ 1847 DTCI_HVAC_FP_R_TstFld "ENM";
BA_ "SignalLongName" SG_ 1847 DTCI_HVAC_FP_R_TstFld "Diagnostic Trouble Code Information Extended - HVAC_FP_R : Test Failed";
BA_ "SignalType" SG_ 1847 DTCI_HVAC_FP_R_PndngDTC "ENM";
BA_ "SignalLongName" SG_ 1847 DTCI_HVAC_FP_R_PndngDTC "Diagnostic Trouble Code Information Extended - HVAC_FP_R : Pending DTC";
BA_ "SignalType" SG_ 1847 DTCI_HVAC_FP_R_DTCTriggered "ENM";
BA_ "SignalLongName" SG_ 1847 DTCI_HVAC_FP_R_DTCTriggered "Diagnostic Trouble Code Information Extended - HVAC_FP_R : Diagnostic Trouble Code Triggered";
BA_ "SignalType" SG_ 1847 DTCI_HVAC_FP_R_WrnIndTrggrd "ENM";
BA_ "SignalLongName" SG_ 1847 DTCI_HVAC_FP_R_WrnIndTrggrd "Diagnostic Trouble Code Information Extended - HVAC_FP_R : Warning Indicator Triggered";
BA_ "SignalType" SG_ 1847 DTCI_HVAC_FP_R_WrnIndRqd "ENM";
BA_ "SignalLongName" SG_ 1847 DTCI_HVAC_FP_R_WrnIndRqd "Diagnostic Trouble Code Information Extended - HVAC_FP_R : Warning Indicator Requested";
BA_ "SignalLongName" SG_ 1218 DTCI_ICCM_DTCFailType "Diagnostic Trouble Code Information Extended - ICCM : Diagnostic Trouble Code Failure Type";
BA_ "SignalType" SG_ 1218 DTCI_ICCM_CnfrmdDTC "ENM";
BA_ "SignalLongName" SG_ 1218 DTCI_ICCM_CnfrmdDTC "Diagnostic Trouble Code Information Extended - ICCM : Confirmed DTC";
BA_ "SignalType" SG_ 1218 DTCI_ICCM_DTCFaultType "ENM";
BA_ "SignalLongName" SG_ 1218 DTCI_ICCM_DTCFaultType "Diagnostic Trouble Code Information Extended - ICCM : Diagnostic Trouble Code Fault Type";
BA_ "SignalLongName" SG_ 1218 DTCI_ICCM_DTCNumber "Diagnostic Trouble Code Information Extended - ICCM : Diagnostic Trouble Code Number";
BA_ "SignalLongName" SG_ 1218 DTCI_ICCM_DTCSource "Diagnostic Trouble Code Information Extended - ICCM : Diagnostic Trouble Code Source";
BA_ "SignalType" SG_ 1218 DTCI_ICCM_TstNCmpltdOpCyc "ENM";
BA_ "SignalLongName" SG_ 1218 DTCI_ICCM_TstNCmpltdOpCyc "Diagnostic Trouble Code Information Extended - ICCM : Test Not Completed This Operation Cycle";
BA_ "SignalType" SG_ 1218 DTCI_ICCM_TstNCmpltdLstClr "ENM";
BA_ "SignalLongName" SG_ 1218 DTCI_ICCM_TstNCmpltdLstClr "Diagnostic Trouble Code Information Extended - ICCM : Test Not Completed Since Last Clear";
BA_ "SignalType" SG_ 1218 DTCI_ICCM_TstFldOpCyc "ENM";
BA_ "SignalLongName" SG_ 1218 DTCI_ICCM_TstFldOpCyc "Diagnostic Trouble Code Information Extended - ICCM : Test Failed This Operation Cycle";
BA_ "SignalType" SG_ 1218 DTCI_ICCM_TstFldLstClr "ENM";
BA_ "SignalLongName" SG_ 1218 DTCI_ICCM_TstFldLstClr "Diagnostic Trouble Code Information Extended - ICCM : Test Failed Since Last Clear";
BA_ "SignalType" SG_ 1218 DTCI_ICCM_TstFld "ENM";
BA_ "SignalLongName" SG_ 1218 DTCI_ICCM_TstFld "Diagnostic Trouble Code Information Extended - ICCM : Test Failed";
BA_ "SignalType" SG_ 1218 DTCI_ICCM_PndngDTC "ENM";
BA_ "SignalLongName" SG_ 1218 DTCI_ICCM_PndngDTC "Diagnostic Trouble Code Information Extended - ICCM : Pending DTC";
BA_ "SignalType" SG_ 1218 DTCI_ICCM_DTCTriggered "ENM";
BA_ "SignalLongName" SG_ 1218 DTCI_ICCM_DTCTriggered "Diagnostic Trouble Code Information Extended - ICCM : Diagnostic Trouble Code Triggered";
BA_ "SignalType" SG_ 1218 DTCI_ICCM_WrnIndTrggrd "ENM";
BA_ "SignalLongName" SG_ 1218 DTCI_ICCM_WrnIndTrggrd "Diagnostic Trouble Code Information Extended - ICCM : Warning Indicator Triggered";
BA_ "SignalType" SG_ 1218 DTCI_ICCM_WrnIndRqd "ENM";
BA_ "SignalLongName" SG_ 1218 DTCI_ICCM_WrnIndRqd "Diagnostic Trouble Code Information Extended - ICCM : Warning Indicator Requested";
BA_ "SignalLongName" SG_ 1848 DTCI_ICS_Info_DTCFailType "Diagnostic Trouble Code Information Extended - ICS_Info : Diagnostic Trouble Code Failure Type";
BA_ "SignalType" SG_ 1848 DTCI_ICS_Info_CnfrmdDTC "ENM";
BA_ "SignalLongName" SG_ 1848 DTCI_ICS_Info_CnfrmdDTC "Diagnostic Trouble Code Information Extended - ICS_Info : Confirmed DTC";
BA_ "SignalType" SG_ 1848 DTCI_ICS_Info_DTCFaultType "ENM";
BA_ "SignalLongName" SG_ 1848 DTCI_ICS_Info_DTCFaultType "Diagnostic Trouble Code Information Extended - ICS_Info : Diagnostic Trouble Code Fault Type";
BA_ "SignalLongName" SG_ 1848 DTCI_ICS_Info_DTCNumber "Diagnostic Trouble Code Information Extended - ICS_Info : Diagnostic Trouble Code Number";
BA_ "SignalLongName" SG_ 1848 DTCI_ICS_Info_DTCSource "Diagnostic Trouble Code Information Extended - ICS_Info : Diagnostic Trouble Code Source";
BA_ "SignalType" SG_ 1848 DTCI_ICS_Info_TstNCmpltdOpCyc "ENM";
BA_ "SignalLongName" SG_ 1848 DTCI_ICS_Info_TstNCmpltdOpCyc "Diagnostic Trouble Code Information Extended - ICS_Info : Test Not Completed This Operation Cycle";
BA_ "SignalType" SG_ 1848 DTCI_ICS_Info_TstNCmpltdLstClr "ENM";
BA_ "SignalLongName" SG_ 1848 DTCI_ICS_Info_TstNCmpltdLstClr "Diagnostic Trouble Code Information Extended - ICS_Info : Test Not Completed Since Last Clear";
BA_ "SignalType" SG_ 1848 DTCI_ICS_Info_TstFldOpCyc "ENM";
BA_ "SignalLongName" SG_ 1848 DTCI_ICS_Info_TstFldOpCyc "Diagnostic Trouble Code Information Extended - ICS_Info : Test Failed This Operation Cycle";
BA_ "SignalType" SG_ 1848 DTCI_ICS_Info_TstFldLstClr "ENM";
BA_ "SignalLongName" SG_ 1848 DTCI_ICS_Info_TstFldLstClr "Diagnostic Trouble Code Information Extended - ICS_Info : Test Failed Since Last Clear";
BA_ "SignalType" SG_ 1848 DTCI_ICS_Info_TstFld "ENM";
BA_ "SignalLongName" SG_ 1848 DTCI_ICS_Info_TstFld "Diagnostic Trouble Code Information Extended - ICS_Info : Test Failed";
BA_ "SignalType" SG_ 1848 DTCI_ICS_Info_PndngDTC "ENM";
BA_ "SignalLongName" SG_ 1848 DTCI_ICS_Info_PndngDTC "Diagnostic Trouble Code Information Extended - ICS_Info : Pending DTC";
BA_ "SignalType" SG_ 1848 DTCI_ICS_Info_DTCTriggered "ENM";
BA_ "SignalLongName" SG_ 1848 DTCI_ICS_Info_DTCTriggered "Diagnostic Trouble Code Information Extended - ICS_Info : Diagnostic Trouble Code Triggered";
BA_ "SignalType" SG_ 1848 DTCI_ICS_Info_WrnIndTrggrd "ENM";
BA_ "SignalLongName" SG_ 1848 DTCI_ICS_Info_WrnIndTrggrd "Diagnostic Trouble Code Information Extended - ICS_Info : Warning Indicator Triggered";
BA_ "SignalType" SG_ 1848 DTCI_ICS_Info_WrnIndRqd "ENM";
BA_ "SignalLongName" SG_ 1848 DTCI_ICS_Info_WrnIndRqd "Diagnostic Trouble Code Information Extended - ICS_Info : Warning Indicator Requested";
BA_ "SignalLongName" SG_ 1217 DTCI_IPC_DTCFailType "Diagnostic Trouble Code Information Extended - IPC : Diagnostic Trouble Code Failure Type";
BA_ "SignalType" SG_ 1217 DTCI_IPC_CnfrmdDTC "ENM";
BA_ "SignalLongName" SG_ 1217 DTCI_IPC_CnfrmdDTC "Diagnostic Trouble Code Information Extended - IPC : Confirmed DTC";
BA_ "SignalType" SG_ 1217 DTCI_IPC_DTCFaultType "ENM";
BA_ "SignalLongName" SG_ 1217 DTCI_IPC_DTCFaultType "Diagnostic Trouble Code Information Extended - IPC : Diagnostic Trouble Code Fault Type";
BA_ "SignalLongName" SG_ 1217 DTCI_IPC_DTCNumber "Diagnostic Trouble Code Information Extended - IPC : Diagnostic Trouble Code Number";
BA_ "SignalLongName" SG_ 1217 DTCI_IPC_DTCSource "Diagnostic Trouble Code Information Extended - IPC : Diagnostic Trouble Code Source";
BA_ "SignalType" SG_ 1217 DTCI_IPC_TstNCmpltdOpCyc "ENM";
BA_ "SignalLongName" SG_ 1217 DTCI_IPC_TstNCmpltdOpCyc "Diagnostic Trouble Code Information Extended - IPC : Test Not Completed This Operation Cycle";
BA_ "SignalType" SG_ 1217 DTCI_IPC_TstNCmpltdLstClr "ENM";
BA_ "SignalLongName" SG_ 1217 DTCI_IPC_TstNCmpltdLstClr "Diagnostic Trouble Code Information Extended - IPC : Test Not Completed Since Last Clear";
BA_ "SignalType" SG_ 1217 DTCI_IPC_TstFldOpCyc "ENM";
BA_ "SignalLongName" SG_ 1217 DTCI_IPC_TstFldOpCyc "Diagnostic Trouble Code Information Extended - IPC : Test Failed This Operation Cycle";
BA_ "SignalType" SG_ 1217 DTCI_IPC_TstFldLstClr "ENM";
BA_ "SignalLongName" SG_ 1217 DTCI_IPC_TstFldLstClr "Diagnostic Trouble Code Information Extended - IPC : Test Failed Since Last Clear";
BA_ "SignalType" SG_ 1217 DTCI_IPC_TstFld "ENM";
BA_ "SignalLongName" SG_ 1217 DTCI_IPC_TstFld "Diagnostic Trouble Code Information Extended - IPC : Test Failed";
BA_ "SignalType" SG_ 1217 DTCI_IPC_PndngDTC "ENM";
BA_ "SignalLongName" SG_ 1217 DTCI_IPC_PndngDTC "Diagnostic Trouble Code Information Extended - IPC : Pending DTC";
BA_ "SignalType" SG_ 1217 DTCI_IPC_DTCTriggered "ENM";
BA_ "SignalLongName" SG_ 1217 DTCI_IPC_DTCTriggered "Diagnostic Trouble Code Information Extended - IPC : Diagnostic Trouble Code Triggered";
BA_ "SignalType" SG_ 1217 DTCI_IPC_WrnIndTrggrd "ENM";
BA_ "SignalLongName" SG_ 1217 DTCI_IPC_WrnIndTrggrd "Diagnostic Trouble Code Information Extended - IPC : Warning Indicator Triggered";
BA_ "SignalType" SG_ 1217 DTCI_IPC_WrnIndRqd "ENM";
BA_ "SignalLongName" SG_ 1217 DTCI_IPC_WrnIndRqd "Diagnostic Trouble Code Information Extended - IPC : Warning Indicator Requested";
BA_ "SignalLongName" SG_ 1849 DTCI_LIB1_DTCFailType "Diagnostic Trouble Code Information Extended - LIB1 : Diagnostic Trouble Code Failure Type";
BA_ "SignalType" SG_ 1849 DTCI_LIB1_CnfrmdDTC "ENM";
BA_ "SignalLongName" SG_ 1849 DTCI_LIB1_CnfrmdDTC "Diagnostic Trouble Code Information Extended - LIB1 : Confirmed DTC";
BA_ "SignalType" SG_ 1849 DTCI_LIB1_DTCFaultType "ENM";
BA_ "SignalLongName" SG_ 1849 DTCI_LIB1_DTCFaultType "Diagnostic Trouble Code Information Extended - LIB1 : Diagnostic Trouble Code Fault Type";
BA_ "SignalLongName" SG_ 1849 DTCI_LIB1_DTCNumber "Diagnostic Trouble Code Information Extended - LIB1 : Diagnostic Trouble Code Number";
BA_ "SignalLongName" SG_ 1849 DTCI_LIB1_DTCSource "Diagnostic Trouble Code Information Extended - LIB1 : Diagnostic Trouble Code Source";
BA_ "SignalType" SG_ 1849 DTCI_LIB1_TstNCmpltdOpCyc "ENM";
BA_ "SignalLongName" SG_ 1849 DTCI_LIB1_TstNCmpltdOpCyc "Diagnostic Trouble Code Information Extended - LIB1 : Test Not Completed This Operation Cycle";
BA_ "SignalType" SG_ 1849 DTCI_LIB1_TstNCmpltdLstClr "ENM";
BA_ "SignalLongName" SG_ 1849 DTCI_LIB1_TstNCmpltdLstClr "Diagnostic Trouble Code Information Extended - LIB1 : Test Not Completed Since Last Clear";
BA_ "SignalType" SG_ 1849 DTCI_LIB1_TstFldOpCyc "ENM";
BA_ "SignalLongName" SG_ 1849 DTCI_LIB1_TstFldOpCyc "Diagnostic Trouble Code Information Extended - LIB1 : Test Failed This Operation Cycle";
BA_ "SignalType" SG_ 1849 DTCI_LIB1_TstFldLstClr "ENM";
BA_ "SignalLongName" SG_ 1849 DTCI_LIB1_TstFldLstClr "Diagnostic Trouble Code Information Extended - LIB1 : Test Failed Since Last Clear";
BA_ "SignalType" SG_ 1849 DTCI_LIB1_TstFld "ENM";
BA_ "SignalLongName" SG_ 1849 DTCI_LIB1_TstFld "Diagnostic Trouble Code Information Extended - LIB1 : Test Failed";
BA_ "SignalType" SG_ 1849 DTCI_LIB1_PndngDTC "ENM";
BA_ "SignalLongName" SG_ 1849 DTCI_LIB1_PndngDTC "Diagnostic Trouble Code Information Extended - LIB1 : Pending DTC";
BA_ "SignalType" SG_ 1849 DTCI_LIB1_DTCTriggered "ENM";
BA_ "SignalLongName" SG_ 1849 DTCI_LIB1_DTCTriggered "Diagnostic Trouble Code Information Extended - LIB1 : Diagnostic Trouble Code Triggered";
BA_ "SignalType" SG_ 1849 DTCI_LIB1_WrnIndTrggrd "ENM";
BA_ "SignalLongName" SG_ 1849 DTCI_LIB1_WrnIndTrggrd "Diagnostic Trouble Code Information Extended - LIB1 : Warning Indicator Triggered";
BA_ "SignalType" SG_ 1849 DTCI_LIB1_WrnIndRqd "ENM";
BA_ "SignalLongName" SG_ 1849 DTCI_LIB1_WrnIndRqd "Diagnostic Trouble Code Information Extended - LIB1 : Warning Indicator Requested";
BA_ "SignalLongName" SG_ 1941 DTCI_LIB_48V_DTCFailType "Diagnostic Trouble Code Information Extended - LIB_48V : Diagnostic Trouble Code Failure Type";
BA_ "SignalType" SG_ 1941 DTCI_LIB_48V_CnfrmdDTC "ENM";
BA_ "SignalLongName" SG_ 1941 DTCI_LIB_48V_CnfrmdDTC "Diagnostic Trouble Code Information Extended - LIB_48V : Confirmed DTC";
BA_ "SignalType" SG_ 1941 DTCI_LIB_48V_DTCFaultType "ENM";
BA_ "SignalLongName" SG_ 1941 DTCI_LIB_48V_DTCFaultType "Diagnostic Trouble Code Information Extended - LIB_48V : Diagnostic Trouble Code Fault Type";
BA_ "SignalLongName" SG_ 1941 DTCI_LIB_48V_DTCNumber "Diagnostic Trouble Code Information Extended - LIB_48V : Diagnostic Trouble Code Number";
BA_ "SignalLongName" SG_ 1941 DTCI_LIB_48V_DTCSource "Diagnostic Trouble Code Information Extended - LIB_48V : Diagnostic Trouble Code Source";
BA_ "SignalType" SG_ 1941 DTCI_LIB_48V_TstNCmpltdOpCyc "ENM";
BA_ "SignalLongName" SG_ 1941 DTCI_LIB_48V_TstNCmpltdOpCyc "Diagnostic Trouble Code Information Extended - LIB_48V : Test Not Completed This Operation Cycle";
BA_ "SignalType" SG_ 1941 DTCI_LIB_48V_TstNCmpltdLstClr "ENM";
BA_ "SignalLongName" SG_ 1941 DTCI_LIB_48V_TstNCmpltdLstClr "Diagnostic Trouble Code Information Extended - LIB_48V : Test Not Completed Since Last Clear";
BA_ "SignalType" SG_ 1941 DTCI_LIB_48V_TstFldOpCyc "ENM";
BA_ "SignalLongName" SG_ 1941 DTCI_LIB_48V_TstFldOpCyc "Diagnostic Trouble Code Information Extended - LIB_48V : Test Failed This Operation Cycle";
BA_ "SignalType" SG_ 1941 DTCI_LIB_48V_TstFldLstClr "ENM";
BA_ "SignalLongName" SG_ 1941 DTCI_LIB_48V_TstFldLstClr "Diagnostic Trouble Code Information Extended - LIB_48V : Test Failed Since Last Clear";
BA_ "SignalType" SG_ 1941 DTCI_LIB_48V_TstFld "ENM";
BA_ "SignalLongName" SG_ 1941 DTCI_LIB_48V_TstFld "Diagnostic Trouble Code Information Extended - LIB_48V : Test Failed";
BA_ "SignalType" SG_ 1941 DTCI_LIB_48V_PndngDTC "ENM";
BA_ "SignalLongName" SG_ 1941 DTCI_LIB_48V_PndngDTC "Diagnostic Trouble Code Information Extended - LIB_48V : Pending DTC";
BA_ "SignalType" SG_ 1941 DTCI_LIB_48V_DTCTriggered "ENM";
BA_ "SignalLongName" SG_ 1941 DTCI_LIB_48V_DTCTriggered "Diagnostic Trouble Code Information Extended - LIB_48V : Diagnostic Trouble Code Triggered";
BA_ "SignalType" SG_ 1941 DTCI_LIB_48V_WrnIndTrggrd "ENM";
BA_ "SignalLongName" SG_ 1941 DTCI_LIB_48V_WrnIndTrggrd "Diagnostic Trouble Code Information Extended - LIB_48V : Warning Indicator Triggered";
BA_ "SignalType" SG_ 1941 DTCI_LIB_48V_WrnIndRqd "ENM";
BA_ "SignalLongName" SG_ 1941 DTCI_LIB_48V_WrnIndRqd "Diagnostic Trouble Code Information Extended - LIB_48V : Warning Indicator Requested";
BA_ "SignalLongName" SG_ 1850 DTCI_LRR_DTCFailType "Diagnostic Trouble Code Information Extended - LRR : Diagnostic Trouble Code Failure Type";
BA_ "SignalType" SG_ 1850 DTCI_LRR_CnfrmdDTC "ENM";
BA_ "SignalLongName" SG_ 1850 DTCI_LRR_CnfrmdDTC "Diagnostic Trouble Code Information Extended - LRR : Confirmed DTC";
BA_ "SignalType" SG_ 1850 DTCI_LRR_DTCFaultType "ENM";
BA_ "SignalLongName" SG_ 1850 DTCI_LRR_DTCFaultType "Diagnostic Trouble Code Information Extended - LRR : Diagnostic Trouble Code Fault Type";
BA_ "SignalLongName" SG_ 1850 DTCI_LRR_DTCNumber "Diagnostic Trouble Code Information Extended - LRR : Diagnostic Trouble Code Number";
BA_ "SignalLongName" SG_ 1850 DTCI_LRR_DTCSource "Diagnostic Trouble Code Information Extended - LRR : Diagnostic Trouble Code Source";
BA_ "SignalType" SG_ 1850 DTCI_LRR_TstNCmpltdOpCyc "ENM";
BA_ "SignalLongName" SG_ 1850 DTCI_LRR_TstNCmpltdOpCyc "Diagnostic Trouble Code Information Extended - LRR : Test Not Completed This Operation Cycle";
BA_ "SignalType" SG_ 1850 DTCI_LRR_TstNCmpltdLstClr "ENM";
BA_ "SignalLongName" SG_ 1850 DTCI_LRR_TstNCmpltdLstClr "Diagnostic Trouble Code Information Extended - LRR : Test Not Completed Since Last Clear";
BA_ "SignalType" SG_ 1850 DTCI_LRR_TstFldOpCyc "ENM";
BA_ "SignalLongName" SG_ 1850 DTCI_LRR_TstFldOpCyc "Diagnostic Trouble Code Information Extended - LRR : Test Failed This Operation Cycle";
BA_ "SignalType" SG_ 1850 DTCI_LRR_TstFldLstClr "ENM";
BA_ "SignalLongName" SG_ 1850 DTCI_LRR_TstFldLstClr "Diagnostic Trouble Code Information Extended - LRR : Test Failed Since Last Clear";
BA_ "SignalType" SG_ 1850 DTCI_LRR_TstFld "ENM";
BA_ "SignalLongName" SG_ 1850 DTCI_LRR_TstFld "Diagnostic Trouble Code Information Extended - LRR : Test Failed";
BA_ "SignalType" SG_ 1850 DTCI_LRR_PndngDTC "ENM";
BA_ "SignalLongName" SG_ 1850 DTCI_LRR_PndngDTC "Diagnostic Trouble Code Information Extended - LRR : Pending DTC";
BA_ "SignalType" SG_ 1850 DTCI_LRR_DTCTriggered "ENM";
BA_ "SignalLongName" SG_ 1850 DTCI_LRR_DTCTriggered "Diagnostic Trouble Code Information Extended - LRR : Diagnostic Trouble Code Triggered";
BA_ "SignalType" SG_ 1850 DTCI_LRR_WrnIndTrggrd "ENM";
BA_ "SignalLongName" SG_ 1850 DTCI_LRR_WrnIndTrggrd "Diagnostic Trouble Code Information Extended - LRR : Warning Indicator Triggered";
BA_ "SignalType" SG_ 1850 DTCI_LRR_WrnIndRqd "ENM";
BA_ "SignalLongName" SG_ 1850 DTCI_LRR_WrnIndRqd "Diagnostic Trouble Code Information Extended - LRR : Warning Indicator Requested";
BA_ "SignalLongName" SG_ 1215 DTCI_MFC_DTCFailType "Diagnostic Trouble Code Information Extended - MFC : Diagnostic Trouble Code Failure Type";
BA_ "SignalType" SG_ 1215 DTCI_MFC_CnfrmdDTC "ENM";
BA_ "SignalLongName" SG_ 1215 DTCI_MFC_CnfrmdDTC "Diagnostic Trouble Code Information Extended - MFC : Confirmed DTC";
BA_ "SignalType" SG_ 1215 DTCI_MFC_DTCFaultType "ENM";
BA_ "SignalLongName" SG_ 1215 DTCI_MFC_DTCFaultType "Diagnostic Trouble Code Information Extended - MFC : Diagnostic Trouble Code Fault Type";
BA_ "SignalLongName" SG_ 1215 DTCI_MFC_DTCNumber "Diagnostic Trouble Code Information Extended - MFC : Diagnostic Trouble Code Number";
BA_ "SignalLongName" SG_ 1215 DTCI_MFC_DTCSource "Diagnostic Trouble Code Information Extended - MFC : Diagnostic Trouble Code Source";
BA_ "SignalType" SG_ 1215 DTCI_MFC_TstNCmpltdOpCyc "ENM";
BA_ "SignalLongName" SG_ 1215 DTCI_MFC_TstNCmpltdOpCyc "Diagnostic Trouble Code Information Extended - MFC : Test Not Completed This Operation Cycle";
BA_ "SignalType" SG_ 1215 DTCI_MFC_TstNCmpltdLstClr "ENM";
BA_ "SignalLongName" SG_ 1215 DTCI_MFC_TstNCmpltdLstClr "Diagnostic Trouble Code Information Extended - MFC : Test Not Completed Since Last Clear";
BA_ "SignalType" SG_ 1215 DTCI_MFC_TstFldOpCyc "ENM";
BA_ "SignalLongName" SG_ 1215 DTCI_MFC_TstFldOpCyc "Diagnostic Trouble Code Information Extended - MFC : Test Failed This Operation Cycle";
BA_ "SignalType" SG_ 1215 DTCI_MFC_TstFldLstClr "ENM";
BA_ "SignalLongName" SG_ 1215 DTCI_MFC_TstFldLstClr "Diagnostic Trouble Code Information Extended - MFC : Test Failed Since Last Clear";
BA_ "SignalType" SG_ 1215 DTCI_MFC_TstFld "ENM";
BA_ "SignalLongName" SG_ 1215 DTCI_MFC_TstFld "Diagnostic Trouble Code Information Extended - MFC : Test Failed";
BA_ "SignalType" SG_ 1215 DTCI_MFC_PndngDTC "ENM";
BA_ "SignalLongName" SG_ 1215 DTCI_MFC_PndngDTC "Diagnostic Trouble Code Information Extended - MFC : Pending DTC";
BA_ "SignalType" SG_ 1215 DTCI_MFC_DTCTriggered "ENM";
BA_ "SignalLongName" SG_ 1215 DTCI_MFC_DTCTriggered "Diagnostic Trouble Code Information Extended - MFC : Diagnostic Trouble Code Triggered";
BA_ "SignalType" SG_ 1215 DTCI_MFC_WrnIndTrggrd "ENM";
BA_ "SignalLongName" SG_ 1215 DTCI_MFC_WrnIndTrggrd "Diagnostic Trouble Code Information Extended - MFC : Warning Indicator Triggered";
BA_ "SignalType" SG_ 1215 DTCI_MFC_WrnIndRqd "ENM";
BA_ "SignalLongName" SG_ 1215 DTCI_MFC_WrnIndRqd "Diagnostic Trouble Code Information Extended - MFC : Warning Indicator Requested";
BA_ "SignalLongName" SG_ 1851 DTCI_MRCM_L_DTCFailType "Diagnostic Trouble Code Information Extended - MRCM_L : Diagnostic Trouble Code Failure Type";
BA_ "SignalType" SG_ 1851 DTCI_MRCM_L_CnfrmdDTC "ENM";
BA_ "SignalLongName" SG_ 1851 DTCI_MRCM_L_CnfrmdDTC "Diagnostic Trouble Code Information Extended - MRCM_L : Confirmed DTC";
BA_ "SignalType" SG_ 1851 DTCI_MRCM_L_DTCFaultType "ENM";
BA_ "SignalLongName" SG_ 1851 DTCI_MRCM_L_DTCFaultType "Diagnostic Trouble Code Information Extended - MRCM_L : Diagnostic Trouble Code Fault Type";
BA_ "SignalLongName" SG_ 1851 DTCI_MRCM_L_DTCNumber "Diagnostic Trouble Code Information Extended - MRCM_L : Diagnostic Trouble Code Number";
BA_ "SignalLongName" SG_ 1851 DTCI_MRCM_L_DTCSource "Diagnostic Trouble Code Information Extended - MRCM_L : Diagnostic Trouble Code Source";
BA_ "SignalType" SG_ 1851 DTCI_MRCM_L_TstNCmpltdOpCyc "ENM";
BA_ "SignalLongName" SG_ 1851 DTCI_MRCM_L_TstNCmpltdOpCyc "Diagnostic Trouble Code Information Extended - MRCM_L : Test Not Completed This Operation Cycle";
BA_ "SignalType" SG_ 1851 DTCI_MRCM_L_TstNCmpltdLstClr "ENM";
BA_ "SignalLongName" SG_ 1851 DTCI_MRCM_L_TstNCmpltdLstClr "Diagnostic Trouble Code Information Extended - MRCM_L : Test Not Completed Since Last Clear";
BA_ "SignalType" SG_ 1851 DTCI_MRCM_L_TstFldOpCyc "ENM";
BA_ "SignalLongName" SG_ 1851 DTCI_MRCM_L_TstFldOpCyc "Diagnostic Trouble Code Information Extended - MRCM_L : Test Failed This Operation Cycle";
BA_ "SignalType" SG_ 1851 DTCI_MRCM_L_TstFldLstClr "ENM";
BA_ "SignalLongName" SG_ 1851 DTCI_MRCM_L_TstFldLstClr "Diagnostic Trouble Code Information Extended - MRCM_L : Test Failed Since Last Clear";
BA_ "SignalType" SG_ 1851 DTCI_MRCM_L_TstFld "ENM";
BA_ "SignalLongName" SG_ 1851 DTCI_MRCM_L_TstFld "Diagnostic Trouble Code Information Extended - MRCM_L : Test Failed";
BA_ "SignalType" SG_ 1851 DTCI_MRCM_L_PndngDTC "ENM";
BA_ "SignalLongName" SG_ 1851 DTCI_MRCM_L_PndngDTC "Diagnostic Trouble Code Information Extended - MRCM_L : Pending DTC";
BA_ "SignalType" SG_ 1851 DTCI_MRCM_L_DTCTriggered "ENM";
BA_ "SignalLongName" SG_ 1851 DTCI_MRCM_L_DTCTriggered "Diagnostic Trouble Code Information Extended - MRCM_L : Diagnostic Trouble Code Triggered";
BA_ "SignalType" SG_ 1851 DTCI_MRCM_L_WrnIndTrggrd "ENM";
BA_ "SignalLongName" SG_ 1851 DTCI_MRCM_L_WrnIndTrggrd "Diagnostic Trouble Code Information Extended - MRCM_L : Warning Indicator Triggered";
BA_ "SignalType" SG_ 1851 DTCI_MRCM_L_WrnIndRqd "ENM";
BA_ "SignalLongName" SG_ 1851 DTCI_MRCM_L_WrnIndRqd "Diagnostic Trouble Code Information Extended - MRCM_L : Warning Indicator Requested";
BA_ "SignalLongName" SG_ 1214 DTCI_MRCM_R_DTCFailType "Diagnostic Trouble Code Information Extended - MRCM_R : Diagnostic Trouble Code Failure Type";
BA_ "SignalType" SG_ 1214 DTCI_MRCM_R_CnfrmdDTC "ENM";
BA_ "SignalLongName" SG_ 1214 DTCI_MRCM_R_CnfrmdDTC "Diagnostic Trouble Code Information Extended - MRCM_R : Confirmed DTC";
BA_ "SignalType" SG_ 1214 DTCI_MRCM_R_DTCFaultType "ENM";
BA_ "SignalLongName" SG_ 1214 DTCI_MRCM_R_DTCFaultType "Diagnostic Trouble Code Information Extended - MRCM_R : Diagnostic Trouble Code Fault Type";
BA_ "SignalLongName" SG_ 1214 DTCI_MRCM_R_DTCNumber "Diagnostic Trouble Code Information Extended - MRCM_R : Diagnostic Trouble Code Number";
BA_ "SignalLongName" SG_ 1214 DTCI_MRCM_R_DTCSource "Diagnostic Trouble Code Information Extended - MRCM_R : Diagnostic Trouble Code Source";
BA_ "SignalType" SG_ 1214 DTCI_MRCM_R_TstNCmpltdOpCyc "ENM";
BA_ "SignalLongName" SG_ 1214 DTCI_MRCM_R_TstNCmpltdOpCyc "Diagnostic Trouble Code Information Extended - MRCM_R : Test Not Completed This Operation Cycle";
BA_ "SignalType" SG_ 1214 DTCI_MRCM_R_TstNCmpltdLstClr "ENM";
BA_ "SignalLongName" SG_ 1214 DTCI_MRCM_R_TstNCmpltdLstClr "Diagnostic Trouble Code Information Extended - MRCM_R : Test Not Completed Since Last Clear";
BA_ "SignalType" SG_ 1214 DTCI_MRCM_R_TstFldOpCyc "ENM";
BA_ "SignalLongName" SG_ 1214 DTCI_MRCM_R_TstFldOpCyc "Diagnostic Trouble Code Information Extended - MRCM_R : Test Failed This Operation Cycle";
BA_ "SignalType" SG_ 1214 DTCI_MRCM_R_TstFldLstClr "ENM";
BA_ "SignalLongName" SG_ 1214 DTCI_MRCM_R_TstFldLstClr "Diagnostic Trouble Code Information Extended - MRCM_R : Test Failed Since Last Clear";
BA_ "SignalType" SG_ 1214 DTCI_MRCM_R_TstFld "ENM";
BA_ "SignalLongName" SG_ 1214 DTCI_MRCM_R_TstFld "Diagnostic Trouble Code Information Extended - MRCM_R : Test Failed";
BA_ "SignalType" SG_ 1214 DTCI_MRCM_R_PndngDTC "ENM";
BA_ "SignalLongName" SG_ 1214 DTCI_MRCM_R_PndngDTC "Diagnostic Trouble Code Information Extended - MRCM_R : Pending DTC";
BA_ "SignalType" SG_ 1214 DTCI_MRCM_R_DTCTriggered "ENM";
BA_ "SignalLongName" SG_ 1214 DTCI_MRCM_R_DTCTriggered "Diagnostic Trouble Code Information Extended - MRCM_R : Diagnostic Trouble Code Triggered";
BA_ "SignalType" SG_ 1214 DTCI_MRCM_R_WrnIndTrggrd "ENM";
BA_ "SignalLongName" SG_ 1214 DTCI_MRCM_R_WrnIndTrggrd "Diagnostic Trouble Code Information Extended - MRCM_R : Warning Indicator Triggered";
BA_ "SignalType" SG_ 1214 DTCI_MRCM_R_WrnIndRqd "ENM";
BA_ "SignalLongName" SG_ 1214 DTCI_MRCM_R_WrnIndRqd "Diagnostic Trouble Code Information Extended - MRCM_R : Warning Indicator Requested";
BA_ "SignalLongName" SG_ 1852 DTCI_MSB1_DTCFailType "Diagnostic Trouble Code Information Extended - MSB1 : Diagnostic Trouble Code Failure Type";
BA_ "SignalType" SG_ 1852 DTCI_MSB1_CnfrmdDTC "ENM";
BA_ "SignalLongName" SG_ 1852 DTCI_MSB1_CnfrmdDTC "Diagnostic Trouble Code Information Extended - MSB1 : Confirmed DTC";
BA_ "SignalType" SG_ 1852 DTCI_MSB1_DTCFaultType "ENM";
BA_ "SignalLongName" SG_ 1852 DTCI_MSB1_DTCFaultType "Diagnostic Trouble Code Information Extended - MSB1 : Diagnostic Trouble Code Fault Type";
BA_ "SignalLongName" SG_ 1852 DTCI_MSB1_DTCNumber "Diagnostic Trouble Code Information Extended - MSB1 : Diagnostic Trouble Code Number";
BA_ "SignalLongName" SG_ 1852 DTCI_MSB1_DTCSource "Diagnostic Trouble Code Information Extended - MSB1 : Diagnostic Trouble Code Source";
BA_ "SignalType" SG_ 1852 DTCI_MSB1_TstNCmpltdOpCyc "ENM";
BA_ "SignalLongName" SG_ 1852 DTCI_MSB1_TstNCmpltdOpCyc "Diagnostic Trouble Code Information Extended - MSB1 : Test Not Completed This Operation Cycle";
BA_ "SignalType" SG_ 1852 DTCI_MSB1_TstNCmpltdLstClr "ENM";
BA_ "SignalLongName" SG_ 1852 DTCI_MSB1_TstNCmpltdLstClr "Diagnostic Trouble Code Information Extended - MSB1 : Test Not Completed Since Last Clear";
BA_ "SignalType" SG_ 1852 DTCI_MSB1_TstFldOpCyc "ENM";
BA_ "SignalLongName" SG_ 1852 DTCI_MSB1_TstFldOpCyc "Diagnostic Trouble Code Information Extended - MSB1 : Test Failed This Operation Cycle";
BA_ "SignalType" SG_ 1852 DTCI_MSB1_TstFldLstClr "ENM";
BA_ "SignalLongName" SG_ 1852 DTCI_MSB1_TstFldLstClr "Diagnostic Trouble Code Information Extended - MSB1 : Test Failed Since Last Clear";
BA_ "SignalType" SG_ 1852 DTCI_MSB1_TstFld "ENM";
BA_ "SignalLongName" SG_ 1852 DTCI_MSB1_TstFld "Diagnostic Trouble Code Information Extended - MSB1 : Test Failed";
BA_ "SignalType" SG_ 1852 DTCI_MSB1_PndngDTC "ENM";
BA_ "SignalLongName" SG_ 1852 DTCI_MSB1_PndngDTC "Diagnostic Trouble Code Information Extended - MSB1 : Pending DTC";
BA_ "SignalType" SG_ 1852 DTCI_MSB1_DTCTriggered "ENM";
BA_ "SignalLongName" SG_ 1852 DTCI_MSB1_DTCTriggered "Diagnostic Trouble Code Information Extended - MSB1 : Diagnostic Trouble Code Triggered";
BA_ "SignalType" SG_ 1852 DTCI_MSB1_WrnIndTrggrd "ENM";
BA_ "SignalLongName" SG_ 1852 DTCI_MSB1_WrnIndTrggrd "Diagnostic Trouble Code Information Extended - MSB1 : Warning Indicator Triggered";
BA_ "SignalType" SG_ 1852 DTCI_MSB1_WrnIndRqd "ENM";
BA_ "SignalLongName" SG_ 1852 DTCI_MSB1_WrnIndRqd "Diagnostic Trouble Code Information Extended - MSB1 : Warning Indicator Requested";
BA_ "SignalLongName" SG_ 1213 DTCI_MSB2_DTCFailType "Diagnostic Trouble Code Information Extended - MSB2 : Diagnostic Trouble Code Failure Type";
BA_ "SignalType" SG_ 1213 DTCI_MSB2_CnfrmdDTC "ENM";
BA_ "SignalLongName" SG_ 1213 DTCI_MSB2_CnfrmdDTC "Diagnostic Trouble Code Information Extended - MSB2 : Confirmed DTC";
BA_ "SignalType" SG_ 1213 DTCI_MSB2_DTCFaultType "ENM";
BA_ "SignalLongName" SG_ 1213 DTCI_MSB2_DTCFaultType "Diagnostic Trouble Code Information Extended - MSB2 : Diagnostic Trouble Code Fault Type";
BA_ "SignalLongName" SG_ 1213 DTCI_MSB2_DTCNumber "Diagnostic Trouble Code Information Extended - MSB2 : Diagnostic Trouble Code Number";
BA_ "SignalLongName" SG_ 1213 DTCI_MSB2_DTCSource "Diagnostic Trouble Code Information Extended - MSB2 : Diagnostic Trouble Code Source";
BA_ "SignalType" SG_ 1213 DTCI_MSB2_TstNCmpltdOpCyc "ENM";
BA_ "SignalLongName" SG_ 1213 DTCI_MSB2_TstNCmpltdOpCyc "Diagnostic Trouble Code Information Extended - MSB2 : Test Not Completed This Operation Cycle";
BA_ "SignalType" SG_ 1213 DTCI_MSB2_TstNCmpltdLstClr "ENM";
BA_ "SignalLongName" SG_ 1213 DTCI_MSB2_TstNCmpltdLstClr "Diagnostic Trouble Code Information Extended - MSB2 : Test Not Completed Since Last Clear";
BA_ "SignalType" SG_ 1213 DTCI_MSB2_TstFldOpCyc "ENM";
BA_ "SignalLongName" SG_ 1213 DTCI_MSB2_TstFldOpCyc "Diagnostic Trouble Code Information Extended - MSB2 : Test Failed This Operation Cycle";
BA_ "SignalType" SG_ 1213 DTCI_MSB2_TstFldLstClr "ENM";
BA_ "SignalLongName" SG_ 1213 DTCI_MSB2_TstFldLstClr "Diagnostic Trouble Code Information Extended - MSB2 : Test Failed Since Last Clear";
BA_ "SignalType" SG_ 1213 DTCI_MSB2_TstFld "ENM";
BA_ "SignalLongName" SG_ 1213 DTCI_MSB2_TstFld "Diagnostic Trouble Code Information Extended - MSB2 : Test Failed";
BA_ "SignalType" SG_ 1213 DTCI_MSB2_PndngDTC "ENM";
BA_ "SignalLongName" SG_ 1213 DTCI_MSB2_PndngDTC "Diagnostic Trouble Code Information Extended - MSB2 : Pending DTC";
BA_ "SignalType" SG_ 1213 DTCI_MSB2_DTCTriggered "ENM";
BA_ "SignalLongName" SG_ 1213 DTCI_MSB2_DTCTriggered "Diagnostic Trouble Code Information Extended - MSB2 : Diagnostic Trouble Code Triggered";
BA_ "SignalType" SG_ 1213 DTCI_MSB2_WrnIndTrggrd "ENM";
BA_ "SignalLongName" SG_ 1213 DTCI_MSB2_WrnIndTrggrd "Diagnostic Trouble Code Information Extended - MSB2 : Warning Indicator Triggered";
BA_ "SignalType" SG_ 1213 DTCI_MSB2_WrnIndRqd "ENM";
BA_ "SignalLongName" SG_ 1213 DTCI_MSB2_WrnIndRqd "Diagnostic Trouble Code Information Extended - MSB2 : Warning Indicator Requested";
BA_ "SignalLongName" SG_ 1853 DTCI_MSM_D_DTCFailType "Diagnostic Trouble Code Information Extended - MSM_D : Diagnostic Trouble Code Failure Type";
BA_ "SignalType" SG_ 1853 DTCI_MSM_D_CnfrmdDTC "ENM";
BA_ "SignalLongName" SG_ 1853 DTCI_MSM_D_CnfrmdDTC "Diagnostic Trouble Code Information Extended - MSM_D : Confirmed DTC";
BA_ "SignalType" SG_ 1853 DTCI_MSM_D_DTCFaultType "ENM";
BA_ "SignalLongName" SG_ 1853 DTCI_MSM_D_DTCFaultType "Diagnostic Trouble Code Information Extended - MSM_D : Diagnostic Trouble Code Fault Type";
BA_ "SignalLongName" SG_ 1853 DTCI_MSM_D_DTCNumber "Diagnostic Trouble Code Information Extended - MSM_D : Diagnostic Trouble Code Number";
BA_ "SignalLongName" SG_ 1853 DTCI_MSM_D_DTCSource "Diagnostic Trouble Code Information Extended - MSM_D : Diagnostic Trouble Code Source";
BA_ "SignalType" SG_ 1853 DTCI_MSM_D_TstNCmpltdOpCyc "ENM";
BA_ "SignalLongName" SG_ 1853 DTCI_MSM_D_TstNCmpltdOpCyc "Diagnostic Trouble Code Information Extended - MSM_D : Test Not Completed This Operation Cycle";
BA_ "SignalType" SG_ 1853 DTCI_MSM_D_TstNCmpltdLstClr "ENM";
BA_ "SignalLongName" SG_ 1853 DTCI_MSM_D_TstNCmpltdLstClr "Diagnostic Trouble Code Information Extended - MSM_D : Test Not Completed Since Last Clear";
BA_ "SignalType" SG_ 1853 DTCI_MSM_D_TstFldOpCyc "ENM";
BA_ "SignalLongName" SG_ 1853 DTCI_MSM_D_TstFldOpCyc "Diagnostic Trouble Code Information Extended - MSM_D : Test Failed This Operation Cycle";
BA_ "SignalType" SG_ 1853 DTCI_MSM_D_TstFldLstClr "ENM";
BA_ "SignalLongName" SG_ 1853 DTCI_MSM_D_TstFldLstClr "Diagnostic Trouble Code Information Extended - MSM_D : Test Failed Since Last Clear";
BA_ "SignalType" SG_ 1853 DTCI_MSM_D_TstFld "ENM";
BA_ "SignalLongName" SG_ 1853 DTCI_MSM_D_TstFld "Diagnostic Trouble Code Information Extended - MSM_D : Test Failed";
BA_ "SignalType" SG_ 1853 DTCI_MSM_D_PndngDTC "ENM";
BA_ "SignalLongName" SG_ 1853 DTCI_MSM_D_PndngDTC "Diagnostic Trouble Code Information Extended - MSM_D : Pending DTC";
BA_ "SignalType" SG_ 1853 DTCI_MSM_D_DTCTriggered "ENM";
BA_ "SignalLongName" SG_ 1853 DTCI_MSM_D_DTCTriggered "Diagnostic Trouble Code Information Extended - MSM_D : Diagnostic Trouble Code Triggered";
BA_ "SignalType" SG_ 1853 DTCI_MSM_D_WrnIndTrggrd "ENM";
BA_ "SignalLongName" SG_ 1853 DTCI_MSM_D_WrnIndTrggrd "Diagnostic Trouble Code Information Extended - MSM_D : Warning Indicator Triggered";
BA_ "SignalType" SG_ 1853 DTCI_MSM_D_WrnIndRqd "ENM";
BA_ "SignalLongName" SG_ 1853 DTCI_MSM_D_WrnIndRqd "Diagnostic Trouble Code Information Extended - MSM_D : Warning Indicator Requested";
BA_ "SignalLongName" SG_ 1212 DTCI_MSM_LR_DTCFailType "Diagnostic Trouble Code Information Extended - MSM_LR : Diagnostic Trouble Code Failure Type";
BA_ "SignalType" SG_ 1212 DTCI_MSM_LR_CnfrmdDTC "ENM";
BA_ "SignalLongName" SG_ 1212 DTCI_MSM_LR_CnfrmdDTC "Diagnostic Trouble Code Information Extended - MSM_LR : Confirmed DTC";
BA_ "SignalType" SG_ 1212 DTCI_MSM_LR_DTCFaultType "ENM";
BA_ "SignalLongName" SG_ 1212 DTCI_MSM_LR_DTCFaultType "Diagnostic Trouble Code Information Extended - MSM_LR : Diagnostic Trouble Code Fault Type";
BA_ "SignalLongName" SG_ 1212 DTCI_MSM_LR_DTCNumber "Diagnostic Trouble Code Information Extended - MSM_LR : Diagnostic Trouble Code Number";
BA_ "SignalLongName" SG_ 1212 DTCI_MSM_LR_DTCSource "Diagnostic Trouble Code Information Extended - MSM_LR : Diagnostic Trouble Code Source";
BA_ "SignalType" SG_ 1212 DTCI_MSM_LR_TstNCmpltdOpCyc "ENM";
BA_ "SignalLongName" SG_ 1212 DTCI_MSM_LR_TstNCmpltdOpCyc "Diagnostic Trouble Code Information Extended - MSM_LR : Test Not Completed This Operation Cycle";
BA_ "SignalType" SG_ 1212 DTCI_MSM_LR_TstNCmpltdLstClr "ENM";
BA_ "SignalLongName" SG_ 1212 DTCI_MSM_LR_TstNCmpltdLstClr "Diagnostic Trouble Code Information Extended - MSM_LR : Test Not Completed Since Last Clear";
BA_ "SignalType" SG_ 1212 DTCI_MSM_LR_TstFldOpCyc "ENM";
BA_ "SignalLongName" SG_ 1212 DTCI_MSM_LR_TstFldOpCyc "Diagnostic Trouble Code Information Extended - MSM_LR : Test Failed This Operation Cycle";
BA_ "SignalType" SG_ 1212 DTCI_MSM_LR_TstFldLstClr "ENM";
BA_ "SignalLongName" SG_ 1212 DTCI_MSM_LR_TstFldLstClr "Diagnostic Trouble Code Information Extended - MSM_LR : Test Failed Since Last Clear";
BA_ "SignalType" SG_ 1212 DTCI_MSM_LR_TstFld "ENM";
BA_ "SignalLongName" SG_ 1212 DTCI_MSM_LR_TstFld "Diagnostic Trouble Code Information Extended - MSM_LR : Test Failed";
BA_ "SignalType" SG_ 1212 DTCI_MSM_LR_PndngDTC "ENM";
BA_ "SignalLongName" SG_ 1212 DTCI_MSM_LR_PndngDTC "Diagnostic Trouble Code Information Extended - MSM_LR : Pending DTC";
BA_ "SignalType" SG_ 1212 DTCI_MSM_LR_DTCTriggered "ENM";
BA_ "SignalLongName" SG_ 1212 DTCI_MSM_LR_DTCTriggered "Diagnostic Trouble Code Information Extended - MSM_LR : Diagnostic Trouble Code Triggered";
BA_ "SignalType" SG_ 1212 DTCI_MSM_LR_WrnIndTrggrd "ENM";
BA_ "SignalLongName" SG_ 1212 DTCI_MSM_LR_WrnIndTrggrd "Diagnostic Trouble Code Information Extended - MSM_LR : Warning Indicator Triggered";
BA_ "SignalType" SG_ 1212 DTCI_MSM_LR_WrnIndRqd "ENM";
BA_ "SignalLongName" SG_ 1212 DTCI_MSM_LR_WrnIndRqd "Diagnostic Trouble Code Information Extended - MSM_LR : Warning Indicator Requested";
BA_ "SignalLongName" SG_ 1854 DTCI_MSM_P_DTCFailType "Diagnostic Trouble Code Information Extended - MSM_P : Diagnostic Trouble Code Failure Type";
BA_ "SignalType" SG_ 1854 DTCI_MSM_P_CnfrmdDTC "ENM";
BA_ "SignalLongName" SG_ 1854 DTCI_MSM_P_CnfrmdDTC "Diagnostic Trouble Code Information Extended - MSM_P : Confirmed DTC";
BA_ "SignalType" SG_ 1854 DTCI_MSM_P_DTCFaultType "ENM";
BA_ "SignalLongName" SG_ 1854 DTCI_MSM_P_DTCFaultType "Diagnostic Trouble Code Information Extended - MSM_P : Diagnostic Trouble Code Fault Type";
BA_ "SignalLongName" SG_ 1854 DTCI_MSM_P_DTCNumber "Diagnostic Trouble Code Information Extended - MSM_P : Diagnostic Trouble Code Number";
BA_ "SignalLongName" SG_ 1854 DTCI_MSM_P_DTCSource "Diagnostic Trouble Code Information Extended - MSM_P : Diagnostic Trouble Code Source";
BA_ "SignalType" SG_ 1854 DTCI_MSM_P_TstNCmpltdOpCyc "ENM";
BA_ "SignalLongName" SG_ 1854 DTCI_MSM_P_TstNCmpltdOpCyc "Diagnostic Trouble Code Information Extended - MSM_P : Test Not Completed This Operation Cycle";
BA_ "SignalType" SG_ 1854 DTCI_MSM_P_TstNCmpltdLstClr "ENM";
BA_ "SignalLongName" SG_ 1854 DTCI_MSM_P_TstNCmpltdLstClr "Diagnostic Trouble Code Information Extended - MSM_P : Test Not Completed Since Last Clear";
BA_ "SignalType" SG_ 1854 DTCI_MSM_P_TstFldOpCyc "ENM";
BA_ "SignalLongName" SG_ 1854 DTCI_MSM_P_TstFldOpCyc "Diagnostic Trouble Code Information Extended - MSM_P : Test Failed This Operation Cycle";
BA_ "SignalType" SG_ 1854 DTCI_MSM_P_TstFldLstClr "ENM";
BA_ "SignalLongName" SG_ 1854 DTCI_MSM_P_TstFldLstClr "Diagnostic Trouble Code Information Extended - MSM_P : Test Failed Since Last Clear";
BA_ "SignalType" SG_ 1854 DTCI_MSM_P_TstFld "ENM";
BA_ "SignalLongName" SG_ 1854 DTCI_MSM_P_TstFld "Diagnostic Trouble Code Information Extended - MSM_P : Test Failed";
BA_ "SignalType" SG_ 1854 DTCI_MSM_P_PndngDTC "ENM";
BA_ "SignalLongName" SG_ 1854 DTCI_MSM_P_PndngDTC "Diagnostic Trouble Code Information Extended - MSM_P : Pending DTC";
BA_ "SignalType" SG_ 1854 DTCI_MSM_P_DTCTriggered "ENM";
BA_ "SignalLongName" SG_ 1854 DTCI_MSM_P_DTCTriggered "Diagnostic Trouble Code Information Extended - MSM_P : Diagnostic Trouble Code Triggered";
BA_ "SignalType" SG_ 1854 DTCI_MSM_P_WrnIndTrggrd "ENM";
BA_ "SignalLongName" SG_ 1854 DTCI_MSM_P_WrnIndTrggrd "Diagnostic Trouble Code Information Extended - MSM_P : Warning Indicator Triggered";
BA_ "SignalType" SG_ 1854 DTCI_MSM_P_WrnIndRqd "ENM";
BA_ "SignalLongName" SG_ 1854 DTCI_MSM_P_WrnIndRqd "Diagnostic Trouble Code Information Extended - MSM_P : Warning Indicator Requested";
BA_ "SignalLongName" SG_ 1211 DTCI_MSM_RR_DTCFailType "Diagnostic Trouble Code Information Extended - MSM_RR : Diagnostic Trouble Code Failure Type";
BA_ "SignalType" SG_ 1211 DTCI_MSM_RR_CnfrmdDTC "ENM";
BA_ "SignalLongName" SG_ 1211 DTCI_MSM_RR_CnfrmdDTC "Diagnostic Trouble Code Information Extended - MSM_RR : Confirmed DTC";
BA_ "SignalType" SG_ 1211 DTCI_MSM_RR_DTCFaultType "ENM";
BA_ "SignalLongName" SG_ 1211 DTCI_MSM_RR_DTCFaultType "Diagnostic Trouble Code Information Extended - MSM_RR : Diagnostic Trouble Code Fault Type";
BA_ "SignalLongName" SG_ 1211 DTCI_MSM_RR_DTCNumber "Diagnostic Trouble Code Information Extended - MSM_RR : Diagnostic Trouble Code Number";
BA_ "SignalLongName" SG_ 1211 DTCI_MSM_RR_DTCSource "Diagnostic Trouble Code Information Extended - MSM_RR : Diagnostic Trouble Code Source";
BA_ "SignalType" SG_ 1211 DTCI_MSM_RR_TstNCmpltdOpCyc "ENM";
BA_ "SignalLongName" SG_ 1211 DTCI_MSM_RR_TstNCmpltdOpCyc "Diagnostic Trouble Code Information Extended - MSM_RR : Test Not Completed This Operation Cycle";
BA_ "SignalType" SG_ 1211 DTCI_MSM_RR_TstNCmpltdLstClr "ENM";
BA_ "SignalLongName" SG_ 1211 DTCI_MSM_RR_TstNCmpltdLstClr "Diagnostic Trouble Code Information Extended - MSM_RR : Test Not Completed Since Last Clear";
BA_ "SignalType" SG_ 1211 DTCI_MSM_RR_TstFldOpCyc "ENM";
BA_ "SignalLongName" SG_ 1211 DTCI_MSM_RR_TstFldOpCyc "Diagnostic Trouble Code Information Extended - MSM_RR : Test Failed This Operation Cycle";
BA_ "SignalType" SG_ 1211 DTCI_MSM_RR_TstFldLstClr "ENM";
BA_ "SignalLongName" SG_ 1211 DTCI_MSM_RR_TstFldLstClr "Diagnostic Trouble Code Information Extended - MSM_RR : Test Failed Since Last Clear";
BA_ "SignalType" SG_ 1211 DTCI_MSM_RR_TstFld "ENM";
BA_ "SignalLongName" SG_ 1211 DTCI_MSM_RR_TstFld "Diagnostic Trouble Code Information Extended - MSM_RR : Test Failed";
BA_ "SignalType" SG_ 1211 DTCI_MSM_RR_PndngDTC "ENM";
BA_ "SignalLongName" SG_ 1211 DTCI_MSM_RR_PndngDTC "Diagnostic Trouble Code Information Extended - MSM_RR : Pending DTC";
BA_ "SignalType" SG_ 1211 DTCI_MSM_RR_DTCTriggered "ENM";
BA_ "SignalLongName" SG_ 1211 DTCI_MSM_RR_DTCTriggered "Diagnostic Trouble Code Information Extended - MSM_RR : Diagnostic Trouble Code Triggered";
BA_ "SignalType" SG_ 1211 DTCI_MSM_RR_WrnIndTrggrd "ENM";
BA_ "SignalLongName" SG_ 1211 DTCI_MSM_RR_WrnIndTrggrd "Diagnostic Trouble Code Information Extended - MSM_RR : Warning Indicator Triggered";
BA_ "SignalType" SG_ 1211 DTCI_MSM_RR_WrnIndRqd "ENM";
BA_ "SignalLongName" SG_ 1211 DTCI_MSM_RR_WrnIndRqd "Diagnostic Trouble Code Information Extended - MSM_RR : Warning Indicator Requested";
BA_ "SignalLongName" SG_ 1855 DTCI_MTCM_L_DTCFailType "Diagnostic Trouble Code Information Extended - MTCM_L : Diagnostic Trouble Code Failure Type";
BA_ "SignalType" SG_ 1855 DTCI_MTCM_L_CnfrmdDTC "ENM";
BA_ "SignalLongName" SG_ 1855 DTCI_MTCM_L_CnfrmdDTC "Diagnostic Trouble Code Information Extended - MTCM_L : Confirmed DTC";
BA_ "SignalType" SG_ 1855 DTCI_MTCM_L_DTCFaultType "ENM";
BA_ "SignalLongName" SG_ 1855 DTCI_MTCM_L_DTCFaultType "Diagnostic Trouble Code Information Extended - MTCM_L : Diagnostic Trouble Code Fault Type";
BA_ "SignalLongName" SG_ 1855 DTCI_MTCM_L_DTCNumber "Diagnostic Trouble Code Information Extended - MTCM_L : Diagnostic Trouble Code Number";
BA_ "SignalLongName" SG_ 1855 DTCI_MTCM_L_DTCSource "Diagnostic Trouble Code Information Extended - MTCM_L : Diagnostic Trouble Code Source";
BA_ "SignalType" SG_ 1855 DTCI_MTCM_L_TstNCmpltdOpCyc "ENM";
BA_ "SignalLongName" SG_ 1855 DTCI_MTCM_L_TstNCmpltdOpCyc "Diagnostic Trouble Code Information Extended - MTCM_L : Test Not Completed This Operation Cycle";
BA_ "SignalType" SG_ 1855 DTCI_MTCM_L_TstNCmpltdLstClr "ENM";
BA_ "SignalLongName" SG_ 1855 DTCI_MTCM_L_TstNCmpltdLstClr "Diagnostic Trouble Code Information Extended - MTCM_L : Test Not Completed Since Last Clear";
BA_ "SignalType" SG_ 1855 DTCI_MTCM_L_TstFldOpCyc "ENM";
BA_ "SignalLongName" SG_ 1855 DTCI_MTCM_L_TstFldOpCyc "Diagnostic Trouble Code Information Extended - MTCM_L : Test Failed This Operation Cycle";
BA_ "SignalType" SG_ 1855 DTCI_MTCM_L_TstFldLstClr "ENM";
BA_ "SignalLongName" SG_ 1855 DTCI_MTCM_L_TstFldLstClr "Diagnostic Trouble Code Information Extended - MTCM_L : Test Failed Since Last Clear";
BA_ "SignalType" SG_ 1855 DTCI_MTCM_L_TstFld "ENM";
BA_ "SignalLongName" SG_ 1855 DTCI_MTCM_L_TstFld "Diagnostic Trouble Code Information Extended - MTCM_L : Test Failed";
BA_ "SignalType" SG_ 1855 DTCI_MTCM_L_PndngDTC "ENM";
BA_ "SignalLongName" SG_ 1855 DTCI_MTCM_L_PndngDTC "Diagnostic Trouble Code Information Extended - MTCM_L : Pending DTC";
BA_ "SignalType" SG_ 1855 DTCI_MTCM_L_DTCTriggered "ENM";
BA_ "SignalLongName" SG_ 1855 DTCI_MTCM_L_DTCTriggered "Diagnostic Trouble Code Information Extended - MTCM_L : Diagnostic Trouble Code Triggered";
BA_ "SignalType" SG_ 1855 DTCI_MTCM_L_WrnIndTrggrd "ENM";
BA_ "SignalLongName" SG_ 1855 DTCI_MTCM_L_WrnIndTrggrd "Diagnostic Trouble Code Information Extended - MTCM_L : Warning Indicator Triggered";
BA_ "SignalType" SG_ 1855 DTCI_MTCM_L_WrnIndRqd "ENM";
BA_ "SignalLongName" SG_ 1855 DTCI_MTCM_L_WrnIndRqd "Diagnostic Trouble Code Information Extended - MTCM_L : Warning Indicator Requested";
BA_ "SignalLongName" SG_ 1210 DTCI_MTCM_R_DTCFailType "Diagnostic Trouble Code Information Extended - MTCM_R : Diagnostic Trouble Code Failure Type";
BA_ "SignalType" SG_ 1210 DTCI_MTCM_R_CnfrmdDTC "ENM";
BA_ "SignalLongName" SG_ 1210 DTCI_MTCM_R_CnfrmdDTC "Diagnostic Trouble Code Information Extended - MTCM_R : Confirmed DTC";
BA_ "SignalType" SG_ 1210 DTCI_MTCM_R_DTCFaultType "ENM";
BA_ "SignalLongName" SG_ 1210 DTCI_MTCM_R_DTCFaultType "Diagnostic Trouble Code Information Extended - MTCM_R : Diagnostic Trouble Code Fault Type";
BA_ "SignalLongName" SG_ 1210 DTCI_MTCM_R_DTCNumber "Diagnostic Trouble Code Information Extended - MTCM_R : Diagnostic Trouble Code Number";
BA_ "SignalLongName" SG_ 1210 DTCI_MTCM_R_DTCSource "Diagnostic Trouble Code Information Extended - MTCM_R : Diagnostic Trouble Code Source";
BA_ "SignalType" SG_ 1210 DTCI_MTCM_R_TstNCmpltdOpCyc "ENM";
BA_ "SignalLongName" SG_ 1210 DTCI_MTCM_R_TstNCmpltdOpCyc "Diagnostic Trouble Code Information Extended - MTCM_R : Test Not Completed This Operation Cycle";
BA_ "SignalType" SG_ 1210 DTCI_MTCM_R_TstNCmpltdLstClr "ENM";
BA_ "SignalLongName" SG_ 1210 DTCI_MTCM_R_TstNCmpltdLstClr "Diagnostic Trouble Code Information Extended - MTCM_R : Test Not Completed Since Last Clear";
BA_ "SignalType" SG_ 1210 DTCI_MTCM_R_TstFldOpCyc "ENM";
BA_ "SignalLongName" SG_ 1210 DTCI_MTCM_R_TstFldOpCyc "Diagnostic Trouble Code Information Extended - MTCM_R : Test Failed This Operation Cycle";
BA_ "SignalType" SG_ 1210 DTCI_MTCM_R_TstFldLstClr "ENM";
BA_ "SignalLongName" SG_ 1210 DTCI_MTCM_R_TstFldLstClr "Diagnostic Trouble Code Information Extended - MTCM_R : Test Failed Since Last Clear";
BA_ "SignalType" SG_ 1210 DTCI_MTCM_R_TstFld "ENM";
BA_ "SignalLongName" SG_ 1210 DTCI_MTCM_R_TstFld "Diagnostic Trouble Code Information Extended - MTCM_R : Test Failed";
BA_ "SignalType" SG_ 1210 DTCI_MTCM_R_PndngDTC "ENM";
BA_ "SignalLongName" SG_ 1210 DTCI_MTCM_R_PndngDTC "Diagnostic Trouble Code Information Extended - MTCM_R : Pending DTC";
BA_ "SignalType" SG_ 1210 DTCI_MTCM_R_DTCTriggered "ENM";
BA_ "SignalLongName" SG_ 1210 DTCI_MTCM_R_DTCTriggered "Diagnostic Trouble Code Information Extended - MTCM_R : Diagnostic Trouble Code Triggered";
BA_ "SignalType" SG_ 1210 DTCI_MTCM_R_WrnIndTrggrd "ENM";
BA_ "SignalLongName" SG_ 1210 DTCI_MTCM_R_WrnIndTrggrd "Diagnostic Trouble Code Information Extended - MTCM_R : Warning Indicator Triggered";
BA_ "SignalType" SG_ 1210 DTCI_MTCM_R_WrnIndRqd "ENM";
BA_ "SignalLongName" SG_ 1210 DTCI_MTCM_R_WrnIndRqd "Diagnostic Trouble Code Information Extended - MTCM_R : Warning Indicator Requested";
BA_ "SignalLongName" SG_ 1856 DTCI_NVM_DTCFailType "Diagnostic Trouble Code Information Extended - NVM : Diagnostic Trouble Code Failure Type";
BA_ "SignalType" SG_ 1856 DTCI_NVM_CnfrmdDTC "ENM";
BA_ "SignalLongName" SG_ 1856 DTCI_NVM_CnfrmdDTC "Diagnostic Trouble Code Information Extended - NVM : Confirmed DTC";
BA_ "SignalType" SG_ 1856 DTCI_NVM_DTCFaultType "ENM";
BA_ "SignalLongName" SG_ 1856 DTCI_NVM_DTCFaultType "Diagnostic Trouble Code Information Extended - NVM : Diagnostic Trouble Code Fault Type";
BA_ "SignalLongName" SG_ 1856 DTCI_NVM_DTCNumber "Diagnostic Trouble Code Information Extended - NVM : Diagnostic Trouble Code Number";
BA_ "SignalLongName" SG_ 1856 DTCI_NVM_DTCSource "Diagnostic Trouble Code Information Extended - NVM : Diagnostic Trouble Code Source";
BA_ "SignalType" SG_ 1856 DTCI_NVM_TstNCmpltdOpCyc "ENM";
BA_ "SignalLongName" SG_ 1856 DTCI_NVM_TstNCmpltdOpCyc "Diagnostic Trouble Code Information Extended - NVM : Test Not Completed This Operation Cycle";
BA_ "SignalType" SG_ 1856 DTCI_NVM_TstNCmpltdLstClr "ENM";
BA_ "SignalLongName" SG_ 1856 DTCI_NVM_TstNCmpltdLstClr "Diagnostic Trouble Code Information Extended - NVM : Test Not Completed Since Last Clear";
BA_ "SignalType" SG_ 1856 DTCI_NVM_TstFldOpCyc "ENM";
BA_ "SignalLongName" SG_ 1856 DTCI_NVM_TstFldOpCyc "Diagnostic Trouble Code Information Extended - NVM : Test Failed This Operation Cycle";
BA_ "SignalType" SG_ 1856 DTCI_NVM_TstFldLstClr "ENM";
BA_ "SignalLongName" SG_ 1856 DTCI_NVM_TstFldLstClr "Diagnostic Trouble Code Information Extended - NVM : Test Failed Since Last Clear";
BA_ "SignalType" SG_ 1856 DTCI_NVM_TstFld "ENM";
BA_ "SignalLongName" SG_ 1856 DTCI_NVM_TstFld "Diagnostic Trouble Code Information Extended - NVM : Test Failed";
BA_ "SignalType" SG_ 1856 DTCI_NVM_PndngDTC "ENM";
BA_ "SignalLongName" SG_ 1856 DTCI_NVM_PndngDTC "Diagnostic Trouble Code Information Extended - NVM : Pending DTC";
BA_ "SignalType" SG_ 1856 DTCI_NVM_DTCTriggered "ENM";
BA_ "SignalLongName" SG_ 1856 DTCI_NVM_DTCTriggered "Diagnostic Trouble Code Information Extended - NVM : Diagnostic Trouble Code Triggered";
BA_ "SignalType" SG_ 1856 DTCI_NVM_WrnIndTrggrd "ENM";
BA_ "SignalLongName" SG_ 1856 DTCI_NVM_WrnIndTrggrd "Diagnostic Trouble Code Information Extended - NVM : Warning Indicator Triggered";
BA_ "SignalType" SG_ 1856 DTCI_NVM_WrnIndRqd "ENM";
BA_ "SignalLongName" SG_ 1856 DTCI_NVM_WrnIndRqd "Diagnostic Trouble Code Information Extended - NVM : Warning Indicator Requested";
BA_ "SignalLongName" SG_ 1957 DTCI_ODS2_DTCFailType "Diagnostic Trouble Code Information Extended - ODS2 : Diagnostic Trouble Code Failure Type";
BA_ "SignalType" SG_ 1957 DTCI_ODS2_CnfrmdDTC "ENM";
BA_ "SignalLongName" SG_ 1957 DTCI_ODS2_CnfrmdDTC "Diagnostic Trouble Code Information Extended - ODS2 : Confirmed DTC";
BA_ "SignalType" SG_ 1957 DTCI_ODS2_DTCFaultType "ENM";
BA_ "SignalLongName" SG_ 1957 DTCI_ODS2_DTCFaultType "Diagnostic Trouble Code Information Extended - ODS2 : Diagnostic Trouble Code Fault Type";
BA_ "SignalLongName" SG_ 1957 DTCI_ODS2_DTCNumber "Diagnostic Trouble Code Information Extended - ODS2 : Diagnostic Trouble Code Number";
BA_ "SignalLongName" SG_ 1957 DTCI_ODS2_DTCSource "Diagnostic Trouble Code Information Extended - ODS2 : Diagnostic Trouble Code Source";
BA_ "SignalType" SG_ 1957 DTCI_ODS2_TstNCmpltdOpCyc "ENM";
BA_ "SignalLongName" SG_ 1957 DTCI_ODS2_TstNCmpltdOpCyc "Diagnostic Trouble Code Information Extended - ODS2 : Test Not Completed This Operation Cycle";
BA_ "SignalType" SG_ 1957 DTCI_ODS2_TstNCmpltdLstClr "ENM";
BA_ "SignalLongName" SG_ 1957 DTCI_ODS2_TstNCmpltdLstClr "Diagnostic Trouble Code Information Extended - ODS2 : Test Not Completed Since Last Clear";
BA_ "SignalType" SG_ 1957 DTCI_ODS2_TstFldOpCyc "ENM";
BA_ "SignalLongName" SG_ 1957 DTCI_ODS2_TstFldOpCyc "Diagnostic Trouble Code Information Extended - ODS2 : Test Failed This Operation Cycle";
BA_ "SignalType" SG_ 1957 DTCI_ODS2_TstFldLstClr "ENM";
BA_ "SignalLongName" SG_ 1957 DTCI_ODS2_TstFldLstClr "Diagnostic Trouble Code Information Extended - ODS2 : Test Failed Since Last Clear";
BA_ "SignalType" SG_ 1957 DTCI_ODS2_TstFld "ENM";
BA_ "SignalLongName" SG_ 1957 DTCI_ODS2_TstFld "Diagnostic Trouble Code Information Extended - ODS2 : Test Failed";
BA_ "SignalType" SG_ 1957 DTCI_ODS2_PndngDTC "ENM";
BA_ "SignalLongName" SG_ 1957 DTCI_ODS2_PndngDTC "Diagnostic Trouble Code Information Extended - ODS2 : Pending DTC";
BA_ "SignalType" SG_ 1957 DTCI_ODS2_DTCTriggered "ENM";
BA_ "SignalLongName" SG_ 1957 DTCI_ODS2_DTCTriggered "Diagnostic Trouble Code Information Extended - ODS2 : Diagnostic Trouble Code Triggered";
BA_ "SignalType" SG_ 1957 DTCI_ODS2_WrnIndTrggrd "ENM";
BA_ "SignalLongName" SG_ 1957 DTCI_ODS2_WrnIndTrggrd "Diagnostic Trouble Code Information Extended - ODS2 : Warning Indicator Triggered";
BA_ "SignalType" SG_ 1957 DTCI_ODS2_WrnIndRqd "ENM";
BA_ "SignalLongName" SG_ 1957 DTCI_ODS2_WrnIndRqd "Diagnostic Trouble Code Information Extended - ODS2 : Warning Indicator Requested";
BA_ "SignalLongName" SG_ 1111 DTCI_ODS_DTCFailType "Diagnostic Trouble Code Information Extended - ODS : Diagnostic Trouble Code Failure Type";
BA_ "SignalType" SG_ 1111 DTCI_ODS_CnfrmdDTC "ENM";
BA_ "SignalLongName" SG_ 1111 DTCI_ODS_CnfrmdDTC "Diagnostic Trouble Code Information Extended - ODS : Confirmed DTC";
BA_ "SignalType" SG_ 1111 DTCI_ODS_DTCFaultType "ENM";
BA_ "SignalLongName" SG_ 1111 DTCI_ODS_DTCFaultType "Diagnostic Trouble Code Information Extended - ODS : Diagnostic Trouble Code Fault Type";
BA_ "SignalLongName" SG_ 1111 DTCI_ODS_DTCNumber "Diagnostic Trouble Code Information Extended - ODS : Diagnostic Trouble Code Number";
BA_ "SignalLongName" SG_ 1111 DTCI_ODS_DTCSource "Diagnostic Trouble Code Information Extended - ODS : Diagnostic Trouble Code Source";
BA_ "SignalType" SG_ 1111 DTCI_ODS_TstNCmpltdOpCyc "ENM";
BA_ "SignalLongName" SG_ 1111 DTCI_ODS_TstNCmpltdOpCyc "Diagnostic Trouble Code Information Extended - ODS : Test Not Completed This Operation Cycle";
BA_ "SignalType" SG_ 1111 DTCI_ODS_TstNCmpltdLstClr "ENM";
BA_ "SignalLongName" SG_ 1111 DTCI_ODS_TstNCmpltdLstClr "Diagnostic Trouble Code Information Extended - ODS : Test Not Completed Since Last Clear";
BA_ "SignalType" SG_ 1111 DTCI_ODS_TstFldOpCyc "ENM";
BA_ "SignalLongName" SG_ 1111 DTCI_ODS_TstFldOpCyc "Diagnostic Trouble Code Information Extended - ODS : Test Failed This Operation Cycle";
BA_ "SignalType" SG_ 1111 DTCI_ODS_TstFldLstClr "ENM";
BA_ "SignalLongName" SG_ 1111 DTCI_ODS_TstFldLstClr "Diagnostic Trouble Code Information Extended - ODS : Test Failed Since Last Clear";
BA_ "SignalType" SG_ 1111 DTCI_ODS_TstFld "ENM";
BA_ "SignalLongName" SG_ 1111 DTCI_ODS_TstFld "Diagnostic Trouble Code Information Extended - ODS : Test Failed";
BA_ "SignalType" SG_ 1111 DTCI_ODS_PndngDTC "ENM";
BA_ "SignalLongName" SG_ 1111 DTCI_ODS_PndngDTC "Diagnostic Trouble Code Information Extended - ODS : Pending DTC";
BA_ "SignalType" SG_ 1111 DTCI_ODS_DTCTriggered "ENM";
BA_ "SignalLongName" SG_ 1111 DTCI_ODS_DTCTriggered "Diagnostic Trouble Code Information Extended - ODS : Diagnostic Trouble Code Triggered";
BA_ "SignalType" SG_ 1111 DTCI_ODS_WrnIndTrggrd "ENM";
BA_ "SignalLongName" SG_ 1111 DTCI_ODS_WrnIndTrggrd "Diagnostic Trouble Code Information Extended - ODS : Warning Indicator Triggered";
BA_ "SignalType" SG_ 1111 DTCI_ODS_WrnIndRqd "ENM";
BA_ "SignalLongName" SG_ 1111 DTCI_ODS_WrnIndRqd "Diagnostic Trouble Code Information Extended - ODS : Warning Indicator Requested";
BA_ "SignalLongName" SG_ 1209 DTCI_PA_DTCFailType "Diagnostic Trouble Code Information Extended - PA : Diagnostic Trouble Code Failure Type";
BA_ "SignalType" SG_ 1209 DTCI_PA_CnfrmdDTC "ENM";
BA_ "SignalLongName" SG_ 1209 DTCI_PA_CnfrmdDTC "Diagnostic Trouble Code Information Extended - PA : Confirmed DTC";
BA_ "SignalType" SG_ 1209 DTCI_PA_DTCFaultType "ENM";
BA_ "SignalLongName" SG_ 1209 DTCI_PA_DTCFaultType "Diagnostic Trouble Code Information Extended - PA : Diagnostic Trouble Code Fault Type";
BA_ "SignalLongName" SG_ 1209 DTCI_PA_DTCNumber "Diagnostic Trouble Code Information Extended - PA : Diagnostic Trouble Code Number";
BA_ "SignalLongName" SG_ 1209 DTCI_PA_DTCSource "Diagnostic Trouble Code Information Extended - PA : Diagnostic Trouble Code Source";
BA_ "SignalType" SG_ 1209 DTCI_PA_TstNCmpltdOpCyc "ENM";
BA_ "SignalLongName" SG_ 1209 DTCI_PA_TstNCmpltdOpCyc "Diagnostic Trouble Code Information Extended - PA : Test Not Completed This Operation Cycle";
BA_ "SignalType" SG_ 1209 DTCI_PA_TstNCmpltdLstClr "ENM";
BA_ "SignalLongName" SG_ 1209 DTCI_PA_TstNCmpltdLstClr "Diagnostic Trouble Code Information Extended - PA : Test Not Completed Since Last Clear";
BA_ "SignalType" SG_ 1209 DTCI_PA_TstFldOpCyc "ENM";
BA_ "SignalLongName" SG_ 1209 DTCI_PA_TstFldOpCyc "Diagnostic Trouble Code Information Extended - PA : Test Failed This Operation Cycle";
BA_ "SignalType" SG_ 1209 DTCI_PA_TstFldLstClr "ENM";
BA_ "SignalLongName" SG_ 1209 DTCI_PA_TstFldLstClr "Diagnostic Trouble Code Information Extended - PA : Test Failed Since Last Clear";
BA_ "SignalType" SG_ 1209 DTCI_PA_TstFld "ENM";
BA_ "SignalLongName" SG_ 1209 DTCI_PA_TstFld "Diagnostic Trouble Code Information Extended - PA : Test Failed";
BA_ "SignalType" SG_ 1209 DTCI_PA_PndngDTC "ENM";
BA_ "SignalLongName" SG_ 1209 DTCI_PA_PndngDTC "Diagnostic Trouble Code Information Extended - PA : Pending DTC";
BA_ "SignalType" SG_ 1209 DTCI_PA_DTCTriggered "ENM";
BA_ "SignalLongName" SG_ 1209 DTCI_PA_DTCTriggered "Diagnostic Trouble Code Information Extended - PA : Diagnostic Trouble Code Triggered";
BA_ "SignalType" SG_ 1209 DTCI_PA_WrnIndTrggrd "ENM";
BA_ "SignalLongName" SG_ 1209 DTCI_PA_WrnIndTrggrd "Diagnostic Trouble Code Information Extended - PA : Warning Indicator Triggered";
BA_ "SignalType" SG_ 1209 DTCI_PA_WrnIndRqd "ENM";
BA_ "SignalLongName" SG_ 1209 DTCI_PA_WrnIndRqd "Diagnostic Trouble Code Information Extended - PA : Warning Indicator Requested";
BA_ "SignalLongName" SG_ 1170 DTCI_PCM_DTCFailType "Diagnostic Trouble Code Information Extended - PCM : Diagnostic Trouble Code Failure Type";
BA_ "SignalType" SG_ 1170 DTCI_PCM_CnfrmdDTC "ENM";
BA_ "SignalLongName" SG_ 1170 DTCI_PCM_CnfrmdDTC "Diagnostic Trouble Code Information Extended - PCM : Confirmed DTC";
BA_ "SignalType" SG_ 1170 DTCI_PCM_DTCFaultType "ENM";
BA_ "SignalLongName" SG_ 1170 DTCI_PCM_DTCFaultType "Diagnostic Trouble Code Information Extended - PCM : Diagnostic Trouble Code Fault Type";
BA_ "SignalLongName" SG_ 1170 DTCI_PCM_DTCNumber "Diagnostic Trouble Code Information Extended - PCM : Diagnostic Trouble Code Number";
BA_ "SignalLongName" SG_ 1170 DTCI_PCM_DTCSource "Diagnostic Trouble Code Information Extended - PCM : Diagnostic Trouble Code Source";
BA_ "SignalType" SG_ 1170 DTCI_PCM_TstNCmpltdOpCyc "ENM";
BA_ "SignalLongName" SG_ 1170 DTCI_PCM_TstNCmpltdOpCyc "Diagnostic Trouble Code Information Extended - PCM : Test Not Completed This Operation Cycle";
BA_ "SignalType" SG_ 1170 DTCI_PCM_TstNCmpltdLstClr "ENM";
BA_ "SignalLongName" SG_ 1170 DTCI_PCM_TstNCmpltdLstClr "Diagnostic Trouble Code Information Extended - PCM : Test Not Completed Since Last Clear";
BA_ "SignalType" SG_ 1170 DTCI_PCM_TstFldOpCyc "ENM";
BA_ "SignalLongName" SG_ 1170 DTCI_PCM_TstFldOpCyc "Diagnostic Trouble Code Information Extended - PCM : Test Failed This Operation Cycle";
BA_ "SignalType" SG_ 1170 DTCI_PCM_TstFldLstClr "ENM";
BA_ "SignalLongName" SG_ 1170 DTCI_PCM_TstFldLstClr "Diagnostic Trouble Code Information Extended - PCM : Test Failed Since Last Clear";
BA_ "SignalType" SG_ 1170 DTCI_PCM_TstFld "ENM";
BA_ "SignalLongName" SG_ 1170 DTCI_PCM_TstFld "Diagnostic Trouble Code Information Extended - PCM : Test Failed";
BA_ "SignalType" SG_ 1170 DTCI_PCM_PndngDTC "ENM";
BA_ "SignalLongName" SG_ 1170 DTCI_PCM_PndngDTC "Diagnostic Trouble Code Information Extended - PCM : Pending DTC";
BA_ "SignalType" SG_ 1170 DTCI_PCM_DTCTriggered "ENM";
BA_ "SignalLongName" SG_ 1170 DTCI_PCM_DTCTriggered "Diagnostic Trouble Code Information Extended - PCM : Diagnostic Trouble Code Triggered";
BA_ "SignalType" SG_ 1170 DTCI_PCM_WrnIndTrggrd "ENM";
BA_ "SignalLongName" SG_ 1170 DTCI_PCM_WrnIndTrggrd "Diagnostic Trouble Code Information Extended - PCM : Warning Indicator Triggered";
BA_ "SignalType" SG_ 1170 DTCI_PCM_WrnIndRqd "ENM";
BA_ "SignalLongName" SG_ 1170 DTCI_PCM_WrnIndRqd "Diagnostic Trouble Code Information Extended - PCM : Warning Indicator Requested";
BA_ "SignalLongName" SG_ 1857 DTCI_PDR_DTCFailType "Diagnostic Trouble Code Information Extended - PDR : Diagnostic Trouble Code Failure Type";
BA_ "SignalType" SG_ 1857 DTCI_PDR_CnfrmdDTC "ENM";
BA_ "SignalLongName" SG_ 1857 DTCI_PDR_CnfrmdDTC "Diagnostic Trouble Code Information Extended - PDR : Confirmed DTC";
BA_ "SignalType" SG_ 1857 DTCI_PDR_DTCFaultType "ENM";
BA_ "SignalLongName" SG_ 1857 DTCI_PDR_DTCFaultType "Diagnostic Trouble Code Information Extended - PDR : Diagnostic Trouble Code Fault Type";
BA_ "SignalLongName" SG_ 1857 DTCI_PDR_DTCNumber "Diagnostic Trouble Code Information Extended - PDR : Diagnostic Trouble Code Number";
BA_ "SignalLongName" SG_ 1857 DTCI_PDR_DTCSource "Diagnostic Trouble Code Information Extended - PDR : Diagnostic Trouble Code Source";
BA_ "SignalType" SG_ 1857 DTCI_PDR_TstNCmpltdOpCyc "ENM";
BA_ "SignalLongName" SG_ 1857 DTCI_PDR_TstNCmpltdOpCyc "Diagnostic Trouble Code Information Extended - PDR : Test Not Completed This Operation Cycle";
BA_ "SignalType" SG_ 1857 DTCI_PDR_TstNCmpltdLstClr "ENM";
BA_ "SignalLongName" SG_ 1857 DTCI_PDR_TstNCmpltdLstClr "Diagnostic Trouble Code Information Extended - PDR : Test Not Completed Since Last Clear";
BA_ "SignalType" SG_ 1857 DTCI_PDR_TstFldOpCyc "ENM";
BA_ "SignalLongName" SG_ 1857 DTCI_PDR_TstFldOpCyc "Diagnostic Trouble Code Information Extended - PDR : Test Failed This Operation Cycle";
BA_ "SignalType" SG_ 1857 DTCI_PDR_TstFldLstClr "ENM";
BA_ "SignalLongName" SG_ 1857 DTCI_PDR_TstFldLstClr "Diagnostic Trouble Code Information Extended - PDR : Test Failed Since Last Clear";
BA_ "SignalType" SG_ 1857 DTCI_PDR_TstFld "ENM";
BA_ "SignalLongName" SG_ 1857 DTCI_PDR_TstFld "Diagnostic Trouble Code Information Extended - PDR : Test Failed";
BA_ "SignalType" SG_ 1857 DTCI_PDR_PndngDTC "ENM";
BA_ "SignalLongName" SG_ 1857 DTCI_PDR_PndngDTC "Diagnostic Trouble Code Information Extended - PDR : Pending DTC";
BA_ "SignalType" SG_ 1857 DTCI_PDR_DTCTriggered "ENM";
BA_ "SignalLongName" SG_ 1857 DTCI_PDR_DTCTriggered "Diagnostic Trouble Code Information Extended - PDR : Diagnostic Trouble Code Triggered";
BA_ "SignalType" SG_ 1857 DTCI_PDR_WrnIndTrggrd "ENM";
BA_ "SignalLongName" SG_ 1857 DTCI_PDR_WrnIndTrggrd "Diagnostic Trouble Code Information Extended - PDR : Warning Indicator Triggered";
BA_ "SignalType" SG_ 1857 DTCI_PDR_WrnIndRqd "ENM";
BA_ "SignalLongName" SG_ 1857 DTCI_PDR_WrnIndRqd "Diagnostic Trouble Code Information Extended - PDR : Warning Indicator Requested";
BA_ "SignalLongName" SG_ 1168 DTCI_PFCM_DTCFailType "Diagnostic Trouble Code Information Extended - PFCM : Diagnostic Trouble Code Failure Type";
BA_ "SignalType" SG_ 1168 DTCI_PFCM_CnfrmdDTC "ENM";
BA_ "SignalLongName" SG_ 1168 DTCI_PFCM_CnfrmdDTC "Diagnostic Trouble Code Information Extended - PFCM : Confirmed DTC";
BA_ "SignalType" SG_ 1168 DTCI_PFCM_DTCFaultType "ENM";
BA_ "SignalLongName" SG_ 1168 DTCI_PFCM_DTCFaultType "Diagnostic Trouble Code Information Extended - PFCM : Diagnostic Trouble Code Fault Type";
BA_ "SignalLongName" SG_ 1168 DTCI_PFCM_DTCNumber "Diagnostic Trouble Code Information Extended - PFCM : Diagnostic Trouble Code Number";
BA_ "SignalLongName" SG_ 1168 DTCI_PFCM_DTCSource "Diagnostic Trouble Code Information Extended - PFCM : Diagnostic Trouble Code Source";
BA_ "SignalType" SG_ 1168 DTCI_PFCM_TstNCmpltdOpCyc "ENM";
BA_ "SignalLongName" SG_ 1168 DTCI_PFCM_TstNCmpltdOpCyc "Diagnostic Trouble Code Information Extended - PFCM : Test Not Completed This Operation Cycle";
BA_ "SignalType" SG_ 1168 DTCI_PFCM_TstNCmpltdLstClr "ENM";
BA_ "SignalLongName" SG_ 1168 DTCI_PFCM_TstNCmpltdLstClr "Diagnostic Trouble Code Information Extended - PFCM : Test Not Completed Since Last Clear";
BA_ "SignalType" SG_ 1168 DTCI_PFCM_TstFldOpCyc "ENM";
BA_ "SignalLongName" SG_ 1168 DTCI_PFCM_TstFldOpCyc "Diagnostic Trouble Code Information Extended - PFCM : Test Failed This Operation Cycle";
BA_ "SignalType" SG_ 1168 DTCI_PFCM_TstFldLstClr "ENM";
BA_ "SignalLongName" SG_ 1168 DTCI_PFCM_TstFldLstClr "Diagnostic Trouble Code Information Extended - PFCM : Test Failed Since Last Clear";
BA_ "SignalType" SG_ 1168 DTCI_PFCM_TstFld "ENM";
BA_ "SignalLongName" SG_ 1168 DTCI_PFCM_TstFld "Diagnostic Trouble Code Information Extended - PFCM : Test Failed";
BA_ "SignalType" SG_ 1168 DTCI_PFCM_PndngDTC "ENM";
BA_ "SignalLongName" SG_ 1168 DTCI_PFCM_PndngDTC "Diagnostic Trouble Code Information Extended - PFCM : Pending DTC";
BA_ "SignalType" SG_ 1168 DTCI_PFCM_DTCTriggered "ENM";
BA_ "SignalLongName" SG_ 1168 DTCI_PFCM_DTCTriggered "Diagnostic Trouble Code Information Extended - PFCM : Diagnostic Trouble Code Triggered";
BA_ "SignalType" SG_ 1168 DTCI_PFCM_WrnIndTrggrd "ENM";
BA_ "SignalLongName" SG_ 1168 DTCI_PFCM_WrnIndTrggrd "Diagnostic Trouble Code Information Extended - PFCM : Warning Indicator Triggered";
BA_ "SignalType" SG_ 1168 DTCI_PFCM_WrnIndRqd "ENM";
BA_ "SignalLongName" SG_ 1168 DTCI_PFCM_WrnIndRqd "Diagnostic Trouble Code Information Extended - PFCM : Warning Indicator Requested";
BA_ "SignalLongName" SG_ 1099 DTCI_PLCM_DTCFailType "Diagnostic Trouble Code Information Extended - PLCM : Diagnostic Trouble Code Failure Type";
BA_ "SignalType" SG_ 1099 DTCI_PLCM_CnfrmdDTC "ENM";
BA_ "SignalLongName" SG_ 1099 DTCI_PLCM_CnfrmdDTC "Diagnostic Trouble Code Information Extended - PLCM : Confirmed DTC";
BA_ "SignalType" SG_ 1099 DTCI_PLCM_DTCFaultType "ENM";
BA_ "SignalLongName" SG_ 1099 DTCI_PLCM_DTCFaultType "Diagnostic Trouble Code Information Extended - PLCM : Diagnostic Trouble Code Fault Type";
BA_ "SignalLongName" SG_ 1099 DTCI_PLCM_DTCNumber "Diagnostic Trouble Code Information Extended - PLCM : Diagnostic Trouble Code Number";
BA_ "SignalLongName" SG_ 1099 DTCI_PLCM_DTCSource "Diagnostic Trouble Code Information Extended - PLCM : Diagnostic Trouble Code Source";
BA_ "SignalType" SG_ 1099 DTCI_PLCM_TstNCmpltdOpCyc "ENM";
BA_ "SignalLongName" SG_ 1099 DTCI_PLCM_TstNCmpltdOpCyc "Diagnostic Trouble Code Information Extended - PLCM : Test Not Completed This Operation Cycle";
BA_ "SignalType" SG_ 1099 DTCI_PLCM_TstNCmpltdLstClr "ENM";
BA_ "SignalLongName" SG_ 1099 DTCI_PLCM_TstNCmpltdLstClr "Diagnostic Trouble Code Information Extended - PLCM : Test Not Completed Since Last Clear";
BA_ "SignalType" SG_ 1099 DTCI_PLCM_TstFldOpCyc "ENM";
BA_ "SignalLongName" SG_ 1099 DTCI_PLCM_TstFldOpCyc "Diagnostic Trouble Code Information Extended - PLCM : Test Failed This Operation Cycle";
BA_ "SignalType" SG_ 1099 DTCI_PLCM_TstFldLstClr "ENM";
BA_ "SignalLongName" SG_ 1099 DTCI_PLCM_TstFldLstClr "Diagnostic Trouble Code Information Extended - PLCM : Test Failed Since Last Clear";
BA_ "SignalType" SG_ 1099 DTCI_PLCM_TstFld "ENM";
BA_ "SignalLongName" SG_ 1099 DTCI_PLCM_TstFld "Diagnostic Trouble Code Information Extended - PLCM : Test Failed";
BA_ "SignalType" SG_ 1099 DTCI_PLCM_PndngDTC "ENM";
BA_ "SignalLongName" SG_ 1099 DTCI_PLCM_PndngDTC "Diagnostic Trouble Code Information Extended - PLCM : Pending DTC";
BA_ "SignalType" SG_ 1099 DTCI_PLCM_DTCTriggered "ENM";
BA_ "SignalLongName" SG_ 1099 DTCI_PLCM_DTCTriggered "Diagnostic Trouble Code Information Extended - PLCM : Diagnostic Trouble Code Triggered";
BA_ "SignalType" SG_ 1099 DTCI_PLCM_WrnIndTrggrd "ENM";
BA_ "SignalLongName" SG_ 1099 DTCI_PLCM_WrnIndTrggrd "Diagnostic Trouble Code Information Extended - PLCM : Warning Indicator Triggered";
BA_ "SignalType" SG_ 1099 DTCI_PLCM_WrnIndRqd "ENM";
BA_ "SignalLongName" SG_ 1099 DTCI_PLCM_WrnIndRqd "Diagnostic Trouble Code Information Extended - PLCM : Warning Indicator Requested";
BA_ "SignalLongName" SG_ 1208 DTCI_PTM_DTCFailType "Diagnostic Trouble Code Information Extended - PTM : Diagnostic Trouble Code Failure Type";
BA_ "SignalType" SG_ 1208 DTCI_PTM_CnfrmdDTC "ENM";
BA_ "SignalLongName" SG_ 1208 DTCI_PTM_CnfrmdDTC "Diagnostic Trouble Code Information Extended - PTM : Confirmed DTC";
BA_ "SignalType" SG_ 1208 DTCI_PTM_DTCFaultType "ENM";
BA_ "SignalLongName" SG_ 1208 DTCI_PTM_DTCFaultType "Diagnostic Trouble Code Information Extended - PTM : Diagnostic Trouble Code Fault Type";
BA_ "SignalLongName" SG_ 1208 DTCI_PTM_DTCNumber "Diagnostic Trouble Code Information Extended - PTM : Diagnostic Trouble Code Number";
BA_ "SignalLongName" SG_ 1208 DTCI_PTM_DTCSource "Diagnostic Trouble Code Information Extended - PTM : Diagnostic Trouble Code Source";
BA_ "SignalType" SG_ 1208 DTCI_PTM_TstNCmpltdOpCyc "ENM";
BA_ "SignalLongName" SG_ 1208 DTCI_PTM_TstNCmpltdOpCyc "Diagnostic Trouble Code Information Extended - PTM : Test Not Completed This Operation Cycle";
BA_ "SignalType" SG_ 1208 DTCI_PTM_TstNCmpltdLstClr "ENM";
BA_ "SignalLongName" SG_ 1208 DTCI_PTM_TstNCmpltdLstClr "Diagnostic Trouble Code Information Extended - PTM : Test Not Completed Since Last Clear";
BA_ "SignalType" SG_ 1208 DTCI_PTM_TstFldOpCyc "ENM";
BA_ "SignalLongName" SG_ 1208 DTCI_PTM_TstFldOpCyc "Diagnostic Trouble Code Information Extended - PTM : Test Failed This Operation Cycle";
BA_ "SignalType" SG_ 1208 DTCI_PTM_TstFldLstClr "ENM";
BA_ "SignalLongName" SG_ 1208 DTCI_PTM_TstFldLstClr "Diagnostic Trouble Code Information Extended - PTM : Test Failed Since Last Clear";
BA_ "SignalType" SG_ 1208 DTCI_PTM_TstFld "ENM";
BA_ "SignalLongName" SG_ 1208 DTCI_PTM_TstFld "Diagnostic Trouble Code Information Extended - PTM : Test Failed";
BA_ "SignalType" SG_ 1208 DTCI_PTM_PndngDTC "ENM";
BA_ "SignalLongName" SG_ 1208 DTCI_PTM_PndngDTC "Diagnostic Trouble Code Information Extended - PTM : Pending DTC";
BA_ "SignalType" SG_ 1208 DTCI_PTM_DTCTriggered "ENM";
BA_ "SignalLongName" SG_ 1208 DTCI_PTM_DTCTriggered "Diagnostic Trouble Code Information Extended - PTM : Diagnostic Trouble Code Triggered";
BA_ "SignalType" SG_ 1208 DTCI_PTM_WrnIndTrggrd "ENM";
BA_ "SignalLongName" SG_ 1208 DTCI_PTM_WrnIndTrggrd "Diagnostic Trouble Code Information Extended - PTM : Warning Indicator Triggered";
BA_ "SignalType" SG_ 1208 DTCI_PTM_WrnIndRqd "ENM";
BA_ "SignalLongName" SG_ 1208 DTCI_PTM_WrnIndRqd "Diagnostic Trouble Code Information Extended - PTM : Warning Indicator Requested";
BA_ "SignalLongName" SG_ 1858 DTCI_RDCM_DTCFailType "Diagnostic Trouble Code Information Extended - RDCM : Diagnostic Trouble Code Failure Type";
BA_ "SignalType" SG_ 1858 DTCI_RDCM_CnfrmdDTC "ENM";
BA_ "SignalLongName" SG_ 1858 DTCI_RDCM_CnfrmdDTC "Diagnostic Trouble Code Information Extended - RDCM : Confirmed DTC";
BA_ "SignalType" SG_ 1858 DTCI_RDCM_DTCFaultType "ENM";
BA_ "SignalLongName" SG_ 1858 DTCI_RDCM_DTCFaultType "Diagnostic Trouble Code Information Extended - RDCM : Diagnostic Trouble Code Fault Type";
BA_ "SignalLongName" SG_ 1858 DTCI_RDCM_DTCNumber "Diagnostic Trouble Code Information Extended - RDCM : Diagnostic Trouble Code Number";
BA_ "SignalLongName" SG_ 1858 DTCI_RDCM_DTCSource "Diagnostic Trouble Code Information Extended - RDCM : Diagnostic Trouble Code Source";
BA_ "SignalType" SG_ 1858 DTCI_RDCM_TstNCmpltdOpCyc "ENM";
BA_ "SignalLongName" SG_ 1858 DTCI_RDCM_TstNCmpltdOpCyc "Diagnostic Trouble Code Information Extended - RDCM : Test Not Completed This Operation Cycle";
BA_ "SignalType" SG_ 1858 DTCI_RDCM_TstNCmpltdLstClr "ENM";
BA_ "SignalLongName" SG_ 1858 DTCI_RDCM_TstNCmpltdLstClr "Diagnostic Trouble Code Information Extended - RDCM : Test Not Completed Since Last Clear";
BA_ "SignalType" SG_ 1858 DTCI_RDCM_TstFldOpCyc "ENM";
BA_ "SignalLongName" SG_ 1858 DTCI_RDCM_TstFldOpCyc "Diagnostic Trouble Code Information Extended - RDCM : Test Failed This Operation Cycle";
BA_ "SignalType" SG_ 1858 DTCI_RDCM_TstFldLstClr "ENM";
BA_ "SignalLongName" SG_ 1858 DTCI_RDCM_TstFldLstClr "Diagnostic Trouble Code Information Extended - RDCM : Test Failed Since Last Clear";
BA_ "SignalType" SG_ 1858 DTCI_RDCM_TstFld "ENM";
BA_ "SignalLongName" SG_ 1858 DTCI_RDCM_TstFld "Diagnostic Trouble Code Information Extended - RDCM : Test Failed";
BA_ "SignalType" SG_ 1858 DTCI_RDCM_PndngDTC "ENM";
BA_ "SignalLongName" SG_ 1858 DTCI_RDCM_PndngDTC "Diagnostic Trouble Code Information Extended - RDCM : Pending DTC";
BA_ "SignalType" SG_ 1858 DTCI_RDCM_DTCTriggered "ENM";
BA_ "SignalLongName" SG_ 1858 DTCI_RDCM_DTCTriggered "Diagnostic Trouble Code Information Extended - RDCM : Diagnostic Trouble Code Triggered";
BA_ "SignalType" SG_ 1858 DTCI_RDCM_WrnIndTrggrd "ENM";
BA_ "SignalLongName" SG_ 1858 DTCI_RDCM_WrnIndTrggrd "Diagnostic Trouble Code Information Extended - RDCM : Warning Indicator Triggered";
BA_ "SignalType" SG_ 1858 DTCI_RDCM_WrnIndRqd "ENM";
BA_ "SignalLongName" SG_ 1858 DTCI_RDCM_WrnIndRqd "Diagnostic Trouble Code Information Extended - RDCM : Warning Indicator Requested";
BA_ "SignalLongName" SG_ 1918 DTCI_RSI_DTCFailType "Diagnostic Trouble Code Information Extended - RSI : Diagnostic Trouble Code Failure Type";
BA_ "SignalType" SG_ 1918 DTCI_RSI_CnfrmdDTC "ENM";
BA_ "SignalLongName" SG_ 1918 DTCI_RSI_CnfrmdDTC "Diagnostic Trouble Code Information Extended - RSI : Confirmed DTC";
BA_ "SignalType" SG_ 1918 DTCI_RSI_DTCFaultType "ENM";
BA_ "SignalLongName" SG_ 1918 DTCI_RSI_DTCFaultType "Diagnostic Trouble Code Information Extended - RSI : Diagnostic Trouble Code Fault Type";
BA_ "SignalLongName" SG_ 1918 DTCI_RSI_DTCNumber "Diagnostic Trouble Code Information Extended - RSI : Diagnostic Trouble Code Number";
BA_ "SignalLongName" SG_ 1918 DTCI_RSI_DTCSource "Diagnostic Trouble Code Information Extended - RSI : Diagnostic Trouble Code Source";
BA_ "SignalType" SG_ 1918 DTCI_RSI_TstNCmpltdOpCyc "ENM";
BA_ "SignalLongName" SG_ 1918 DTCI_RSI_TstNCmpltdOpCyc "Diagnostic Trouble Code Information Extended - RSI : Test Not Completed This Operation Cycle";
BA_ "SignalType" SG_ 1918 DTCI_RSI_TstNCmpltdLstClr "ENM";
BA_ "SignalLongName" SG_ 1918 DTCI_RSI_TstNCmpltdLstClr "Diagnostic Trouble Code Information Extended - RSI : Test Not Completed Since Last Clear";
BA_ "SignalType" SG_ 1918 DTCI_RSI_TstFldOpCyc "ENM";
BA_ "SignalLongName" SG_ 1918 DTCI_RSI_TstFldOpCyc "Diagnostic Trouble Code Information Extended - RSI : Test Failed This Operation Cycle";
BA_ "SignalType" SG_ 1918 DTCI_RSI_TstFldLstClr "ENM";
BA_ "SignalLongName" SG_ 1918 DTCI_RSI_TstFldLstClr "Diagnostic Trouble Code Information Extended - RSI : Test Failed Since Last Clear";
BA_ "SignalType" SG_ 1918 DTCI_RSI_TstFld "ENM";
BA_ "SignalLongName" SG_ 1918 DTCI_RSI_TstFld "Diagnostic Trouble Code Information Extended - RSI : Test Failed";
BA_ "SignalType" SG_ 1918 DTCI_RSI_PndngDTC "ENM";
BA_ "SignalLongName" SG_ 1918 DTCI_RSI_PndngDTC "Diagnostic Trouble Code Information Extended - RSI : Pending DTC";
BA_ "SignalType" SG_ 1918 DTCI_RSI_DTCTriggered "ENM";
BA_ "SignalLongName" SG_ 1918 DTCI_RSI_DTCTriggered "Diagnostic Trouble Code Information Extended - RSI : Diagnostic Trouble Code Triggered";
BA_ "SignalType" SG_ 1918 DTCI_RSI_WrnIndTrggrd "ENM";
BA_ "SignalLongName" SG_ 1918 DTCI_RSI_WrnIndTrggrd "Diagnostic Trouble Code Information Extended - RSI : Warning Indicator Triggered";
BA_ "SignalType" SG_ 1918 DTCI_RSI_WrnIndRqd "ENM";
BA_ "SignalLongName" SG_ 1918 DTCI_RSI_WrnIndRqd "Diagnostic Trouble Code Information Extended - RSI : Warning Indicator Requested";
BA_ "SignalLongName" SG_ 1859 DTCI_RadioLow_DTCFailType "Diagnostic Trouble Code Information Extended - RadioLow : Diagnostic Trouble Code Failure Type";
BA_ "SignalType" SG_ 1859 DTCI_RadioLow_CnfrmdDTC "ENM";
BA_ "SignalLongName" SG_ 1859 DTCI_RadioLow_CnfrmdDTC "Diagnostic Trouble Code Information Extended - RadioLow : Confirmed DTC";
BA_ "SignalType" SG_ 1859 DTCI_RadioLow_DTCFaultType "ENM";
BA_ "SignalLongName" SG_ 1859 DTCI_RadioLow_DTCFaultType "Diagnostic Trouble Code Information Extended - RadioLow : Diagnostic Trouble Code Fault Type";
BA_ "SignalLongName" SG_ 1859 DTCI_RadioLow_DTCNumber "Diagnostic Trouble Code Information Extended - RadioLow : Diagnostic Trouble Code Number";
BA_ "SignalLongName" SG_ 1859 DTCI_RadioLow_DTCSource "Diagnostic Trouble Code Information Extended - RadioLow : Diagnostic Trouble Code Source";
BA_ "SignalType" SG_ 1859 DTCI_RadioLow_TstNCmpltdOpCyc "ENM";
BA_ "SignalLongName" SG_ 1859 DTCI_RadioLow_TstNCmpltdOpCyc "Diagnostic Trouble Code Information Extended - RadioLow : Test Not Completed This Operation Cycle";
BA_ "SignalType" SG_ 1859 DTCI_RadioLow_TstNCmpltdLstClr "ENM";
BA_ "SignalLongName" SG_ 1859 DTCI_RadioLow_TstNCmpltdLstClr "Diagnostic Trouble Code Information Extended - RadioLow : Test Not Completed Since Last Clear";
BA_ "SignalType" SG_ 1859 DTCI_RadioLow_TstFldOpCyc "ENM";
BA_ "SignalLongName" SG_ 1859 DTCI_RadioLow_TstFldOpCyc "Diagnostic Trouble Code Information Extended - RadioLow : Test Failed This Operation Cycle";
BA_ "SignalType" SG_ 1859 DTCI_RadioLow_TstFldLstClr "ENM";
BA_ "SignalLongName" SG_ 1859 DTCI_RadioLow_TstFldLstClr "Diagnostic Trouble Code Information Extended - RadioLow : Test Failed Since Last Clear";
BA_ "SignalType" SG_ 1859 DTCI_RadioLow_TstFld "ENM";
BA_ "SignalLongName" SG_ 1859 DTCI_RadioLow_TstFld "Diagnostic Trouble Code Information Extended - RadioLow : Test Failed";
BA_ "SignalType" SG_ 1859 DTCI_RadioLow_PndngDTC "ENM";
BA_ "SignalLongName" SG_ 1859 DTCI_RadioLow_PndngDTC "Diagnostic Trouble Code Information Extended - RadioLow : Pending DTC";
BA_ "SignalType" SG_ 1859 DTCI_RadioLow_DTCTriggered "ENM";
BA_ "SignalLongName" SG_ 1859 DTCI_RadioLow_DTCTriggered "Diagnostic Trouble Code Information Extended - RadioLow : Diagnostic Trouble Code Triggered";
BA_ "SignalType" SG_ 1859 DTCI_RadioLow_WrnIndTrggrd "ENM";
BA_ "SignalLongName" SG_ 1859 DTCI_RadioLow_WrnIndTrggrd "Diagnostic Trouble Code Information Extended - RadioLow : Warning Indicator Triggered";
BA_ "SignalType" SG_ 1859 DTCI_RadioLow_WrnIndRqd "ENM";
BA_ "SignalLongName" SG_ 1859 DTCI_RadioLow_WrnIndRqd "Diagnostic Trouble Code Information Extended - RadioLow : Warning Indicator Requested";
BA_ "SignalLongName" SG_ 1206 DTCI_SADS_DTCFailType "Diagnostic Trouble Code Information Extended - SADS : Diagnostic Trouble Code Failure Type";
BA_ "SignalType" SG_ 1206 DTCI_SADS_CnfrmdDTC "ENM";
BA_ "SignalLongName" SG_ 1206 DTCI_SADS_CnfrmdDTC "Diagnostic Trouble Code Information Extended - SADS : Confirmed DTC";
BA_ "SignalType" SG_ 1206 DTCI_SADS_DTCFaultType "ENM";
BA_ "SignalLongName" SG_ 1206 DTCI_SADS_DTCFaultType "Diagnostic Trouble Code Information Extended - SADS : Diagnostic Trouble Code Fault Type";
BA_ "SignalLongName" SG_ 1206 DTCI_SADS_DTCNumber "Diagnostic Trouble Code Information Extended - SADS : Diagnostic Trouble Code Number";
BA_ "SignalLongName" SG_ 1206 DTCI_SADS_DTCSource "Diagnostic Trouble Code Information Extended - SADS : Diagnostic Trouble Code Source";
BA_ "SignalType" SG_ 1206 DTCI_SADS_TstNCmpltdOpCyc "ENM";
BA_ "SignalLongName" SG_ 1206 DTCI_SADS_TstNCmpltdOpCyc "Diagnostic Trouble Code Information Extended - SADS : Test Not Completed This Operation Cycle";
BA_ "SignalType" SG_ 1206 DTCI_SADS_TstNCmpltdLstClr "ENM";
BA_ "SignalLongName" SG_ 1206 DTCI_SADS_TstNCmpltdLstClr "Diagnostic Trouble Code Information Extended - SADS : Test Not Completed Since Last Clear";
BA_ "SignalType" SG_ 1206 DTCI_SADS_TstFldOpCyc "ENM";
BA_ "SignalLongName" SG_ 1206 DTCI_SADS_TstFldOpCyc "Diagnostic Trouble Code Information Extended - SADS : Test Failed This Operation Cycle";
BA_ "SignalType" SG_ 1206 DTCI_SADS_TstFldLstClr "ENM";
BA_ "SignalLongName" SG_ 1206 DTCI_SADS_TstFldLstClr "Diagnostic Trouble Code Information Extended - SADS : Test Failed Since Last Clear";
BA_ "SignalType" SG_ 1206 DTCI_SADS_TstFld "ENM";
BA_ "SignalLongName" SG_ 1206 DTCI_SADS_TstFld "Diagnostic Trouble Code Information Extended - SADS : Test Failed";
BA_ "SignalType" SG_ 1206 DTCI_SADS_PndngDTC "ENM";
BA_ "SignalLongName" SG_ 1206 DTCI_SADS_PndngDTC "Diagnostic Trouble Code Information Extended - SADS : Pending DTC";
BA_ "SignalType" SG_ 1206 DTCI_SADS_DTCTriggered "ENM";
BA_ "SignalLongName" SG_ 1206 DTCI_SADS_DTCTriggered "Diagnostic Trouble Code Information Extended - SADS : Diagnostic Trouble Code Triggered";
BA_ "SignalType" SG_ 1206 DTCI_SADS_WrnIndTrggrd "ENM";
BA_ "SignalLongName" SG_ 1206 DTCI_SADS_WrnIndTrggrd "Diagnostic Trouble Code Information Extended - SADS : Warning Indicator Triggered";
BA_ "SignalType" SG_ 1206 DTCI_SADS_WrnIndRqd "ENM";
BA_ "SignalLongName" SG_ 1206 DTCI_SADS_WrnIndRqd "Diagnostic Trouble Code Information Extended - SADS : Warning Indicator Requested";
BA_ "SignalLongName" SG_ 1956 DTCI_SAM_BH_DTCFailType "Diagnostic Trouble Code Information Extended - SAM_BH : Diagnostic Trouble Code Failure Type";
BA_ "SignalType" SG_ 1956 DTCI_SAM_BH_CnfrmdDTC "ENM";
BA_ "SignalLongName" SG_ 1956 DTCI_SAM_BH_CnfrmdDTC "Diagnostic Trouble Code Information Extended - SAM_BH : Confirmed DTC";
BA_ "SignalType" SG_ 1956 DTCI_SAM_BH_DTCFaultType "ENM";
BA_ "SignalLongName" SG_ 1956 DTCI_SAM_BH_DTCFaultType "Diagnostic Trouble Code Information Extended - SAM_BH : Diagnostic Trouble Code Fault Type";
BA_ "SignalLongName" SG_ 1956 DTCI_SAM_BH_DTCNumber "Diagnostic Trouble Code Information Extended - SAM_BH : Diagnostic Trouble Code Number";
BA_ "SignalLongName" SG_ 1956 DTCI_SAM_BH_DTCSource "Diagnostic Trouble Code Information Extended - SAM_BH : Diagnostic Trouble Code Source";
BA_ "SignalType" SG_ 1956 DTCI_SAM_BH_TstNCmpltdOpCyc "ENM";
BA_ "SignalLongName" SG_ 1956 DTCI_SAM_BH_TstNCmpltdOpCyc "Diagnostic Trouble Code Information Extended - SAM_BH : Test Not Completed This Operation Cycle";
BA_ "SignalType" SG_ 1956 DTCI_SAM_BH_TstNCmpltdLstClr "ENM";
BA_ "SignalLongName" SG_ 1956 DTCI_SAM_BH_TstNCmpltdLstClr "Diagnostic Trouble Code Information Extended - SAM_BH : Test Not Completed Since Last Clear";
BA_ "SignalType" SG_ 1956 DTCI_SAM_BH_TstFldOpCyc "ENM";
BA_ "SignalLongName" SG_ 1956 DTCI_SAM_BH_TstFldOpCyc "Diagnostic Trouble Code Information Extended - SAM_BH : Test Failed This Operation Cycle";
BA_ "SignalType" SG_ 1956 DTCI_SAM_BH_TstFldLstClr "ENM";
BA_ "SignalLongName" SG_ 1956 DTCI_SAM_BH_TstFldLstClr "Diagnostic Trouble Code Information Extended - SAM_BH : Test Failed Since Last Clear";
BA_ "SignalType" SG_ 1956 DTCI_SAM_BH_TstFld "ENM";
BA_ "SignalLongName" SG_ 1956 DTCI_SAM_BH_TstFld "Diagnostic Trouble Code Information Extended - SAM_BH : Test Failed";
BA_ "SignalType" SG_ 1956 DTCI_SAM_BH_PndngDTC "ENM";
BA_ "SignalLongName" SG_ 1956 DTCI_SAM_BH_PndngDTC "Diagnostic Trouble Code Information Extended - SAM_BH : Pending DTC";
BA_ "SignalType" SG_ 1956 DTCI_SAM_BH_DTCTriggered "ENM";
BA_ "SignalLongName" SG_ 1956 DTCI_SAM_BH_DTCTriggered "Diagnostic Trouble Code Information Extended - SAM_BH : Diagnostic Trouble Code Triggered";
BA_ "SignalType" SG_ 1956 DTCI_SAM_BH_WrnIndTrggrd "ENM";
BA_ "SignalLongName" SG_ 1956 DTCI_SAM_BH_WrnIndTrggrd "Diagnostic Trouble Code Information Extended - SAM_BH : Warning Indicator Triggered";
BA_ "SignalType" SG_ 1956 DTCI_SAM_BH_WrnIndRqd "ENM";
BA_ "SignalLongName" SG_ 1956 DTCI_SAM_BH_WrnIndRqd "Diagnostic Trouble Code Information Extended - SAM_BH : Warning Indicator Requested";
BA_ "SignalLongName" SG_ 1860 DTCI_SAM_LF_DTCFailType "Diagnostic Trouble Code Information Extended - SAM_LF : Diagnostic Trouble Code Failure Type";
BA_ "SignalType" SG_ 1860 DTCI_SAM_LF_CnfrmdDTC "ENM";
BA_ "SignalLongName" SG_ 1860 DTCI_SAM_LF_CnfrmdDTC "Diagnostic Trouble Code Information Extended - SAM_LF : Confirmed DTC";
BA_ "SignalType" SG_ 1860 DTCI_SAM_LF_DTCFaultType "ENM";
BA_ "SignalLongName" SG_ 1860 DTCI_SAM_LF_DTCFaultType "Diagnostic Trouble Code Information Extended - SAM_LF : Diagnostic Trouble Code Fault Type";
BA_ "SignalLongName" SG_ 1860 DTCI_SAM_LF_DTCNumber "Diagnostic Trouble Code Information Extended - SAM_LF : Diagnostic Trouble Code Number";
BA_ "SignalLongName" SG_ 1860 DTCI_SAM_LF_DTCSource "Diagnostic Trouble Code Information Extended - SAM_LF : Diagnostic Trouble Code Source";
BA_ "SignalType" SG_ 1860 DTCI_SAM_LF_TstNCmpltdOpCyc "ENM";
BA_ "SignalLongName" SG_ 1860 DTCI_SAM_LF_TstNCmpltdOpCyc "Diagnostic Trouble Code Information Extended - SAM_LF : Test Not Completed This Operation Cycle";
BA_ "SignalType" SG_ 1860 DTCI_SAM_LF_TstNCmpltdLstClr "ENM";
BA_ "SignalLongName" SG_ 1860 DTCI_SAM_LF_TstNCmpltdLstClr "Diagnostic Trouble Code Information Extended - SAM_LF : Test Not Completed Since Last Clear";
BA_ "SignalType" SG_ 1860 DTCI_SAM_LF_TstFldOpCyc "ENM";
BA_ "SignalLongName" SG_ 1860 DTCI_SAM_LF_TstFldOpCyc "Diagnostic Trouble Code Information Extended - SAM_LF : Test Failed This Operation Cycle";
BA_ "SignalType" SG_ 1860 DTCI_SAM_LF_TstFldLstClr "ENM";
BA_ "SignalLongName" SG_ 1860 DTCI_SAM_LF_TstFldLstClr "Diagnostic Trouble Code Information Extended - SAM_LF : Test Failed Since Last Clear";
BA_ "SignalType" SG_ 1860 DTCI_SAM_LF_TstFld "ENM";
BA_ "SignalLongName" SG_ 1860 DTCI_SAM_LF_TstFld "Diagnostic Trouble Code Information Extended - SAM_LF : Test Failed";
BA_ "SignalType" SG_ 1860 DTCI_SAM_LF_PndngDTC "ENM";
BA_ "SignalLongName" SG_ 1860 DTCI_SAM_LF_PndngDTC "Diagnostic Trouble Code Information Extended - SAM_LF : Pending DTC";
BA_ "SignalType" SG_ 1860 DTCI_SAM_LF_DTCTriggered "ENM";
BA_ "SignalLongName" SG_ 1860 DTCI_SAM_LF_DTCTriggered "Diagnostic Trouble Code Information Extended - SAM_LF : Diagnostic Trouble Code Triggered";
BA_ "SignalType" SG_ 1860 DTCI_SAM_LF_WrnIndTrggrd "ENM";
BA_ "SignalLongName" SG_ 1860 DTCI_SAM_LF_WrnIndTrggrd "Diagnostic Trouble Code Information Extended - SAM_LF : Warning Indicator Triggered";
BA_ "SignalType" SG_ 1860 DTCI_SAM_LF_WrnIndRqd "ENM";
BA_ "SignalLongName" SG_ 1860 DTCI_SAM_LF_WrnIndRqd "Diagnostic Trouble Code Information Extended - SAM_LF : Warning Indicator Requested";
BA_ "SignalLongName" SG_ 1205 DTCI_SAM_LR_DTCFailType "Diagnostic Trouble Code Information Extended - SAM_LR : Diagnostic Trouble Code Failure Type";
BA_ "SignalType" SG_ 1205 DTCI_SAM_LR_CnfrmdDTC "ENM";
BA_ "SignalLongName" SG_ 1205 DTCI_SAM_LR_CnfrmdDTC "Diagnostic Trouble Code Information Extended - SAM_LR : Confirmed DTC";
BA_ "SignalType" SG_ 1205 DTCI_SAM_LR_DTCFaultType "ENM";
BA_ "SignalLongName" SG_ 1205 DTCI_SAM_LR_DTCFaultType "Diagnostic Trouble Code Information Extended - SAM_LR : Diagnostic Trouble Code Fault Type";
BA_ "SignalLongName" SG_ 1205 DTCI_SAM_LR_DTCNumber "Diagnostic Trouble Code Information Extended - SAM_LR : Diagnostic Trouble Code Number";
BA_ "SignalLongName" SG_ 1205 DTCI_SAM_LR_DTCSource "Diagnostic Trouble Code Information Extended - SAM_LR : Diagnostic Trouble Code Source";
BA_ "SignalType" SG_ 1205 DTCI_SAM_LR_TstNCmpltdOpCyc "ENM";
BA_ "SignalLongName" SG_ 1205 DTCI_SAM_LR_TstNCmpltdOpCyc "Diagnostic Trouble Code Information Extended - SAM_LR : Test Not Completed This Operation Cycle";
BA_ "SignalType" SG_ 1205 DTCI_SAM_LR_TstNCmpltdLstClr "ENM";
BA_ "SignalLongName" SG_ 1205 DTCI_SAM_LR_TstNCmpltdLstClr "Diagnostic Trouble Code Information Extended - SAM_LR : Test Not Completed Since Last Clear";
BA_ "SignalType" SG_ 1205 DTCI_SAM_LR_TstFldOpCyc "ENM";
BA_ "SignalLongName" SG_ 1205 DTCI_SAM_LR_TstFldOpCyc "Diagnostic Trouble Code Information Extended - SAM_LR : Test Failed This Operation Cycle";
BA_ "SignalType" SG_ 1205 DTCI_SAM_LR_TstFldLstClr "ENM";
BA_ "SignalLongName" SG_ 1205 DTCI_SAM_LR_TstFldLstClr "Diagnostic Trouble Code Information Extended - SAM_LR : Test Failed Since Last Clear";
BA_ "SignalType" SG_ 1205 DTCI_SAM_LR_TstFld "ENM";
BA_ "SignalLongName" SG_ 1205 DTCI_SAM_LR_TstFld "Diagnostic Trouble Code Information Extended - SAM_LR : Test Failed";
BA_ "SignalType" SG_ 1205 DTCI_SAM_LR_PndngDTC "ENM";
BA_ "SignalLongName" SG_ 1205 DTCI_SAM_LR_PndngDTC "Diagnostic Trouble Code Information Extended - SAM_LR : Pending DTC";
BA_ "SignalType" SG_ 1205 DTCI_SAM_LR_DTCTriggered "ENM";
BA_ "SignalLongName" SG_ 1205 DTCI_SAM_LR_DTCTriggered "Diagnostic Trouble Code Information Extended - SAM_LR : Diagnostic Trouble Code Triggered";
BA_ "SignalType" SG_ 1205 DTCI_SAM_LR_WrnIndTrggrd "ENM";
BA_ "SignalLongName" SG_ 1205 DTCI_SAM_LR_WrnIndTrggrd "Diagnostic Trouble Code Information Extended - SAM_LR : Warning Indicator Triggered";
BA_ "SignalType" SG_ 1205 DTCI_SAM_LR_WrnIndRqd "ENM";
BA_ "SignalLongName" SG_ 1205 DTCI_SAM_LR_WrnIndRqd "Diagnostic Trouble Code Information Extended - SAM_LR : Warning Indicator Requested";
BA_ "SignalLongName" SG_ 1861 DTCI_SAM_RF_DTCFailType "Diagnostic Trouble Code Information Extended - SAM_RF : Diagnostic Trouble Code Failure Type";
BA_ "SignalType" SG_ 1861 DTCI_SAM_RF_CnfrmdDTC "ENM";
BA_ "SignalLongName" SG_ 1861 DTCI_SAM_RF_CnfrmdDTC "Diagnostic Trouble Code Information Extended - SAM_RF : Confirmed DTC";
BA_ "SignalType" SG_ 1861 DTCI_SAM_RF_DTCFaultType "ENM";
BA_ "SignalLongName" SG_ 1861 DTCI_SAM_RF_DTCFaultType "Diagnostic Trouble Code Information Extended - SAM_RF : Diagnostic Trouble Code Fault Type";
BA_ "SignalLongName" SG_ 1861 DTCI_SAM_RF_DTCNumber "Diagnostic Trouble Code Information Extended - SAM_RF : Diagnostic Trouble Code Number";
BA_ "SignalLongName" SG_ 1861 DTCI_SAM_RF_DTCSource "Diagnostic Trouble Code Information Extended - SAM_RF : Diagnostic Trouble Code Source";
BA_ "SignalType" SG_ 1861 DTCI_SAM_RF_TstNCmpltdOpCyc "ENM";
BA_ "SignalLongName" SG_ 1861 DTCI_SAM_RF_TstNCmpltdOpCyc "Diagnostic Trouble Code Information Extended - SAM_RF : Test Not Completed This Operation Cycle";
BA_ "SignalType" SG_ 1861 DTCI_SAM_RF_TstNCmpltdLstClr "ENM";
BA_ "SignalLongName" SG_ 1861 DTCI_SAM_RF_TstNCmpltdLstClr "Diagnostic Trouble Code Information Extended - SAM_RF : Test Not Completed Since Last Clear";
BA_ "SignalType" SG_ 1861 DTCI_SAM_RF_TstFldOpCyc "ENM";
BA_ "SignalLongName" SG_ 1861 DTCI_SAM_RF_TstFldOpCyc "Diagnostic Trouble Code Information Extended - SAM_RF : Test Failed This Operation Cycle";
BA_ "SignalType" SG_ 1861 DTCI_SAM_RF_TstFldLstClr "ENM";
BA_ "SignalLongName" SG_ 1861 DTCI_SAM_RF_TstFldLstClr "Diagnostic Trouble Code Information Extended - SAM_RF : Test Failed Since Last Clear";
BA_ "SignalType" SG_ 1861 DTCI_SAM_RF_TstFld "ENM";
BA_ "SignalLongName" SG_ 1861 DTCI_SAM_RF_TstFld "Diagnostic Trouble Code Information Extended - SAM_RF : Test Failed";
BA_ "SignalType" SG_ 1861 DTCI_SAM_RF_PndngDTC "ENM";
BA_ "SignalLongName" SG_ 1861 DTCI_SAM_RF_PndngDTC "Diagnostic Trouble Code Information Extended - SAM_RF : Pending DTC";
BA_ "SignalType" SG_ 1861 DTCI_SAM_RF_DTCTriggered "ENM";
BA_ "SignalLongName" SG_ 1861 DTCI_SAM_RF_DTCTriggered "Diagnostic Trouble Code Information Extended - SAM_RF : Diagnostic Trouble Code Triggered";
BA_ "SignalType" SG_ 1861 DTCI_SAM_RF_WrnIndTrggrd "ENM";
BA_ "SignalLongName" SG_ 1861 DTCI_SAM_RF_WrnIndTrggrd "Diagnostic Trouble Code Information Extended - SAM_RF : Warning Indicator Triggered";
BA_ "SignalType" SG_ 1861 DTCI_SAM_RF_WrnIndRqd "ENM";
BA_ "SignalLongName" SG_ 1861 DTCI_SAM_RF_WrnIndRqd "Diagnostic Trouble Code Information Extended - SAM_RF : Warning Indicator Requested";
BA_ "SignalLongName" SG_ 1204 DTCI_SAM_RR_DTCFailType "Diagnostic Trouble Code Information Extended - SAM_RR : Diagnostic Trouble Code Failure Type";
BA_ "SignalType" SG_ 1204 DTCI_SAM_RR_CnfrmdDTC "ENM";
BA_ "SignalLongName" SG_ 1204 DTCI_SAM_RR_CnfrmdDTC "Diagnostic Trouble Code Information Extended - SAM_RR : Confirmed DTC";
BA_ "SignalType" SG_ 1204 DTCI_SAM_RR_DTCFaultType "ENM";
BA_ "SignalLongName" SG_ 1204 DTCI_SAM_RR_DTCFaultType "Diagnostic Trouble Code Information Extended - SAM_RR : Diagnostic Trouble Code Fault Type";
BA_ "SignalLongName" SG_ 1204 DTCI_SAM_RR_DTCNumber "Diagnostic Trouble Code Information Extended - SAM_RR : Diagnostic Trouble Code Number";
BA_ "SignalLongName" SG_ 1204 DTCI_SAM_RR_DTCSource "Diagnostic Trouble Code Information Extended - SAM_RR : Diagnostic Trouble Code Source";
BA_ "SignalType" SG_ 1204 DTCI_SAM_RR_TstNCmpltdOpCyc "ENM";
BA_ "SignalLongName" SG_ 1204 DTCI_SAM_RR_TstNCmpltdOpCyc "Diagnostic Trouble Code Information Extended - SAM_RR : Test Not Completed This Operation Cycle";
BA_ "SignalType" SG_ 1204 DTCI_SAM_RR_TstNCmpltdLstClr "ENM";
BA_ "SignalLongName" SG_ 1204 DTCI_SAM_RR_TstNCmpltdLstClr "Diagnostic Trouble Code Information Extended - SAM_RR : Test Not Completed Since Last Clear";
BA_ "SignalType" SG_ 1204 DTCI_SAM_RR_TstFldOpCyc "ENM";
BA_ "SignalLongName" SG_ 1204 DTCI_SAM_RR_TstFldOpCyc "Diagnostic Trouble Code Information Extended - SAM_RR : Test Failed This Operation Cycle";
BA_ "SignalType" SG_ 1204 DTCI_SAM_RR_TstFldLstClr "ENM";
BA_ "SignalLongName" SG_ 1204 DTCI_SAM_RR_TstFldLstClr "Diagnostic Trouble Code Information Extended - SAM_RR : Test Failed Since Last Clear";
BA_ "SignalType" SG_ 1204 DTCI_SAM_RR_TstFld "ENM";
BA_ "SignalLongName" SG_ 1204 DTCI_SAM_RR_TstFld "Diagnostic Trouble Code Information Extended - SAM_RR : Test Failed";
BA_ "SignalType" SG_ 1204 DTCI_SAM_RR_PndngDTC "ENM";
BA_ "SignalLongName" SG_ 1204 DTCI_SAM_RR_PndngDTC "Diagnostic Trouble Code Information Extended - SAM_RR : Pending DTC";
BA_ "SignalType" SG_ 1204 DTCI_SAM_RR_DTCTriggered "ENM";
BA_ "SignalLongName" SG_ 1204 DTCI_SAM_RR_DTCTriggered "Diagnostic Trouble Code Information Extended - SAM_RR : Diagnostic Trouble Code Triggered";
BA_ "SignalType" SG_ 1204 DTCI_SAM_RR_WrnIndTrggrd "ENM";
BA_ "SignalLongName" SG_ 1204 DTCI_SAM_RR_WrnIndTrggrd "Diagnostic Trouble Code Information Extended - SAM_RR : Warning Indicator Triggered";
BA_ "SignalType" SG_ 1204 DTCI_SAM_RR_WrnIndRqd "ENM";
BA_ "SignalLongName" SG_ 1204 DTCI_SAM_RR_WrnIndRqd "Diagnostic Trouble Code Information Extended - SAM_RR : Warning Indicator Requested";
BA_ "SignalLongName" SG_ 1862 DTCI_SBM_DTCFailType "Diagnostic Trouble Code Information Extended - SBM : Diagnostic Trouble Code Failure Type";
BA_ "SignalType" SG_ 1862 DTCI_SBM_CnfrmdDTC "ENM";
BA_ "SignalLongName" SG_ 1862 DTCI_SBM_CnfrmdDTC "Diagnostic Trouble Code Information Extended - SBM : Confirmed DTC";
BA_ "SignalType" SG_ 1862 DTCI_SBM_DTCFaultType "ENM";
BA_ "SignalLongName" SG_ 1862 DTCI_SBM_DTCFaultType "Diagnostic Trouble Code Information Extended - SBM : Diagnostic Trouble Code Fault Type";
BA_ "SignalLongName" SG_ 1862 DTCI_SBM_DTCNumber "Diagnostic Trouble Code Information Extended - SBM : Diagnostic Trouble Code Number";
BA_ "SignalLongName" SG_ 1862 DTCI_SBM_DTCSource "Diagnostic Trouble Code Information Extended - SBM : Diagnostic Trouble Code Source";
BA_ "SignalType" SG_ 1862 DTCI_SBM_TstNCmpltdOpCyc "ENM";
BA_ "SignalLongName" SG_ 1862 DTCI_SBM_TstNCmpltdOpCyc "Diagnostic Trouble Code Information Extended - SBM : Test Not Completed This Operation Cycle";
BA_ "SignalType" SG_ 1862 DTCI_SBM_TstNCmpltdLstClr "ENM";
BA_ "SignalLongName" SG_ 1862 DTCI_SBM_TstNCmpltdLstClr "Diagnostic Trouble Code Information Extended - SBM : Test Not Completed Since Last Clear";
BA_ "SignalType" SG_ 1862 DTCI_SBM_TstFldOpCyc "ENM";
BA_ "SignalLongName" SG_ 1862 DTCI_SBM_TstFldOpCyc "Diagnostic Trouble Code Information Extended - SBM : Test Failed This Operation Cycle";
BA_ "SignalType" SG_ 1862 DTCI_SBM_TstFldLstClr "ENM";
BA_ "SignalLongName" SG_ 1862 DTCI_SBM_TstFldLstClr "Diagnostic Trouble Code Information Extended - SBM : Test Failed Since Last Clear";
BA_ "SignalType" SG_ 1862 DTCI_SBM_TstFld "ENM";
BA_ "SignalLongName" SG_ 1862 DTCI_SBM_TstFld "Diagnostic Trouble Code Information Extended - SBM : Test Failed";
BA_ "SignalType" SG_ 1862 DTCI_SBM_PndngDTC "ENM";
BA_ "SignalLongName" SG_ 1862 DTCI_SBM_PndngDTC "Diagnostic Trouble Code Information Extended - SBM : Pending DTC";
BA_ "SignalType" SG_ 1862 DTCI_SBM_DTCTriggered "ENM";
BA_ "SignalLongName" SG_ 1862 DTCI_SBM_DTCTriggered "Diagnostic Trouble Code Information Extended - SBM : Diagnostic Trouble Code Triggered";
BA_ "SignalType" SG_ 1862 DTCI_SBM_WrnIndTrggrd "ENM";
BA_ "SignalLongName" SG_ 1862 DTCI_SBM_WrnIndTrggrd "Diagnostic Trouble Code Information Extended - SBM : Warning Indicator Triggered";
BA_ "SignalType" SG_ 1862 DTCI_SBM_WrnIndRqd "ENM";
BA_ "SignalLongName" SG_ 1862 DTCI_SBM_WrnIndRqd "Diagnostic Trouble Code Information Extended - SBM : Warning Indicator Requested";
BA_ "SignalLongName" SG_ 1203 DTCI_SBZA_L_DTCFailType "Diagnostic Trouble Code Information Extended - SBZA_L : Diagnostic Trouble Code Failure Type";
BA_ "SignalType" SG_ 1203 DTCI_SBZA_L_CnfrmdDTC "ENM";
BA_ "SignalLongName" SG_ 1203 DTCI_SBZA_L_CnfrmdDTC "Diagnostic Trouble Code Information Extended - SBZA_L : Confirmed DTC";
BA_ "SignalType" SG_ 1203 DTCI_SBZA_L_DTCFaultType "ENM";
BA_ "SignalLongName" SG_ 1203 DTCI_SBZA_L_DTCFaultType "Diagnostic Trouble Code Information Extended - SBZA_L : Diagnostic Trouble Code Fault Type";
BA_ "SignalLongName" SG_ 1203 DTCI_SBZA_L_DTCNumber "Diagnostic Trouble Code Information Extended - SBZA_L : Diagnostic Trouble Code Number";
BA_ "SignalLongName" SG_ 1203 DTCI_SBZA_L_DTCSource "Diagnostic Trouble Code Information Extended - SBZA_L : Diagnostic Trouble Code Source";
BA_ "SignalType" SG_ 1203 DTCI_SBZA_L_TstNCmpltdOpCyc "ENM";
BA_ "SignalLongName" SG_ 1203 DTCI_SBZA_L_TstNCmpltdOpCyc "Diagnostic Trouble Code Information Extended - SBZA_L : Test Not Completed This Operation Cycle";
BA_ "SignalType" SG_ 1203 DTCI_SBZA_L_TstNCmpltdLstClr "ENM";
BA_ "SignalLongName" SG_ 1203 DTCI_SBZA_L_TstNCmpltdLstClr "Diagnostic Trouble Code Information Extended - SBZA_L : Test Not Completed Since Last Clear";
BA_ "SignalType" SG_ 1203 DTCI_SBZA_L_TstFldOpCyc "ENM";
BA_ "SignalLongName" SG_ 1203 DTCI_SBZA_L_TstFldOpCyc "Diagnostic Trouble Code Information Extended - SBZA_L : Test Failed This Operation Cycle";
BA_ "SignalType" SG_ 1203 DTCI_SBZA_L_TstFldLstClr "ENM";
BA_ "SignalLongName" SG_ 1203 DTCI_SBZA_L_TstFldLstClr "Diagnostic Trouble Code Information Extended - SBZA_L : Test Failed Since Last Clear";
BA_ "SignalType" SG_ 1203 DTCI_SBZA_L_TstFld "ENM";
BA_ "SignalLongName" SG_ 1203 DTCI_SBZA_L_TstFld "Diagnostic Trouble Code Information Extended - SBZA_L : Test Failed";
BA_ "SignalType" SG_ 1203 DTCI_SBZA_L_PndngDTC "ENM";
BA_ "SignalLongName" SG_ 1203 DTCI_SBZA_L_PndngDTC "Diagnostic Trouble Code Information Extended - SBZA_L : Pending DTC";
BA_ "SignalType" SG_ 1203 DTCI_SBZA_L_DTCTriggered "ENM";
BA_ "SignalLongName" SG_ 1203 DTCI_SBZA_L_DTCTriggered "Diagnostic Trouble Code Information Extended - SBZA_L : Diagnostic Trouble Code Triggered";
BA_ "SignalType" SG_ 1203 DTCI_SBZA_L_WrnIndTrggrd "ENM";
BA_ "SignalLongName" SG_ 1203 DTCI_SBZA_L_WrnIndTrggrd "Diagnostic Trouble Code Information Extended - SBZA_L : Warning Indicator Triggered";
BA_ "SignalType" SG_ 1203 DTCI_SBZA_L_WrnIndRqd "ENM";
BA_ "SignalLongName" SG_ 1203 DTCI_SBZA_L_WrnIndRqd "Diagnostic Trouble Code Information Extended - SBZA_L : Warning Indicator Requested";
BA_ "SignalLongName" SG_ 1863 DTCI_SBZA_R_DTCFailType "Diagnostic Trouble Code Information Extended - SBZA_R : Diagnostic Trouble Code Failure Type";
BA_ "SignalType" SG_ 1863 DTCI_SBZA_R_CnfrmdDTC "ENM";
BA_ "SignalLongName" SG_ 1863 DTCI_SBZA_R_CnfrmdDTC "Diagnostic Trouble Code Information Extended - SBZA_R : Confirmed DTC";
BA_ "SignalType" SG_ 1863 DTCI_SBZA_R_DTCFaultType "ENM";
BA_ "SignalLongName" SG_ 1863 DTCI_SBZA_R_DTCFaultType "Diagnostic Trouble Code Information Extended - SBZA_R : Diagnostic Trouble Code Fault Type";
BA_ "SignalLongName" SG_ 1863 DTCI_SBZA_R_DTCNumber "Diagnostic Trouble Code Information Extended - SBZA_R : Diagnostic Trouble Code Number";
BA_ "SignalLongName" SG_ 1863 DTCI_SBZA_R_DTCSource "Diagnostic Trouble Code Information Extended - SBZA_R : Diagnostic Trouble Code Source";
BA_ "SignalType" SG_ 1863 DTCI_SBZA_R_TstNCmpltdOpCyc "ENM";
BA_ "SignalLongName" SG_ 1863 DTCI_SBZA_R_TstNCmpltdOpCyc "Diagnostic Trouble Code Information Extended - SBZA_R : Test Not Completed This Operation Cycle";
BA_ "SignalType" SG_ 1863 DTCI_SBZA_R_TstNCmpltdLstClr "ENM";
BA_ "SignalLongName" SG_ 1863 DTCI_SBZA_R_TstNCmpltdLstClr "Diagnostic Trouble Code Information Extended - SBZA_R : Test Not Completed Since Last Clear";
BA_ "SignalType" SG_ 1863 DTCI_SBZA_R_TstFldOpCyc "ENM";
BA_ "SignalLongName" SG_ 1863 DTCI_SBZA_R_TstFldOpCyc "Diagnostic Trouble Code Information Extended - SBZA_R : Test Failed This Operation Cycle";
BA_ "SignalType" SG_ 1863 DTCI_SBZA_R_TstFldLstClr "ENM";
BA_ "SignalLongName" SG_ 1863 DTCI_SBZA_R_TstFldLstClr "Diagnostic Trouble Code Information Extended - SBZA_R : Test Failed Since Last Clear";
BA_ "SignalType" SG_ 1863 DTCI_SBZA_R_TstFld "ENM";
BA_ "SignalLongName" SG_ 1863 DTCI_SBZA_R_TstFld "Diagnostic Trouble Code Information Extended - SBZA_R : Test Failed";
BA_ "SignalType" SG_ 1863 DTCI_SBZA_R_PndngDTC "ENM";
BA_ "SignalLongName" SG_ 1863 DTCI_SBZA_R_PndngDTC "Diagnostic Trouble Code Information Extended - SBZA_R : Pending DTC";
BA_ "SignalType" SG_ 1863 DTCI_SBZA_R_DTCTriggered "ENM";
BA_ "SignalLongName" SG_ 1863 DTCI_SBZA_R_DTCTriggered "Diagnostic Trouble Code Information Extended - SBZA_R : Diagnostic Trouble Code Triggered";
BA_ "SignalType" SG_ 1863 DTCI_SBZA_R_WrnIndTrggrd "ENM";
BA_ "SignalLongName" SG_ 1863 DTCI_SBZA_R_WrnIndTrggrd "Diagnostic Trouble Code Information Extended - SBZA_R : Warning Indicator Triggered";
BA_ "SignalType" SG_ 1863 DTCI_SBZA_R_WrnIndRqd "ENM";
BA_ "SignalLongName" SG_ 1863 DTCI_SBZA_R_WrnIndRqd "Diagnostic Trouble Code Information Extended - SBZA_R : Warning Indicator Requested";
BA_ "SignalLongName" SG_ 1202 DTCI_SCL_DTCFailType "Diagnostic Trouble Code Information Extended - SCL : Diagnostic Trouble Code Failure Type";
BA_ "SignalType" SG_ 1202 DTCI_SCL_CnfrmdDTC "ENM";
BA_ "SignalLongName" SG_ 1202 DTCI_SCL_CnfrmdDTC "Diagnostic Trouble Code Information Extended - SCL : Confirmed DTC";
BA_ "SignalType" SG_ 1202 DTCI_SCL_DTCFaultType "ENM";
BA_ "SignalLongName" SG_ 1202 DTCI_SCL_DTCFaultType "Diagnostic Trouble Code Information Extended - SCL : Diagnostic Trouble Code Fault Type";
BA_ "SignalLongName" SG_ 1202 DTCI_SCL_DTCNumber "Diagnostic Trouble Code Information Extended - SCL : Diagnostic Trouble Code Number";
BA_ "SignalLongName" SG_ 1202 DTCI_SCL_DTCSource "Diagnostic Trouble Code Information Extended - SCL : Diagnostic Trouble Code Source";
BA_ "SignalType" SG_ 1202 DTCI_SCL_TstNCmpltdOpCyc "ENM";
BA_ "SignalLongName" SG_ 1202 DTCI_SCL_TstNCmpltdOpCyc "Diagnostic Trouble Code Information Extended - SCL : Test Not Completed This Operation Cycle";
BA_ "SignalType" SG_ 1202 DTCI_SCL_TstNCmpltdLstClr "ENM";
BA_ "SignalLongName" SG_ 1202 DTCI_SCL_TstNCmpltdLstClr "Diagnostic Trouble Code Information Extended - SCL : Test Not Completed Since Last Clear";
BA_ "SignalType" SG_ 1202 DTCI_SCL_TstFldOpCyc "ENM";
BA_ "SignalLongName" SG_ 1202 DTCI_SCL_TstFldOpCyc "Diagnostic Trouble Code Information Extended - SCL : Test Failed This Operation Cycle";
BA_ "SignalType" SG_ 1202 DTCI_SCL_TstFldLstClr "ENM";
BA_ "SignalLongName" SG_ 1202 DTCI_SCL_TstFldLstClr "Diagnostic Trouble Code Information Extended - SCL : Test Failed Since Last Clear";
BA_ "SignalType" SG_ 1202 DTCI_SCL_TstFld "ENM";
BA_ "SignalLongName" SG_ 1202 DTCI_SCL_TstFld "Diagnostic Trouble Code Information Extended - SCL : Test Failed";
BA_ "SignalType" SG_ 1202 DTCI_SCL_PndngDTC "ENM";
BA_ "SignalLongName" SG_ 1202 DTCI_SCL_PndngDTC "Diagnostic Trouble Code Information Extended - SCL : Pending DTC";
BA_ "SignalType" SG_ 1202 DTCI_SCL_DTCTriggered "ENM";
BA_ "SignalLongName" SG_ 1202 DTCI_SCL_DTCTriggered "Diagnostic Trouble Code Information Extended - SCL : Diagnostic Trouble Code Triggered";
BA_ "SignalType" SG_ 1202 DTCI_SCL_WrnIndTrggrd "ENM";
BA_ "SignalLongName" SG_ 1202 DTCI_SCL_WrnIndTrggrd "Diagnostic Trouble Code Information Extended - SCL : Warning Indicator Triggered";
BA_ "SignalType" SG_ 1202 DTCI_SCL_WrnIndRqd "ENM";
BA_ "SignalLongName" SG_ 1202 DTCI_SCL_WrnIndRqd "Diagnostic Trouble Code Information Extended - SCL : Warning Indicator Requested";
BA_ "SignalLongName" SG_ 1919 DTCI_SDM_AV_DTCFailType "Diagnostic Trouble Code Information Extended - SDM_AV : Diagnostic Trouble Code Failure Type";
BA_ "SignalType" SG_ 1919 DTCI_SDM_AV_CnfrmdDTC "ENM";
BA_ "SignalLongName" SG_ 1919 DTCI_SDM_AV_CnfrmdDTC "Diagnostic Trouble Code Information Extended - SDM_AV : Confirmed DTC";
BA_ "SignalType" SG_ 1919 DTCI_SDM_AV_DTCFaultType "ENM";
BA_ "SignalLongName" SG_ 1919 DTCI_SDM_AV_DTCFaultType "Diagnostic Trouble Code Information Extended - SDM_AV : Diagnostic Trouble Code Fault Type";
BA_ "SignalLongName" SG_ 1919 DTCI_SDM_AV_DTCNumber "Diagnostic Trouble Code Information Extended - SDM_AV : Diagnostic Trouble Code Number";
BA_ "SignalLongName" SG_ 1919 DTCI_SDM_AV_DTCSource "Diagnostic Trouble Code Information Extended - SDM_AV : Diagnostic Trouble Code Source";
BA_ "SignalType" SG_ 1919 DTCI_SDM_AV_TstNCmpltdOpCyc "ENM";
BA_ "SignalLongName" SG_ 1919 DTCI_SDM_AV_TstNCmpltdOpCyc "Diagnostic Trouble Code Information Extended - SDM_AV : Test Not Completed This Operation Cycle";
BA_ "SignalType" SG_ 1919 DTCI_SDM_AV_TstNCmpltdLstClr "ENM";
BA_ "SignalLongName" SG_ 1919 DTCI_SDM_AV_TstNCmpltdLstClr "Diagnostic Trouble Code Information Extended - SDM_AV : Test Not Completed Since Last Clear";
BA_ "SignalType" SG_ 1919 DTCI_SDM_AV_TstFldOpCyc "ENM";
BA_ "SignalLongName" SG_ 1919 DTCI_SDM_AV_TstFldOpCyc "Diagnostic Trouble Code Information Extended - SDM_AV : Test Failed This Operation Cycle";
BA_ "SignalType" SG_ 1919 DTCI_SDM_AV_TstFldLstClr "ENM";
BA_ "SignalLongName" SG_ 1919 DTCI_SDM_AV_TstFldLstClr "Diagnostic Trouble Code Information Extended - SDM_AV : Test Failed Since Last Clear";
BA_ "SignalType" SG_ 1919 DTCI_SDM_AV_TstFld "ENM";
BA_ "SignalLongName" SG_ 1919 DTCI_SDM_AV_TstFld "Diagnostic Trouble Code Information Extended - SDM_AV : Test Failed";
BA_ "SignalType" SG_ 1919 DTCI_SDM_AV_PndngDTC "ENM";
BA_ "SignalLongName" SG_ 1919 DTCI_SDM_AV_PndngDTC "Diagnostic Trouble Code Information Extended - SDM_AV : Pending DTC";
BA_ "SignalType" SG_ 1919 DTCI_SDM_AV_DTCTriggered "ENM";
BA_ "SignalLongName" SG_ 1919 DTCI_SDM_AV_DTCTriggered "Diagnostic Trouble Code Information Extended - SDM_AV : Diagnostic Trouble Code Triggered";
BA_ "SignalType" SG_ 1919 DTCI_SDM_AV_WrnIndTrggrd "ENM";
BA_ "SignalLongName" SG_ 1919 DTCI_SDM_AV_WrnIndTrggrd "Diagnostic Trouble Code Information Extended - SDM_AV : Warning Indicator Triggered";
BA_ "SignalType" SG_ 1919 DTCI_SDM_AV_WrnIndRqd "ENM";
BA_ "SignalLongName" SG_ 1919 DTCI_SDM_AV_WrnIndRqd "Diagnostic Trouble Code Information Extended - SDM_AV : Warning Indicator Requested";
BA_ "SignalLongName" SG_ 1864 DTCI_SDM_DTCFailType "Diagnostic Trouble Code Information Extended - SDM : Diagnostic Trouble Code Failure Type";
BA_ "SignalType" SG_ 1864 DTCI_SDM_CnfrmdDTC "ENM";
BA_ "SignalLongName" SG_ 1864 DTCI_SDM_CnfrmdDTC "Diagnostic Trouble Code Information Extended - SDM : Confirmed DTC";
BA_ "SignalType" SG_ 1864 DTCI_SDM_DTCFaultType "ENM";
BA_ "SignalLongName" SG_ 1864 DTCI_SDM_DTCFaultType "Diagnostic Trouble Code Information Extended - SDM : Diagnostic Trouble Code Fault Type";
BA_ "SignalLongName" SG_ 1864 DTCI_SDM_DTCNumber "Diagnostic Trouble Code Information Extended - SDM : Diagnostic Trouble Code Number";
BA_ "SignalLongName" SG_ 1864 DTCI_SDM_DTCSource "Diagnostic Trouble Code Information Extended - SDM : Diagnostic Trouble Code Source";
BA_ "SignalType" SG_ 1864 DTCI_SDM_TstNCmpltdOpCyc "ENM";
BA_ "SignalLongName" SG_ 1864 DTCI_SDM_TstNCmpltdOpCyc "Diagnostic Trouble Code Information Extended - SDM : Test Not Completed This Operation Cycle";
BA_ "SignalType" SG_ 1864 DTCI_SDM_TstNCmpltdLstClr "ENM";
BA_ "SignalLongName" SG_ 1864 DTCI_SDM_TstNCmpltdLstClr "Diagnostic Trouble Code Information Extended - SDM : Test Not Completed Since Last Clear";
BA_ "SignalType" SG_ 1864 DTCI_SDM_TstFldOpCyc "ENM";
BA_ "SignalLongName" SG_ 1864 DTCI_SDM_TstFldOpCyc "Diagnostic Trouble Code Information Extended - SDM : Test Failed This Operation Cycle";
BA_ "SignalType" SG_ 1864 DTCI_SDM_TstFldLstClr "ENM";
BA_ "SignalLongName" SG_ 1864 DTCI_SDM_TstFldLstClr "Diagnostic Trouble Code Information Extended - SDM : Test Failed Since Last Clear";
BA_ "SignalType" SG_ 1864 DTCI_SDM_TstFld "ENM";
BA_ "SignalLongName" SG_ 1864 DTCI_SDM_TstFld "Diagnostic Trouble Code Information Extended - SDM : Test Failed";
BA_ "SignalType" SG_ 1864 DTCI_SDM_PndngDTC "ENM";
BA_ "SignalLongName" SG_ 1864 DTCI_SDM_PndngDTC "Diagnostic Trouble Code Information Extended - SDM : Pending DTC";
BA_ "SignalType" SG_ 1864 DTCI_SDM_DTCTriggered "ENM";
BA_ "SignalLongName" SG_ 1864 DTCI_SDM_DTCTriggered "Diagnostic Trouble Code Information Extended - SDM : Diagnostic Trouble Code Triggered";
BA_ "SignalType" SG_ 1864 DTCI_SDM_WrnIndTrggrd "ENM";
BA_ "SignalLongName" SG_ 1864 DTCI_SDM_WrnIndTrggrd "Diagnostic Trouble Code Information Extended - SDM : Warning Indicator Triggered";
BA_ "SignalType" SG_ 1864 DTCI_SDM_WrnIndRqd "ENM";
BA_ "SignalLongName" SG_ 1864 DTCI_SDM_WrnIndRqd "Diagnostic Trouble Code Information Extended - SDM : Warning Indicator Requested";
BA_ "SignalLongName" SG_ 1201 DTCI_SIB_DTCFailType "Diagnostic Trouble Code Information Extended - SIB : Diagnostic Trouble Code Failure Type";
BA_ "SignalType" SG_ 1201 DTCI_SIB_CnfrmdDTC "ENM";
BA_ "SignalLongName" SG_ 1201 DTCI_SIB_CnfrmdDTC "Diagnostic Trouble Code Information Extended - SIB : Confirmed DTC";
BA_ "SignalType" SG_ 1201 DTCI_SIB_DTCFaultType "ENM";
BA_ "SignalLongName" SG_ 1201 DTCI_SIB_DTCFaultType "Diagnostic Trouble Code Information Extended - SIB : Diagnostic Trouble Code Fault Type";
BA_ "SignalLongName" SG_ 1201 DTCI_SIB_DTCNumber "Diagnostic Trouble Code Information Extended - SIB : Diagnostic Trouble Code Number";
BA_ "SignalLongName" SG_ 1201 DTCI_SIB_DTCSource "Diagnostic Trouble Code Information Extended - SIB : Diagnostic Trouble Code Source";
BA_ "SignalType" SG_ 1201 DTCI_SIB_TstNCmpltdOpCyc "ENM";
BA_ "SignalLongName" SG_ 1201 DTCI_SIB_TstNCmpltdOpCyc "Diagnostic Trouble Code Information Extended - SIB : Test Not Completed This Operation Cycle";
BA_ "SignalType" SG_ 1201 DTCI_SIB_TstNCmpltdLstClr "ENM";
BA_ "SignalLongName" SG_ 1201 DTCI_SIB_TstNCmpltdLstClr "Diagnostic Trouble Code Information Extended - SIB : Test Not Completed Since Last Clear";
BA_ "SignalType" SG_ 1201 DTCI_SIB_TstFldOpCyc "ENM";
BA_ "SignalLongName" SG_ 1201 DTCI_SIB_TstFldOpCyc "Diagnostic Trouble Code Information Extended - SIB : Test Failed This Operation Cycle";
BA_ "SignalType" SG_ 1201 DTCI_SIB_TstFldLstClr "ENM";
BA_ "SignalLongName" SG_ 1201 DTCI_SIB_TstFldLstClr "Diagnostic Trouble Code Information Extended - SIB : Test Failed Since Last Clear";
BA_ "SignalType" SG_ 1201 DTCI_SIB_TstFld "ENM";
BA_ "SignalLongName" SG_ 1201 DTCI_SIB_TstFld "Diagnostic Trouble Code Information Extended - SIB : Test Failed";
BA_ "SignalType" SG_ 1201 DTCI_SIB_PndngDTC "ENM";
BA_ "SignalLongName" SG_ 1201 DTCI_SIB_PndngDTC "Diagnostic Trouble Code Information Extended - SIB : Pending DTC";
BA_ "SignalType" SG_ 1201 DTCI_SIB_DTCTriggered "ENM";
BA_ "SignalLongName" SG_ 1201 DTCI_SIB_DTCTriggered "Diagnostic Trouble Code Information Extended - SIB : Diagnostic Trouble Code Triggered";
BA_ "SignalType" SG_ 1201 DTCI_SIB_WrnIndTrggrd "ENM";
BA_ "SignalLongName" SG_ 1201 DTCI_SIB_WrnIndTrggrd "Diagnostic Trouble Code Information Extended - SIB : Warning Indicator Triggered";
BA_ "SignalType" SG_ 1201 DTCI_SIB_WrnIndRqd "ENM";
BA_ "SignalLongName" SG_ 1201 DTCI_SIB_WrnIndRqd "Diagnostic Trouble Code Information Extended - SIB : Warning Indicator Requested";
BA_ "SignalLongName" SG_ 1865 DTCI_SRR_LF_DTCFailType "Diagnostic Trouble Code Information Extended - SRR_LF : Diagnostic Trouble Code Failure Type";
BA_ "SignalType" SG_ 1865 DTCI_SRR_LF_CnfrmdDTC "ENM";
BA_ "SignalLongName" SG_ 1865 DTCI_SRR_LF_CnfrmdDTC "Diagnostic Trouble Code Information Extended - SRR_LF : Confirmed DTC";
BA_ "SignalType" SG_ 1865 DTCI_SRR_LF_DTCFaultType "ENM";
BA_ "SignalLongName" SG_ 1865 DTCI_SRR_LF_DTCFaultType "Diagnostic Trouble Code Information Extended - SRR_LF : Diagnostic Trouble Code Fault Type";
BA_ "SignalLongName" SG_ 1865 DTCI_SRR_LF_DTCNumber "Diagnostic Trouble Code Information Extended - SRR_LF : Diagnostic Trouble Code Number";
BA_ "SignalLongName" SG_ 1865 DTCI_SRR_LF_DTCSource "Diagnostic Trouble Code Information Extended - SRR_LF : Diagnostic Trouble Code Source";
BA_ "SignalType" SG_ 1865 DTCI_SRR_LF_TstNCmpltdOpCyc "ENM";
BA_ "SignalLongName" SG_ 1865 DTCI_SRR_LF_TstNCmpltdOpCyc "Diagnostic Trouble Code Information Extended - SRR_LF : Test Not Completed This Operation Cycle";
BA_ "SignalType" SG_ 1865 DTCI_SRR_LF_TstNCmpltdLstClr "ENM";
BA_ "SignalLongName" SG_ 1865 DTCI_SRR_LF_TstNCmpltdLstClr "Diagnostic Trouble Code Information Extended - SRR_LF : Test Not Completed Since Last Clear";
BA_ "SignalType" SG_ 1865 DTCI_SRR_LF_TstFldOpCyc "ENM";
BA_ "SignalLongName" SG_ 1865 DTCI_SRR_LF_TstFldOpCyc "Diagnostic Trouble Code Information Extended - SRR_LF : Test Failed This Operation Cycle";
BA_ "SignalType" SG_ 1865 DTCI_SRR_LF_TstFldLstClr "ENM";
BA_ "SignalLongName" SG_ 1865 DTCI_SRR_LF_TstFldLstClr "Diagnostic Trouble Code Information Extended - SRR_LF : Test Failed Since Last Clear";
BA_ "SignalType" SG_ 1865 DTCI_SRR_LF_TstFld "ENM";
BA_ "SignalLongName" SG_ 1865 DTCI_SRR_LF_TstFld "Diagnostic Trouble Code Information Extended - SRR_LF : Test Failed";
BA_ "SignalType" SG_ 1865 DTCI_SRR_LF_PndngDTC "ENM";
BA_ "SignalLongName" SG_ 1865 DTCI_SRR_LF_PndngDTC "Diagnostic Trouble Code Information Extended - SRR_LF : Pending DTC";
BA_ "SignalType" SG_ 1865 DTCI_SRR_LF_DTCTriggered "ENM";
BA_ "SignalLongName" SG_ 1865 DTCI_SRR_LF_DTCTriggered "Diagnostic Trouble Code Information Extended - SRR_LF : Diagnostic Trouble Code Triggered";
BA_ "SignalType" SG_ 1865 DTCI_SRR_LF_WrnIndTrggrd "ENM";
BA_ "SignalLongName" SG_ 1865 DTCI_SRR_LF_WrnIndTrggrd "Diagnostic Trouble Code Information Extended - SRR_LF : Warning Indicator Triggered";
BA_ "SignalType" SG_ 1865 DTCI_SRR_LF_WrnIndRqd "ENM";
BA_ "SignalLongName" SG_ 1865 DTCI_SRR_LF_WrnIndRqd "Diagnostic Trouble Code Information Extended - SRR_LF : Warning Indicator Requested";
BA_ "SignalLongName" SG_ 1200 DTCI_SRR_LR_CR_DTCFailType "Diagnostic Trouble Code Information Extended - SRR_LR_CR : Diagnostic Trouble Code Failure Type";
BA_ "SignalType" SG_ 1200 DTCI_SRR_LR_CR_CnfrmdDTC "ENM";
BA_ "SignalLongName" SG_ 1200 DTCI_SRR_LR_CR_CnfrmdDTC "Diagnostic Trouble Code Information Extended - SRR_LR_CR : Confirmed DTC";
BA_ "SignalType" SG_ 1200 DTCI_SRR_LR_CR_DTCFaultType "ENM";
BA_ "SignalLongName" SG_ 1200 DTCI_SRR_LR_CR_DTCFaultType "Diagnostic Trouble Code Information Extended - SRR_LR_CR : Diagnostic Trouble Code Fault Type";
BA_ "SignalLongName" SG_ 1200 DTCI_SRR_LR_CR_DTCNumber "Diagnostic Trouble Code Information Extended - SRR_LR_CR : Diagnostic Trouble Code Number";
BA_ "SignalLongName" SG_ 1200 DTCI_SRR_LR_CR_DTCSource "Diagnostic Trouble Code Information Extended - SRR_LR_CR : Diagnostic Trouble Code Source";
BA_ "SignalType" SG_ 1200 DTCI_SRR_LR_CR_TstNCmpltdOpCyc "ENM";
BA_ "SignalLongName" SG_ 1200 DTCI_SRR_LR_CR_TstNCmpltdOpCyc "Diagnostic Trouble Code Information Extended - SRR_LR_CR : Test Not Completed This Operation Cycle";
BA_ "SignalType" SG_ 1200 DTCI_SRR_LR_CR_TstNCmpltdLstClr "ENM";
BA_ "SignalLongName" SG_ 1200 DTCI_SRR_LR_CR_TstNCmpltdLstClr "Diagnostic Trouble Code Information Extended - SRR_LR_CR : Test Not Completed Since Last Clear";
BA_ "SignalType" SG_ 1200 DTCI_SRR_LR_CR_TstFldOpCyc "ENM";
BA_ "SignalLongName" SG_ 1200 DTCI_SRR_LR_CR_TstFldOpCyc "Diagnostic Trouble Code Information Extended - SRR_LR_CR : Test Failed This Operation Cycle";
BA_ "SignalType" SG_ 1200 DTCI_SRR_LR_CR_TstFldLstClr "ENM";
BA_ "SignalLongName" SG_ 1200 DTCI_SRR_LR_CR_TstFldLstClr "Diagnostic Trouble Code Information Extended - SRR_LR_CR : Test Failed Since Last Clear";
BA_ "SignalType" SG_ 1200 DTCI_SRR_LR_CR_TstFld "ENM";
BA_ "SignalLongName" SG_ 1200 DTCI_SRR_LR_CR_TstFld "Diagnostic Trouble Code Information Extended - SRR_LR_CR : Test Failed";
BA_ "SignalType" SG_ 1200 DTCI_SRR_LR_CR_PndngDTC "ENM";
BA_ "SignalLongName" SG_ 1200 DTCI_SRR_LR_CR_PndngDTC "Diagnostic Trouble Code Information Extended - SRR_LR_CR : Pending DTC";
BA_ "SignalType" SG_ 1200 DTCI_SRR_LR_CR_DTCTriggered "ENM";
BA_ "SignalLongName" SG_ 1200 DTCI_SRR_LR_CR_DTCTriggered "Diagnostic Trouble Code Information Extended - SRR_LR_CR : Diagnostic Trouble Code Triggered";
BA_ "SignalType" SG_ 1200 DTCI_SRR_LR_CR_WrnIndTrggrd "ENM";
BA_ "SignalLongName" SG_ 1200 DTCI_SRR_LR_CR_WrnIndTrggrd "Diagnostic Trouble Code Information Extended - SRR_LR_CR : Warning Indicator Triggered";
BA_ "SignalType" SG_ 1200 DTCI_SRR_LR_CR_WrnIndRqd "ENM";
BA_ "SignalLongName" SG_ 1200 DTCI_SRR_LR_CR_WrnIndRqd "Diagnostic Trouble Code Information Extended - SRR_LR_CR : Warning Indicator Requested";
BA_ "SignalLongName" SG_ 1866 DTCI_SRR_RF_DTCFailType "Diagnostic Trouble Code Information Extended - SRR_RF : Diagnostic Trouble Code Failure Type";
BA_ "SignalType" SG_ 1866 DTCI_SRR_RF_CnfrmdDTC "ENM";
BA_ "SignalLongName" SG_ 1866 DTCI_SRR_RF_CnfrmdDTC "Diagnostic Trouble Code Information Extended - SRR_RF : Confirmed DTC";
BA_ "SignalType" SG_ 1866 DTCI_SRR_RF_DTCFaultType "ENM";
BA_ "SignalLongName" SG_ 1866 DTCI_SRR_RF_DTCFaultType "Diagnostic Trouble Code Information Extended - SRR_RF : Diagnostic Trouble Code Fault Type";
BA_ "SignalLongName" SG_ 1866 DTCI_SRR_RF_DTCNumber "Diagnostic Trouble Code Information Extended - SRR_RF : Diagnostic Trouble Code Number";
BA_ "SignalLongName" SG_ 1866 DTCI_SRR_RF_DTCSource "Diagnostic Trouble Code Information Extended - SRR_RF : Diagnostic Trouble Code Source";
BA_ "SignalType" SG_ 1866 DTCI_SRR_RF_TstNCmpltdOpCyc "ENM";
BA_ "SignalLongName" SG_ 1866 DTCI_SRR_RF_TstNCmpltdOpCyc "Diagnostic Trouble Code Information Extended - SRR_RF : Test Not Completed This Operation Cycle";
BA_ "SignalType" SG_ 1866 DTCI_SRR_RF_TstNCmpltdLstClr "ENM";
BA_ "SignalLongName" SG_ 1866 DTCI_SRR_RF_TstNCmpltdLstClr "Diagnostic Trouble Code Information Extended - SRR_RF : Test Not Completed Since Last Clear";
BA_ "SignalType" SG_ 1866 DTCI_SRR_RF_TstFldOpCyc "ENM";
BA_ "SignalLongName" SG_ 1866 DTCI_SRR_RF_TstFldOpCyc "Diagnostic Trouble Code Information Extended - SRR_RF : Test Failed This Operation Cycle";
BA_ "SignalType" SG_ 1866 DTCI_SRR_RF_TstFldLstClr "ENM";
BA_ "SignalLongName" SG_ 1866 DTCI_SRR_RF_TstFldLstClr "Diagnostic Trouble Code Information Extended - SRR_RF : Test Failed Since Last Clear";
BA_ "SignalType" SG_ 1866 DTCI_SRR_RF_TstFld "ENM";
BA_ "SignalLongName" SG_ 1866 DTCI_SRR_RF_TstFld "Diagnostic Trouble Code Information Extended - SRR_RF : Test Failed";
BA_ "SignalType" SG_ 1866 DTCI_SRR_RF_PndngDTC "ENM";
BA_ "SignalLongName" SG_ 1866 DTCI_SRR_RF_PndngDTC "Diagnostic Trouble Code Information Extended - SRR_RF : Pending DTC";
BA_ "SignalType" SG_ 1866 DTCI_SRR_RF_DTCTriggered "ENM";
BA_ "SignalLongName" SG_ 1866 DTCI_SRR_RF_DTCTriggered "Diagnostic Trouble Code Information Extended - SRR_RF : Diagnostic Trouble Code Triggered";
BA_ "SignalType" SG_ 1866 DTCI_SRR_RF_WrnIndTrggrd "ENM";
BA_ "SignalLongName" SG_ 1866 DTCI_SRR_RF_WrnIndTrggrd "Diagnostic Trouble Code Information Extended - SRR_RF : Warning Indicator Triggered";
BA_ "SignalType" SG_ 1866 DTCI_SRR_RF_WrnIndRqd "ENM";
BA_ "SignalLongName" SG_ 1866 DTCI_SRR_RF_WrnIndRqd "Diagnostic Trouble Code Information Extended - SRR_RF : Warning Indicator Requested";
VAL_ 1219 DTCI_HVAC_FP_F_CnfrmdDTC 0 "FALSE" 1 "TRUE" ;
VAL_ 1219 DTCI_HVAC_FP_F_DTCFaultType 0 "Not Supported" 1 "Type A" 2 "Type B" 3 "Type C" ;
VAL_ 1219 DTCI_HVAC_FP_F_TstNCmpltdOpCyc 0 "FALSE" 1 "TRUE" ;
VAL_ 1219 DTCI_HVAC_FP_F_TstNCmpltdLstClr 0 "FALSE" 1 "TRUE" ;
VAL_ 1219 DTCI_HVAC_FP_F_TstFldOpCyc 0 "FALSE" 1 "TRUE" ;
VAL_ 1219 DTCI_HVAC_FP_F_TstFldLstClr 0 "FALSE" 1 "TRUE" ;
VAL_ 1219 DTCI_HVAC_FP_F_TstFld 0 "FALSE" 1 "TRUE" ;
VAL_ 1219 DTCI_HVAC_FP_F_PndngDTC 0 "FALSE" 1 "TRUE" ;
VAL_ 1219 DTCI_HVAC_FP_F_DTCTriggered 0 "FALSE" 1 "TRUE" ;
VAL_ 1219 DTCI_HVAC_FP_F_WrnIndTrggrd 0 "FALSE" 1 "TRUE" ;
VAL_ 1219 DTCI_HVAC_FP_F_WrnIndRqd 0 "FALSE" 1 "TRUE" ;
VAL_ 1847 DTCI_HVAC_FP_R_CnfrmdDTC 0 "FALSE" 1 "TRUE" ;
VAL_ 1847 DTCI_HVAC_FP_R_DTCFaultType 0 "Not Supported" 1 "Type A" 2 "Type B" 3 "Type C" ;
VAL_ 1847 DTCI_HVAC_FP_R_TstNCmpltdOpCyc 0 "FALSE" 1 "TRUE" ;
VAL_ 1847 DTCI_HVAC_FP_R_TstNCmpltdLstClr 0 "FALSE" 1 "TRUE" ;
VAL_ 1847 DTCI_HVAC_FP_R_TstFldOpCyc 0 "FALSE" 1 "TRUE" ;
VAL_ 1847 DTCI_HVAC_FP_R_TstFldLstClr 0 "FALSE" 1 "TRUE" ;
VAL_ 1847 DTCI_HVAC_FP_R_TstFld 0 "FALSE" 1 "TRUE" ;
VAL_ 1847 DTCI_HVAC_FP_R_PndngDTC 0 "FALSE" 1 "TRUE" ;
VAL_ 1847 DTCI_HVAC_FP_R_DTCTriggered 0 "FALSE" 1 "TRUE" ;
VAL_ 1847 DTCI_HVAC_FP_R_WrnIndTrggrd 0 "FALSE" 1 "TRUE" ;
VAL_ 1847 DTCI_HVAC_FP_R_WrnIndRqd 0 "FALSE" 1 "TRUE" ;
VAL_ 1218 DTCI_ICCM_CnfrmdDTC 0 "FALSE" 1 "TRUE" ;
VAL_ 1218 DTCI_ICCM_DTCFaultType 0 "Not Supported" 1 "Type A" 2 "Type B" 3 "Type C" ;
VAL_ 1218 DTCI_ICCM_TstNCmpltdOpCyc 0 "FALSE" 1 "TRUE" ;
VAL_ 1218 DTCI_ICCM_TstNCmpltdLstClr 0 "FALSE" 1 "TRUE" ;
VAL_ 1218 DTCI_ICCM_TstFldOpCyc 0 "FALSE" 1 "TRUE" ;
VAL_ 1218 DTCI_ICCM_TstFldLstClr 0 "FALSE" 1 "TRUE" ;
VAL_ 1218 DTCI_ICCM_TstFld 0 "FALSE" 1 "TRUE" ;
VAL_ 1218 DTCI_ICCM_PndngDTC 0 "FALSE" 1 "TRUE" ;
VAL_ 1218 DTCI_ICCM_DTCTriggered 0 "FALSE" 1 "TRUE" ;
VAL_ 1218 DTCI_ICCM_WrnIndTrggrd 0 "FALSE" 1 "TRUE" ;
VAL_ 1218 DTCI_ICCM_WrnIndRqd 0 "FALSE" 1 "TRUE" ;
VAL_ 1848 DTCI_ICS_Info_CnfrmdDTC 0 "FALSE" 1 "TRUE" ;
VAL_ 1848 DTCI_ICS_Info_DTCFaultType 0 "Not Supported" 1 "Type A" 2 "Type B" 3 "Type C" ;
VAL_ 1848 DTCI_ICS_Info_TstNCmpltdOpCyc 0 "FALSE" 1 "TRUE" ;
VAL_ 1848 DTCI_ICS_Info_TstNCmpltdLstClr 0 "FALSE" 1 "TRUE" ;
VAL_ 1848 DTCI_ICS_Info_TstFldOpCyc 0 "FALSE" 1 "TRUE" ;
VAL_ 1848 DTCI_ICS_Info_TstFldLstClr 0 "FALSE" 1 "TRUE" ;
VAL_ 1848 DTCI_ICS_Info_TstFld 0 "FALSE" 1 "TRUE" ;
VAL_ 1848 DTCI_ICS_Info_PndngDTC 0 "FALSE" 1 "TRUE" ;
VAL_ 1848 DTCI_ICS_Info_DTCTriggered 0 "FALSE" 1 "TRUE" ;
VAL_ 1848 DTCI_ICS_Info_WrnIndTrggrd 0 "FALSE" 1 "TRUE" ;
VAL_ 1848 DTCI_ICS_Info_WrnIndRqd 0 "FALSE" 1 "TRUE" ;
VAL_ 1217 DTCI_IPC_CnfrmdDTC 0 "FALSE" 1 "TRUE" ;
VAL_ 1217 DTCI_IPC_DTCFaultType 0 "Not Supported" 1 "Type A" 2 "Type B" 3 "Type C" ;
VAL_ 1217 DTCI_IPC_TstNCmpltdOpCyc 0 "FALSE" 1 "TRUE" ;
VAL_ 1217 DTCI_IPC_TstNCmpltdLstClr 0 "FALSE" 1 "TRUE" ;
VAL_ 1217 DTCI_IPC_TstFldOpCyc 0 "FALSE" 1 "TRUE" ;
VAL_ 1217 DTCI_IPC_TstFldLstClr 0 "FALSE" 1 "TRUE" ;
VAL_ 1217 DTCI_IPC_TstFld 0 "FALSE" 1 "TRUE" ;
VAL_ 1217 DTCI_IPC_PndngDTC 0 "FALSE" 1 "TRUE" ;
VAL_ 1217 DTCI_IPC_DTCTriggered 0 "FALSE" 1 "TRUE" ;
VAL_ 1217 DTCI_IPC_WrnIndTrggrd 0 "FALSE" 1 "TRUE" ;
VAL_ 1217 DTCI_IPC_WrnIndRqd 0 "FALSE" 1 "TRUE" ;
VAL_ 1849 DTCI_LIB1_CnfrmdDTC 0 "FALSE" 1 "TRUE" ;
VAL_ 1849 DTCI_LIB1_DTCFaultType 0 "Not Supported" 1 "Type A" 2 "Type B" 3 "Type C" ;
VAL_ 1849 DTCI_LIB1_TstNCmpltdOpCyc 0 "FALSE" 1 "TRUE" ;
VAL_ 1849 DTCI_LIB1_TstNCmpltdLstClr 0 "FALSE" 1 "TRUE" ;
VAL_ 1849 DTCI_LIB1_TstFldOpCyc 0 "FALSE" 1 "TRUE" ;
VAL_ 1849 DTCI_LIB1_TstFldLstClr 0 "FALSE" 1 "TRUE" ;
VAL_ 1849 DTCI_LIB1_TstFld 0 "FALSE" 1 "TRUE" ;
VAL_ 1849 DTCI_LIB1_PndngDTC 0 "FALSE" 1 "TRUE" ;
VAL_ 1849 DTCI_LIB1_DTCTriggered 0 "FALSE" 1 "TRUE" ;
VAL_ 1849 DTCI_LIB1_WrnIndTrggrd 0 "FALSE" 1 "TRUE" ;
VAL_ 1849 DTCI_LIB1_WrnIndRqd 0 "FALSE" 1 "TRUE" ;
VAL_ 1941 DTCI_LIB_48V_CnfrmdDTC 0 "FALSE" 1 "TRUE" ;
VAL_ 1941 DTCI_LIB_48V_DTCFaultType 0 "Not Supported" 1 "Type A" 2 "Type B" 3 "Type C" ;
VAL_ 1941 DTCI_LIB_48V_TstNCmpltdOpCyc 0 "FALSE" 1 "TRUE" ;
VAL_ 1941 DTCI_LIB_48V_TstNCmpltdLstClr 0 "FALSE" 1 "TRUE" ;
VAL_ 1941 DTCI_LIB_48V_TstFldOpCyc 0 "FALSE" 1 "TRUE" ;
VAL_ 1941 DTCI_LIB_48V_TstFldLstClr 0 "FALSE" 1 "TRUE" ;
VAL_ 1941 DTCI_LIB_48V_TstFld 0 "FALSE" 1 "TRUE" ;
VAL_ 1941 DTCI_LIB_48V_PndngDTC 0 "FALSE" 1 "TRUE" ;
VAL_ 1941 DTCI_LIB_48V_DTCTriggered 0 "FALSE" 1 "TRUE" ;
VAL_ 1941 DTCI_LIB_48V_WrnIndTrggrd 0 "FALSE" 1 "TRUE" ;
VAL_ 1941 DTCI_LIB_48V_WrnIndRqd 0 "FALSE" 1 "TRUE" ;
VAL_ 1850 DTCI_LRR_CnfrmdDTC 0 "FALSE" 1 "TRUE" ;
VAL_ 1850 DTCI_LRR_DTCFaultType 0 "Not Supported" 1 "Type A" 2 "Type B" 3 "Type C" ;
VAL_ 1850 DTCI_LRR_TstNCmpltdOpCyc 0 "FALSE" 1 "TRUE" ;
VAL_ 1850 DTCI_LRR_TstNCmpltdLstClr 0 "FALSE" 1 "TRUE" ;
VAL_ 1850 DTCI_LRR_TstFldOpCyc 0 "FALSE" 1 "TRUE" ;
VAL_ 1850 DTCI_LRR_TstFldLstClr 0 "FALSE" 1 "TRUE" ;
VAL_ 1850 DTCI_LRR_TstFld 0 "FALSE" 1 "TRUE" ;
VAL_ 1850 DTCI_LRR_PndngDTC 0 "FALSE" 1 "TRUE" ;
VAL_ 1850 DTCI_LRR_DTCTriggered 0 "FALSE" 1 "TRUE" ;
VAL_ 1850 DTCI_LRR_WrnIndTrggrd 0 "FALSE" 1 "TRUE" ;
VAL_ 1850 DTCI_LRR_WrnIndRqd 0 "FALSE" 1 "TRUE" ;
VAL_ 1215 DTCI_MFC_CnfrmdDTC 0 "FALSE" 1 "TRUE" ;
VAL_ 1215 DTCI_MFC_DTCFaultType 0 "Not Supported" 1 "Type A" 2 "Type B" 3 "Type C" ;
VAL_ 1215 DTCI_MFC_TstNCmpltdOpCyc 0 "FALSE" 1 "TRUE" ;
VAL_ 1215 DTCI_MFC_TstNCmpltdLstClr 0 "FALSE" 1 "TRUE" ;
VAL_ 1215 DTCI_MFC_TstFldOpCyc 0 "FALSE" 1 "TRUE" ;
VAL_ 1215 DTCI_MFC_TstFldLstClr 0 "FALSE" 1 "TRUE" ;
VAL_ 1215 DTCI_MFC_TstFld 0 "FALSE" 1 "TRUE" ;
VAL_ 1215 DTCI_MFC_PndngDTC 0 "FALSE" 1 "TRUE" ;
VAL_ 1215 DTCI_MFC_DTCTriggered 0 "FALSE" 1 "TRUE" ;
VAL_ 1215 DTCI_MFC_WrnIndTrggrd 0 "FALSE" 1 "TRUE" ;
VAL_ 1215 DTCI_MFC_WrnIndRqd 0 "FALSE" 1 "TRUE" ;
VAL_ 1851 DTCI_MRCM_L_CnfrmdDTC 0 "FALSE" 1 "TRUE" ;
VAL_ 1851 DTCI_MRCM_L_DTCFaultType 0 "Not Supported" 1 "Type A" 2 "Type B" 3 "Type C" ;
VAL_ 1851 DTCI_MRCM_L_TstNCmpltdOpCyc 0 "FALSE" 1 "TRUE" ;
VAL_ 1851 DTCI_MRCM_L_TstNCmpltdLstClr 0 "FALSE" 1 "TRUE" ;
VAL_ 1851 DTCI_MRCM_L_TstFldOpCyc 0 "FALSE" 1 "TRUE" ;
VAL_ 1851 DTCI_MRCM_L_TstFldLstClr 0 "FALSE" 1 "TRUE" ;
VAL_ 1851 DTCI_MRCM_L_TstFld 0 "FALSE" 1 "TRUE" ;
VAL_ 1851 DTCI_MRCM_L_PndngDTC 0 "FALSE" 1 "TRUE" ;
VAL_ 1851 DTCI_MRCM_L_DTCTriggered 0 "FALSE" 1 "TRUE" ;
VAL_ 1851 DTCI_MRCM_L_WrnIndTrggrd 0 "FALSE" 1 "TRUE" ;
VAL_ 1851 DTCI_MRCM_L_WrnIndRqd 0 "FALSE" 1 "TRUE" ;
VAL_ 1214 DTCI_MRCM_R_CnfrmdDTC 0 "FALSE" 1 "TRUE" ;
VAL_ 1214 DTCI_MRCM_R_DTCFaultType 0 "Not Supported" 1 "Type A" 2 "Type B" 3 "Type C" ;
VAL_ 1214 DTCI_MRCM_R_TstNCmpltdOpCyc 0 "FALSE" 1 "TRUE" ;
VAL_ 1214 DTCI_MRCM_R_TstNCmpltdLstClr 0 "FALSE" 1 "TRUE" ;
VAL_ 1214 DTCI_MRCM_R_TstFldOpCyc 0 "FALSE" 1 "TRUE" ;
VAL_ 1214 DTCI_MRCM_R_TstFldLstClr 0 "FALSE" 1 "TRUE" ;
VAL_ 1214 DTCI_MRCM_R_TstFld 0 "FALSE" 1 "TRUE" ;
VAL_ 1214 DTCI_MRCM_R_PndngDTC 0 "FALSE" 1 "TRUE" ;
VAL_ 1214 DTCI_MRCM_R_DTCTriggered 0 "FALSE" 1 "TRUE" ;
VAL_ 1214 DTCI_MRCM_R_WrnIndTrggrd 0 "FALSE" 1 "TRUE" ;
VAL_ 1214 DTCI_MRCM_R_WrnIndRqd 0 "FALSE" 1 "TRUE" ;
VAL_ 1852 DTCI_MSB1_CnfrmdDTC 0 "FALSE" 1 "TRUE" ;
VAL_ 1852 DTCI_MSB1_DTCFaultType 0 "Not Supported" 1 "Type A" 2 "Type B" 3 "Type C" ;
VAL_ 1852 DTCI_MSB1_TstNCmpltdOpCyc 0 "FALSE" 1 "TRUE" ;
VAL_ 1852 DTCI_MSB1_TstNCmpltdLstClr 0 "FALSE" 1 "TRUE" ;
VAL_ 1852 DTCI_MSB1_TstFldOpCyc 0 "FALSE" 1 "TRUE" ;
VAL_ 1852 DTCI_MSB1_TstFldLstClr 0 "FALSE" 1 "TRUE" ;
VAL_ 1852 DTCI_MSB1_TstFld 0 "FALSE" 1 "TRUE" ;
VAL_ 1852 DTCI_MSB1_PndngDTC 0 "FALSE" 1 "TRUE" ;
VAL_ 1852 DTCI_MSB1_DTCTriggered 0 "FALSE" 1 "TRUE" ;
VAL_ 1852 DTCI_MSB1_WrnIndTrggrd 0 "FALSE" 1 "TRUE" ;
VAL_ 1852 DTCI_MSB1_WrnIndRqd 0 "FALSE" 1 "TRUE" ;
VAL_ 1213 DTCI_MSB2_CnfrmdDTC 0 "FALSE" 1 "TRUE" ;
VAL_ 1213 DTCI_MSB2_DTCFaultType 0 "Not Supported" 1 "Type A" 2 "Type B" 3 "Type C" ;
VAL_ 1213 DTCI_MSB2_TstNCmpltdOpCyc 0 "FALSE" 1 "TRUE" ;
VAL_ 1213 DTCI_MSB2_TstNCmpltdLstClr 0 "FALSE" 1 "TRUE" ;
VAL_ 1213 DTCI_MSB2_TstFldOpCyc 0 "FALSE" 1 "TRUE" ;
VAL_ 1213 DTCI_MSB2_TstFldLstClr 0 "FALSE" 1 "TRUE" ;
VAL_ 1213 DTCI_MSB2_TstFld 0 "FALSE" 1 "TRUE" ;
VAL_ 1213 DTCI_MSB2_PndngDTC 0 "FALSE" 1 "TRUE" ;
VAL_ 1213 DTCI_MSB2_DTCTriggered 0 "FALSE" 1 "TRUE" ;
VAL_ 1213 DTCI_MSB2_WrnIndTrggrd 0 "FALSE" 1 "TRUE" ;
VAL_ 1213 DTCI_MSB2_WrnIndRqd 0 "FALSE" 1 "TRUE" ;
VAL_ 1853 DTCI_MSM_D_CnfrmdDTC 0 "FALSE" 1 "TRUE" ;
VAL_ 1853 DTCI_MSM_D_DTCFaultType 0 "Not Supported" 1 "Type A" 2 "Type B" 3 "Type C" ;
VAL_ 1853 DTCI_MSM_D_TstNCmpltdOpCyc 0 "FALSE" 1 "TRUE" ;
VAL_ 1853 DTCI_MSM_D_TstNCmpltdLstClr 0 "FALSE" 1 "TRUE" ;
VAL_ 1853 DTCI_MSM_D_TstFldOpCyc 0 "FALSE" 1 "TRUE" ;
VAL_ 1853 DTCI_MSM_D_TstFldLstClr 0 "FALSE" 1 "TRUE" ;
VAL_ 1853 DTCI_MSM_D_TstFld 0 "FALSE" 1 "TRUE" ;
VAL_ 1853 DTCI_MSM_D_PndngDTC 0 "FALSE" 1 "TRUE" ;
VAL_ 1853 DTCI_MSM_D_DTCTriggered 0 "FALSE" 1 "TRUE" ;
VAL_ 1853 DTCI_MSM_D_WrnIndTrggrd 0 "FALSE" 1 "TRUE" ;
VAL_ 1853 DTCI_MSM_D_WrnIndRqd 0 "FALSE" 1 "TRUE" ;
VAL_ 1212 DTCI_MSM_LR_CnfrmdDTC 0 "FALSE" 1 "TRUE" ;
VAL_ 1212 DTCI_MSM_LR_DTCFaultType 0 "Not Supported" 1 "Type A" 2 "Type B" 3 "Type C" ;
VAL_ 1212 DTCI_MSM_LR_TstNCmpltdOpCyc 0 "FALSE" 1 "TRUE" ;
VAL_ 1212 DTCI_MSM_LR_TstNCmpltdLstClr 0 "FALSE" 1 "TRUE" ;
VAL_ 1212 DTCI_MSM_LR_TstFldOpCyc 0 "FALSE" 1 "TRUE" ;
VAL_ 1212 DTCI_MSM_LR_TstFldLstClr 0 "FALSE" 1 "TRUE" ;
VAL_ 1212 DTCI_MSM_LR_TstFld 0 "FALSE" 1 "TRUE" ;
VAL_ 1212 DTCI_MSM_LR_PndngDTC 0 "FALSE" 1 "TRUE" ;
VAL_ 1212 DTCI_MSM_LR_DTCTriggered 0 "FALSE" 1 "TRUE" ;
VAL_ 1212 DTCI_MSM_LR_WrnIndTrggrd 0 "FALSE" 1 "TRUE" ;
VAL_ 1212 DTCI_MSM_LR_WrnIndRqd 0 "FALSE" 1 "TRUE" ;
VAL_ 1854 DTCI_MSM_P_CnfrmdDTC 0 "FALSE" 1 "TRUE" ;
VAL_ 1854 DTCI_MSM_P_DTCFaultType 0 "Not Supported" 1 "Type A" 2 "Type B" 3 "Type C" ;
VAL_ 1854 DTCI_MSM_P_TstNCmpltdOpCyc 0 "FALSE" 1 "TRUE" ;
VAL_ 1854 DTCI_MSM_P_TstNCmpltdLstClr 0 "FALSE" 1 "TRUE" ;
VAL_ 1854 DTCI_MSM_P_TstFldOpCyc 0 "FALSE" 1 "TRUE" ;
VAL_ 1854 DTCI_MSM_P_TstFldLstClr 0 "FALSE" 1 "TRUE" ;
VAL_ 1854 DTCI_MSM_P_TstFld 0 "FALSE" 1 "TRUE" ;
VAL_ 1854 DTCI_MSM_P_PndngDTC 0 "FALSE" 1 "TRUE" ;
VAL_ 1854 DTCI_MSM_P_DTCTriggered 0 "FALSE" 1 "TRUE" ;
VAL_ 1854 DTCI_MSM_P_WrnIndTrggrd 0 "FALSE" 1 "TRUE" ;
VAL_ 1854 DTCI_MSM_P_WrnIndRqd 0 "FALSE" 1 "TRUE" ;
VAL_ 1211 DTCI_MSM_RR_CnfrmdDTC 0 "FALSE" 1 "TRUE" ;
VAL_ 1211 DTCI_MSM_RR_DTCFaultType 0 "Not Supported" 1 "Type A" 2 "Type B" 3 "Type C" ;
VAL_ 1211 DTCI_MSM_RR_TstNCmpltdOpCyc 0 "FALSE" 1 "TRUE" ;
VAL_ 1211 DTCI_MSM_RR_TstNCmpltdLstClr 0 "FALSE" 1 "TRUE" ;
VAL_ 1211 DTCI_MSM_RR_TstFldOpCyc 0 "FALSE" 1 "TRUE" ;
VAL_ 1211 DTCI_MSM_RR_TstFldLstClr 0 "FALSE" 1 "TRUE" ;
VAL_ 1211 DTCI_MSM_RR_TstFld 0 "FALSE" 1 "TRUE" ;
VAL_ 1211 DTCI_MSM_RR_PndngDTC 0 "FALSE" 1 "TRUE" ;
VAL_ 1211 DTCI_MSM_RR_DTCTriggered 0 "FALSE" 1 "TRUE" ;
VAL_ 1211 DTCI_MSM_RR_WrnIndTrggrd 0 "FALSE" 1 "TRUE" ;
VAL_ 1211 DTCI_MSM_RR_WrnIndRqd 0 "FALSE" 1 "TRUE" ;
VAL_ 1855 DTCI_MTCM_L_CnfrmdDTC 0 "FALSE" 1 "TRUE" ;
VAL_ 1855 DTCI_MTCM_L_DTCFaultType 0 "Not Supported" 1 "Type A" 2 "Type B" 3 "Type C" ;
VAL_ 1855 DTCI_MTCM_L_TstNCmpltdOpCyc 0 "FALSE" 1 "TRUE" ;
VAL_ 1855 DTCI_MTCM_L_TstNCmpltdLstClr 0 "FALSE" 1 "TRUE" ;
VAL_ 1855 DTCI_MTCM_L_TstFldOpCyc 0 "FALSE" 1 "TRUE" ;
VAL_ 1855 DTCI_MTCM_L_TstFldLstClr 0 "FALSE" 1 "TRUE" ;
VAL_ 1855 DTCI_MTCM_L_TstFld 0 "FALSE" 1 "TRUE" ;
VAL_ 1855 DTCI_MTCM_L_PndngDTC 0 "FALSE" 1 "TRUE" ;
VAL_ 1855 DTCI_MTCM_L_DTCTriggered 0 "FALSE" 1 "TRUE" ;
VAL_ 1855 DTCI_MTCM_L_WrnIndTrggrd 0 "FALSE" 1 "TRUE" ;
VAL_ 1855 DTCI_MTCM_L_WrnIndRqd 0 "FALSE" 1 "TRUE" ;
VAL_ 1210 DTCI_MTCM_R_CnfrmdDTC 0 "FALSE" 1 "TRUE" ;
VAL_ 1210 DTCI_MTCM_R_DTCFaultType 0 "Not Supported" 1 "Type A" 2 "Type B" 3 "Type C" ;
VAL_ 1210 DTCI_MTCM_R_TstNCmpltdOpCyc 0 "FALSE" 1 "TRUE" ;
VAL_ 1210 DTCI_MTCM_R_TstNCmpltdLstClr 0 "FALSE" 1 "TRUE" ;
VAL_ 1210 DTCI_MTCM_R_TstFldOpCyc 0 "FALSE" 1 "TRUE" ;
VAL_ 1210 DTCI_MTCM_R_TstFldLstClr 0 "FALSE" 1 "TRUE" ;
VAL_ 1210 DTCI_MTCM_R_TstFld 0 "FALSE" 1 "TRUE" ;
VAL_ 1210 DTCI_MTCM_R_PndngDTC 0 "FALSE" 1 "TRUE" ;
VAL_ 1210 DTCI_MTCM_R_DTCTriggered 0 "FALSE" 1 "TRUE" ;
VAL_ 1210 DTCI_MTCM_R_WrnIndTrggrd 0 "FALSE" 1 "TRUE" ;
VAL_ 1210 DTCI_MTCM_R_WrnIndRqd 0 "FALSE" 1 "TRUE" ;
VAL_ 1856 DTCI_NVM_CnfrmdDTC 0 "FALSE" 1 "TRUE" ;
VAL_ 1856 DTCI_NVM_DTCFaultType 0 "Not Supported" 1 "Type A" 2 "Type B" 3 "Type C" ;
VAL_ 1856 DTCI_NVM_TstNCmpltdOpCyc 0 "FALSE" 1 "TRUE" ;
VAL_ 1856 DTCI_NVM_TstNCmpltdLstClr 0 "FALSE" 1 "TRUE" ;
VAL_ 1856 DTCI_NVM_TstFldOpCyc 0 "FALSE" 1 "TRUE" ;
VAL_ 1856 DTCI_NVM_TstFldLstClr 0 "FALSE" 1 "TRUE" ;
VAL_ 1856 DTCI_NVM_TstFld 0 "FALSE" 1 "TRUE" ;
VAL_ 1856 DTCI_NVM_PndngDTC 0 "FALSE" 1 "TRUE" ;
VAL_ 1856 DTCI_NVM_DTCTriggered 0 "FALSE" 1 "TRUE" ;
VAL_ 1856 DTCI_NVM_WrnIndTrggrd 0 "FALSE" 1 "TRUE" ;
VAL_ 1856 DTCI_NVM_WrnIndRqd 0 "FALSE" 1 "TRUE" ;
VAL_ 1957 DTCI_ODS2_CnfrmdDTC 0 "FALSE" 1 "TRUE" ;
VAL_ 1957 DTCI_ODS2_DTCFaultType 0 "Not Supported" 1 "Type A" 2 "Type B" 3 "Type C" ;
VAL_ 1957 DTCI_ODS2_TstNCmpltdOpCyc 0 "FALSE" 1 "TRUE" ;
VAL_ 1957 DTCI_ODS2_TstNCmpltdLstClr 0 "FALSE" 1 "TRUE" ;
VAL_ 1957 DTCI_ODS2_TstFldOpCyc 0 "FALSE" 1 "TRUE" ;
VAL_ 1957 DTCI_ODS2_TstFldLstClr 0 "FALSE" 1 "TRUE" ;
VAL_ 1957 DTCI_ODS2_TstFld 0 "FALSE" 1 "TRUE" ;
VAL_ 1957 DTCI_ODS2_PndngDTC 0 "FALSE" 1 "TRUE" ;
VAL_ 1957 DTCI_ODS2_DTCTriggered 0 "FALSE" 1 "TRUE" ;
VAL_ 1957 DTCI_ODS2_WrnIndTrggrd 0 "FALSE" 1 "TRUE" ;
VAL_ 1957 DTCI_ODS2_WrnIndRqd 0 "FALSE" 1 "TRUE" ;
VAL_ 1111 DTCI_ODS_CnfrmdDTC 0 "FALSE" 1 "TRUE" ;
VAL_ 1111 DTCI_ODS_DTCFaultType 0 "Not Supported" 1 "Type A" 2 "Type B" 3 "Type C" ;
VAL_ 1111 DTCI_ODS_TstNCmpltdOpCyc 0 "FALSE" 1 "TRUE" ;
VAL_ 1111 DTCI_ODS_TstNCmpltdLstClr 0 "FALSE" 1 "TRUE" ;
VAL_ 1111 DTCI_ODS_TstFldOpCyc 0 "FALSE" 1 "TRUE" ;
VAL_ 1111 DTCI_ODS_TstFldLstClr 0 "FALSE" 1 "TRUE" ;
VAL_ 1111 DTCI_ODS_TstFld 0 "FALSE" 1 "TRUE" ;
VAL_ 1111 DTCI_ODS_PndngDTC 0 "FALSE" 1 "TRUE" ;
VAL_ 1111 DTCI_ODS_DTCTriggered 0 "FALSE" 1 "TRUE" ;
VAL_ 1111 DTCI_ODS_WrnIndTrggrd 0 "FALSE" 1 "TRUE" ;
VAL_ 1111 DTCI_ODS_WrnIndRqd 0 "FALSE" 1 "TRUE" ;
VAL_ 1209 DTCI_PA_CnfrmdDTC 0 "FALSE" 1 "TRUE" ;
VAL_ 1209 DTCI_PA_DTCFaultType 0 "Not Supported" 1 "Type A" 2 "Type B" 3 "Type C" ;
VAL_ 1209 DTCI_PA_TstNCmpltdOpCyc 0 "FALSE" 1 "TRUE" ;
VAL_ 1209 DTCI_PA_TstNCmpltdLstClr 0 "FALSE" 1 "TRUE" ;
VAL_ 1209 DTCI_PA_TstFldOpCyc 0 "FALSE" 1 "TRUE" ;
VAL_ 1209 DTCI_PA_TstFldLstClr 0 "FALSE" 1 "TRUE" ;
VAL_ 1209 DTCI_PA_TstFld 0 "FALSE" 1 "TRUE" ;
VAL_ 1209 DTCI_PA_PndngDTC 0 "FALSE" 1 "TRUE" ;
VAL_ 1209 DTCI_PA_DTCTriggered 0 "FALSE" 1 "TRUE" ;
VAL_ 1209 DTCI_PA_WrnIndTrggrd 0 "FALSE" 1 "TRUE" ;
VAL_ 1209 DTCI_PA_WrnIndRqd 0 "FALSE" 1 "TRUE" ;
VAL_ 1170 DTCI_PCM_CnfrmdDTC 0 "FALSE" 1 "TRUE" ;
VAL_ 1170 DTCI_PCM_DTCFaultType 0 "Not Supported" 1 "Type A" 2 "Type B" 3 "Type C" ;
VAL_ 1170 DTCI_PCM_TstNCmpltdOpCyc 0 "FALSE" 1 "TRUE" ;
VAL_ 1170 DTCI_PCM_TstNCmpltdLstClr 0 "FALSE" 1 "TRUE" ;
VAL_ 1170 DTCI_PCM_TstFldOpCyc 0 "FALSE" 1 "TRUE" ;
VAL_ 1170 DTCI_PCM_TstFldLstClr 0 "FALSE" 1 "TRUE" ;
VAL_ 1170 DTCI_PCM_TstFld 0 "FALSE" 1 "TRUE" ;
VAL_ 1170 DTCI_PCM_PndngDTC 0 "FALSE" 1 "TRUE" ;
VAL_ 1170 DTCI_PCM_DTCTriggered 0 "FALSE" 1 "TRUE" ;
VAL_ 1170 DTCI_PCM_WrnIndTrggrd 0 "FALSE" 1 "TRUE" ;
VAL_ 1170 DTCI_PCM_WrnIndRqd 0 "FALSE" 1 "TRUE" ;
VAL_ 1857 DTCI_PDR_CnfrmdDTC 0 "FALSE" 1 "TRUE" ;
VAL_ 1857 DTCI_PDR_DTCFaultType 0 "Not Supported" 1 "Type A" 2 "Type B" 3 "Type C" ;
VAL_ 1857 DTCI_PDR_TstNCmpltdOpCyc 0 "FALSE" 1 "TRUE" ;
VAL_ 1857 DTCI_PDR_TstNCmpltdLstClr 0 "FALSE" 1 "TRUE" ;
VAL_ 1857 DTCI_PDR_TstFldOpCyc 0 "FALSE" 1 "TRUE" ;
VAL_ 1857 DTCI_PDR_TstFldLstClr 0 "FALSE" 1 "TRUE" ;
VAL_ 1857 DTCI_PDR_TstFld 0 "FALSE" 1 "TRUE" ;
VAL_ 1857 DTCI_PDR_PndngDTC 0 "FALSE" 1 "TRUE" ;
VAL_ 1857 DTCI_PDR_DTCTriggered 0 "FALSE" 1 "TRUE" ;
VAL_ 1857 DTCI_PDR_WrnIndTrggrd 0 "FALSE" 1 "TRUE" ;
VAL_ 1857 DTCI_PDR_WrnIndRqd 0 "FALSE" 1 "TRUE" ;
VAL_ 1168 DTCI_PFCM_CnfrmdDTC 0 "FALSE" 1 "TRUE" ;
VAL_ 1168 DTCI_PFCM_DTCFaultType 0 "Not Supported" 1 "Type A" 2 "Type B" 3 "Type C" ;
VAL_ 1168 DTCI_PFCM_TstNCmpltdOpCyc 0 "FALSE" 1 "TRUE" ;
VAL_ 1168 DTCI_PFCM_TstNCmpltdLstClr 0 "FALSE" 1 "TRUE" ;
VAL_ 1168 DTCI_PFCM_TstFldOpCyc 0 "FALSE" 1 "TRUE" ;
VAL_ 1168 DTCI_PFCM_TstFldLstClr 0 "FALSE" 1 "TRUE" ;
VAL_ 1168 DTCI_PFCM_TstFld 0 "FALSE" 1 "TRUE" ;
VAL_ 1168 DTCI_PFCM_PndngDTC 0 "FALSE" 1 "TRUE" ;
VAL_ 1168 DTCI_PFCM_DTCTriggered 0 "FALSE" 1 "TRUE" ;
VAL_ 1168 DTCI_PFCM_WrnIndTrggrd 0 "FALSE" 1 "TRUE" ;
VAL_ 1168 DTCI_PFCM_WrnIndRqd 0 "FALSE" 1 "TRUE" ;
VAL_ 1099 DTCI_PLCM_CnfrmdDTC 0 "FALSE" 1 "TRUE" ;
VAL_ 1099 DTCI_PLCM_DTCFaultType 0 "Not Supported" 1 "Type A" 2 "Type B" 3 "Type C" ;
VAL_ 1099 DTCI_PLCM_TstNCmpltdOpCyc 0 "FALSE" 1 "TRUE" ;
VAL_ 1099 DTCI_PLCM_TstNCmpltdLstClr 0 "FALSE" 1 "TRUE" ;
VAL_ 1099 DTCI_PLCM_TstFldOpCyc 0 "FALSE" 1 "TRUE" ;
VAL_ 1099 DTCI_PLCM_TstFldLstClr 0 "FALSE" 1 "TRUE" ;
VAL_ 1099 DTCI_PLCM_TstFld 0 "FALSE" 1 "TRUE" ;
VAL_ 1099 DTCI_PLCM_PndngDTC 0 "FALSE" 1 "TRUE" ;
VAL_ 1099 DTCI_PLCM_DTCTriggered 0 "FALSE" 1 "TRUE" ;
VAL_ 1099 DTCI_PLCM_WrnIndTrggrd 0 "FALSE" 1 "TRUE" ;
VAL_ 1099 DTCI_PLCM_WrnIndRqd 0 "FALSE" 1 "TRUE" ;
VAL_ 1208 DTCI_PTM_CnfrmdDTC 0 "FALSE" 1 "TRUE" ;
VAL_ 1208 DTCI_PTM_DTCFaultType 0 "Not Supported" 1 "Type A" 2 "Type B" 3 "Type C" ;
VAL_ 1208 DTCI_PTM_TstNCmpltdOpCyc 0 "FALSE" 1 "TRUE" ;
VAL_ 1208 DTCI_PTM_TstNCmpltdLstClr 0 "FALSE" 1 "TRUE" ;
VAL_ 1208 DTCI_PTM_TstFldOpCyc 0 "FALSE" 1 "TRUE" ;
VAL_ 1208 DTCI_PTM_TstFldLstClr 0 "FALSE" 1 "TRUE" ;
VAL_ 1208 DTCI_PTM_TstFld 0 "FALSE" 1 "TRUE" ;
VAL_ 1208 DTCI_PTM_PndngDTC 0 "FALSE" 1 "TRUE" ;
VAL_ 1208 DTCI_PTM_DTCTriggered 0 "FALSE" 1 "TRUE" ;
VAL_ 1208 DTCI_PTM_WrnIndTrggrd 0 "FALSE" 1 "TRUE" ;
VAL_ 1208 DTCI_PTM_WrnIndRqd 0 "FALSE" 1 "TRUE" ;
VAL_ 1858 DTCI_RDCM_CnfrmdDTC 0 "FALSE" 1 "TRUE" ;
VAL_ 1858 DTCI_RDCM_DTCFaultType 0 "Not Supported" 1 "Type A" 2 "Type B" 3 "Type C" ;
VAL_ 1858 DTCI_RDCM_TstNCmpltdOpCyc 0 "FALSE" 1 "TRUE" ;
VAL_ 1858 DTCI_RDCM_TstNCmpltdLstClr 0 "FALSE" 1 "TRUE" ;
VAL_ 1858 DTCI_RDCM_TstFldOpCyc 0 "FALSE" 1 "TRUE" ;
VAL_ 1858 DTCI_RDCM_TstFldLstClr 0 "FALSE" 1 "TRUE" ;
VAL_ 1858 DTCI_RDCM_TstFld 0 "FALSE" 1 "TRUE" ;
VAL_ 1858 DTCI_RDCM_PndngDTC 0 "FALSE" 1 "TRUE" ;
VAL_ 1858 DTCI_RDCM_DTCTriggered 0 "FALSE" 1 "TRUE" ;
VAL_ 1858 DTCI_RDCM_WrnIndTrggrd 0 "FALSE" 1 "TRUE" ;
VAL_ 1858 DTCI_RDCM_WrnIndRqd 0 "FALSE" 1 "TRUE" ;
VAL_ 1918 DTCI_RSI_CnfrmdDTC 0 "FALSE" 1 "TRUE" ;
VAL_ 1918 DTCI_RSI_DTCFaultType 0 "Not Supported" 1 "Type A" 2 "Type B" 3 "Type C" ;
VAL_ 1918 DTCI_RSI_TstNCmpltdOpCyc 0 "FALSE" 1 "TRUE" ;
VAL_ 1918 DTCI_RSI_TstNCmpltdLstClr 0 "FALSE" 1 "TRUE" ;
VAL_ 1918 DTCI_RSI_TstFldOpCyc 0 "FALSE" 1 "TRUE" ;
VAL_ 1918 DTCI_RSI_TstFldLstClr 0 "FALSE" 1 "TRUE" ;
VAL_ 1918 DTCI_RSI_TstFld 0 "FALSE" 1 "TRUE" ;
VAL_ 1918 DTCI_RSI_PndngDTC 0 "FALSE" 1 "TRUE" ;
VAL_ 1918 DTCI_RSI_DTCTriggered 0 "FALSE" 1 "TRUE" ;
VAL_ 1918 DTCI_RSI_WrnIndTrggrd 0 "FALSE" 1 "TRUE" ;
VAL_ 1918 DTCI_RSI_WrnIndRqd 0 "FALSE" 1 "TRUE" ;
VAL_ 1859 DTCI_RadioLow_CnfrmdDTC 0 "FALSE" 1 "TRUE" ;
VAL_ 1859 DTCI_RadioLow_DTCFaultType 0 "Not Supported" 1 "Type A" 2 "Type B" 3 "Type C" ;
VAL_ 1859 DTCI_RadioLow_TstNCmpltdOpCyc 0 "FALSE" 1 "TRUE" ;
VAL_ 1859 DTCI_RadioLow_TstNCmpltdLstClr 0 "FALSE" 1 "TRUE" ;
VAL_ 1859 DTCI_RadioLow_TstFldOpCyc 0 "FALSE" 1 "TRUE" ;
VAL_ 1859 DTCI_RadioLow_TstFldLstClr 0 "FALSE" 1 "TRUE" ;
VAL_ 1859 DTCI_RadioLow_TstFld 0 "FALSE" 1 "TRUE" ;
VAL_ 1859 DTCI_RadioLow_PndngDTC 0 "FALSE" 1 "TRUE" ;
VAL_ 1859 DTCI_RadioLow_DTCTriggered 0 "FALSE" 1 "TRUE" ;
VAL_ 1859 DTCI_RadioLow_WrnIndTrggrd 0 "FALSE" 1 "TRUE" ;
VAL_ 1859 DTCI_RadioLow_WrnIndRqd 0 "FALSE" 1 "TRUE" ;
VAL_ 1206 DTCI_SADS_CnfrmdDTC 0 "FALSE" 1 "TRUE" ;
VAL_ 1206 DTCI_SADS_DTCFaultType 0 "Not Supported" 1 "Type A" 2 "Type B" 3 "Type C" ;
VAL_ 1206 DTCI_SADS_TstNCmpltdOpCyc 0 "FALSE" 1 "TRUE" ;
VAL_ 1206 DTCI_SADS_TstNCmpltdLstClr 0 "FALSE" 1 "TRUE" ;
VAL_ 1206 DTCI_SADS_TstFldOpCyc 0 "FALSE" 1 "TRUE" ;
VAL_ 1206 DTCI_SADS_TstFldLstClr 0 "FALSE" 1 "TRUE" ;
VAL_ 1206 DTCI_SADS_TstFld 0 "FALSE" 1 "TRUE" ;
VAL_ 1206 DTCI_SADS_PndngDTC 0 "FALSE" 1 "TRUE" ;
VAL_ 1206 DTCI_SADS_DTCTriggered 0 "FALSE" 1 "TRUE" ;
VAL_ 1206 DTCI_SADS_WrnIndTrggrd 0 "FALSE" 1 "TRUE" ;
VAL_ 1206 DTCI_SADS_WrnIndRqd 0 "FALSE" 1 "TRUE" ;
VAL_ 1956 DTCI_SAM_BH_CnfrmdDTC 0 "FALSE" 1 "TRUE" ;
VAL_ 1956 DTCI_SAM_BH_DTCFaultType 0 "Not Supported" 1 "Type A" 2 "Type B" 3 "Type C" ;
VAL_ 1956 DTCI_SAM_BH_TstNCmpltdOpCyc 0 "FALSE" 1 "TRUE" ;
VAL_ 1956 DTCI_SAM_BH_TstNCmpltdLstClr 0 "FALSE" 1 "TRUE" ;
VAL_ 1956 DTCI_SAM_BH_TstFldOpCyc 0 "FALSE" 1 "TRUE" ;
VAL_ 1956 DTCI_SAM_BH_TstFldLstClr 0 "FALSE" 1 "TRUE" ;
VAL_ 1956 DTCI_SAM_BH_TstFld 0 "FALSE" 1 "TRUE" ;
VAL_ 1956 DTCI_SAM_BH_PndngDTC 0 "FALSE" 1 "TRUE" ;
VAL_ 1956 DTCI_SAM_BH_DTCTriggered 0 "FALSE" 1 "TRUE" ;
VAL_ 1956 DTCI_SAM_BH_WrnIndTrggrd 0 "FALSE" 1 "TRUE" ;
VAL_ 1956 DTCI_SAM_BH_WrnIndRqd 0 "FALSE" 1 "TRUE" ;
VAL_ 1860 DTCI_SAM_LF_CnfrmdDTC 0 "FALSE" 1 "TRUE" ;
VAL_ 1860 DTCI_SAM_LF_DTCFaultType 0 "Not Supported" 1 "Type A" 2 "Type B" 3 "Type C" ;
VAL_ 1860 DTCI_SAM_LF_TstNCmpltdOpCyc 0 "FALSE" 1 "TRUE" ;
VAL_ 1860 DTCI_SAM_LF_TstNCmpltdLstClr 0 "FALSE" 1 "TRUE" ;
VAL_ 1860 DTCI_SAM_LF_TstFldOpCyc 0 "FALSE" 1 "TRUE" ;
VAL_ 1860 DTCI_SAM_LF_TstFldLstClr 0 "FALSE" 1 "TRUE" ;
VAL_ 1860 DTCI_SAM_LF_TstFld 0 "FALSE" 1 "TRUE" ;
VAL_ 1860 DTCI_SAM_LF_PndngDTC 0 "FALSE" 1 "TRUE" ;
VAL_ 1860 DTCI_SAM_LF_DTCTriggered 0 "FALSE" 1 "TRUE" ;
VAL_ 1860 DTCI_SAM_LF_WrnIndTrggrd 0 "FALSE" 1 "TRUE" ;
VAL_ 1860 DTCI_SAM_LF_WrnIndRqd 0 "FALSE" 1 "TRUE" ;
VAL_ 1205 DTCI_SAM_LR_CnfrmdDTC 0 "FALSE" 1 "TRUE" ;
VAL_ 1205 DTCI_SAM_LR_DTCFaultType 0 "Not Supported" 1 "Type A" 2 "Type B" 3 "Type C" ;
VAL_ 1205 DTCI_SAM_LR_TstNCmpltdOpCyc 0 "FALSE" 1 "TRUE" ;
VAL_ 1205 DTCI_SAM_LR_TstNCmpltdLstClr 0 "FALSE" 1 "TRUE" ;
VAL_ 1205 DTCI_SAM_LR_TstFldOpCyc 0 "FALSE" 1 "TRUE" ;
VAL_ 1205 DTCI_SAM_LR_TstFldLstClr 0 "FALSE" 1 "TRUE" ;
VAL_ 1205 DTCI_SAM_LR_TstFld 0 "FALSE" 1 "TRUE" ;
VAL_ 1205 DTCI_SAM_LR_PndngDTC 0 "FALSE" 1 "TRUE" ;
VAL_ 1205 DTCI_SAM_LR_DTCTriggered 0 "FALSE" 1 "TRUE" ;
VAL_ 1205 DTCI_SAM_LR_WrnIndTrggrd 0 "FALSE" 1 "TRUE" ;
VAL_ 1205 DTCI_SAM_LR_WrnIndRqd 0 "FALSE" 1 "TRUE" ;
VAL_ 1861 DTCI_SAM_RF_CnfrmdDTC 0 "FALSE" 1 "TRUE" ;
VAL_ 1861 DTCI_SAM_RF_DTCFaultType 0 "Not Supported" 1 "Type A" 2 "Type B" 3 "Type C" ;
VAL_ 1861 DTCI_SAM_RF_TstNCmpltdOpCyc 0 "FALSE" 1 "TRUE" ;
VAL_ 1861 DTCI_SAM_RF_TstNCmpltdLstClr 0 "FALSE" 1 "TRUE" ;
VAL_ 1861 DTCI_SAM_RF_TstFldOpCyc 0 "FALSE" 1 "TRUE" ;
VAL_ 1861 DTCI_SAM_RF_TstFldLstClr 0 "FALSE" 1 "TRUE" ;
VAL_ 1861 DTCI_SAM_RF_TstFld 0 "FALSE" 1 "TRUE" ;
VAL_ 1861 DTCI_SAM_RF_PndngDTC 0 "FALSE" 1 "TRUE" ;
VAL_ 1861 DTCI_SAM_RF_DTCTriggered 0 "FALSE" 1 "TRUE" ;
VAL_ 1861 DTCI_SAM_RF_WrnIndTrggrd 0 "FALSE" 1 "TRUE" ;
VAL_ 1861 DTCI_SAM_RF_WrnIndRqd 0 "FALSE" 1 "TRUE" ;
VAL_ 1204 DTCI_SAM_RR_CnfrmdDTC 0 "FALSE" 1 "TRUE" ;
VAL_ 1204 DTCI_SAM_RR_DTCFaultType 0 "Not Supported" 1 "Type A" 2 "Type B" 3 "Type C" ;
VAL_ 1204 DTCI_SAM_RR_TstNCmpltdOpCyc 0 "FALSE" 1 "TRUE" ;
VAL_ 1204 DTCI_SAM_RR_TstNCmpltdLstClr 0 "FALSE" 1 "TRUE" ;
VAL_ 1204 DTCI_SAM_RR_TstFldOpCyc 0 "FALSE" 1 "TRUE" ;
VAL_ 1204 DTCI_SAM_RR_TstFldLstClr 0 "FALSE" 1 "TRUE" ;
VAL_ 1204 DTCI_SAM_RR_TstFld 0 "FALSE" 1 "TRUE" ;
VAL_ 1204 DTCI_SAM_RR_PndngDTC 0 "FALSE" 1 "TRUE" ;
VAL_ 1204 DTCI_SAM_RR_DTCTriggered 0 "FALSE" 1 "TRUE" ;
VAL_ 1204 DTCI_SAM_RR_WrnIndTrggrd 0 "FALSE" 1 "TRUE" ;
VAL_ 1204 DTCI_SAM_RR_WrnIndRqd 0 "FALSE" 1 "TRUE" ;
VAL_ 1862 DTCI_SBM_CnfrmdDTC 0 "FALSE" 1 "TRUE" ;
VAL_ 1862 DTCI_SBM_DTCFaultType 0 "Not Supported" 1 "Type A" 2 "Type B" 3 "Type C" ;
VAL_ 1862 DTCI_SBM_TstNCmpltdOpCyc 0 "FALSE" 1 "TRUE" ;
VAL_ 1862 DTCI_SBM_TstNCmpltdLstClr 0 "FALSE" 1 "TRUE" ;
VAL_ 1862 DTCI_SBM_TstFldOpCyc 0 "FALSE" 1 "TRUE" ;
VAL_ 1862 DTCI_SBM_TstFldLstClr 0 "FALSE" 1 "TRUE" ;
VAL_ 1862 DTCI_SBM_TstFld 0 "FALSE" 1 "TRUE" ;
VAL_ 1862 DTCI_SBM_PndngDTC 0 "FALSE" 1 "TRUE" ;
VAL_ 1862 DTCI_SBM_DTCTriggered 0 "FALSE" 1 "TRUE" ;
VAL_ 1862 DTCI_SBM_WrnIndTrggrd 0 "FALSE" 1 "TRUE" ;
VAL_ 1862 DTCI_SBM_WrnIndRqd 0 "FALSE" 1 "TRUE" ;
VAL_ 1203 DTCI_SBZA_L_CnfrmdDTC 0 "FALSE" 1 "TRUE" ;
VAL_ 1203 DTCI_SBZA_L_DTCFaultType 0 "Not Supported" 1 "Type A" 2 "Type B" 3 "Type C" ;
VAL_ 1203 DTCI_SBZA_L_TstNCmpltdOpCyc 0 "FALSE" 1 "TRUE" ;
VAL_ 1203 DTCI_SBZA_L_TstNCmpltdLstClr 0 "FALSE" 1 "TRUE" ;
VAL_ 1203 DTCI_SBZA_L_TstFldOpCyc 0 "FALSE" 1 "TRUE" ;
VAL_ 1203 DTCI_SBZA_L_TstFldLstClr 0 "FALSE" 1 "TRUE" ;
VAL_ 1203 DTCI_SBZA_L_TstFld 0 "FALSE" 1 "TRUE" ;
VAL_ 1203 DTCI_SBZA_L_PndngDTC 0 "FALSE" 1 "TRUE" ;
VAL_ 1203 DTCI_SBZA_L_DTCTriggered 0 "FALSE" 1 "TRUE" ;
VAL_ 1203 DTCI_SBZA_L_WrnIndTrggrd 0 "FALSE" 1 "TRUE" ;
VAL_ 1203 DTCI_SBZA_L_WrnIndRqd 0 "FALSE" 1 "TRUE" ;
VAL_ 1863 DTCI_SBZA_R_CnfrmdDTC 0 "FALSE" 1 "TRUE" ;
VAL_ 1863 DTCI_SBZA_R_DTCFaultType 0 "Not Supported" 1 "Type A" 2 "Type B" 3 "Type C" ;
VAL_ 1863 DTCI_SBZA_R_TstNCmpltdOpCyc 0 "FALSE" 1 "TRUE" ;
VAL_ 1863 DTCI_SBZA_R_TstNCmpltdLstClr 0 "FALSE" 1 "TRUE" ;
VAL_ 1863 DTCI_SBZA_R_TstFldOpCyc 0 "FALSE" 1 "TRUE" ;
VAL_ 1863 DTCI_SBZA_R_TstFldLstClr 0 "FALSE" 1 "TRUE" ;
VAL_ 1863 DTCI_SBZA_R_TstFld 0 "FALSE" 1 "TRUE" ;
VAL_ 1863 DTCI_SBZA_R_PndngDTC 0 "FALSE" 1 "TRUE" ;
VAL_ 1863 DTCI_SBZA_R_DTCTriggered 0 "FALSE" 1 "TRUE" ;
VAL_ 1863 DTCI_SBZA_R_WrnIndTrggrd 0 "FALSE" 1 "TRUE" ;
VAL_ 1863 DTCI_SBZA_R_WrnIndRqd 0 "FALSE" 1 "TRUE" ;
VAL_ 1202 DTCI_SCL_CnfrmdDTC 0 "FALSE" 1 "TRUE" ;
VAL_ 1202 DTCI_SCL_DTCFaultType 0 "Not Supported" 1 "Type A" 2 "Type B" 3 "Type C" ;
VAL_ 1202 DTCI_SCL_TstNCmpltdOpCyc 0 "FALSE" 1 "TRUE" ;
VAL_ 1202 DTCI_SCL_TstNCmpltdLstClr 0 "FALSE" 1 "TRUE" ;
VAL_ 1202 DTCI_SCL_TstFldOpCyc 0 "FALSE" 1 "TRUE" ;
VAL_ 1202 DTCI_SCL_TstFldLstClr 0 "FALSE" 1 "TRUE" ;
VAL_ 1202 DTCI_SCL_TstFld 0 "FALSE" 1 "TRUE" ;
VAL_ 1202 DTCI_SCL_PndngDTC 0 "FALSE" 1 "TRUE" ;
VAL_ 1202 DTCI_SCL_DTCTriggered 0 "FALSE" 1 "TRUE" ;
VAL_ 1202 DTCI_SCL_WrnIndTrggrd 0 "FALSE" 1 "TRUE" ;
VAL_ 1202 DTCI_SCL_WrnIndRqd 0 "FALSE" 1 "TRUE" ;
VAL_ 1919 DTCI_SDM_AV_CnfrmdDTC 0 "FALSE" 1 "TRUE" ;
VAL_ 1919 DTCI_SDM_AV_DTCFaultType 0 "Not Supported" 1 "Type A" 2 "Type B" 3 "Type C" ;
VAL_ 1919 DTCI_SDM_AV_TstNCmpltdOpCyc 0 "FALSE" 1 "TRUE" ;
VAL_ 1919 DTCI_SDM_AV_TstNCmpltdLstClr 0 "FALSE" 1 "TRUE" ;
VAL_ 1919 DTCI_SDM_AV_TstFldOpCyc 0 "FALSE" 1 "TRUE" ;
VAL_ 1919 DTCI_SDM_AV_TstFldLstClr 0 "FALSE" 1 "TRUE" ;
VAL_ 1919 DTCI_SDM_AV_TstFld 0 "FALSE" 1 "TRUE" ;
VAL_ 1919 DTCI_SDM_AV_PndngDTC 0 "FALSE" 1 "TRUE" ;
VAL_ 1919 DTCI_SDM_AV_DTCTriggered 0 "FALSE" 1 "TRUE" ;
VAL_ 1919 DTCI_SDM_AV_WrnIndTrggrd 0 "FALSE" 1 "TRUE" ;
VAL_ 1919 DTCI_SDM_AV_WrnIndRqd 0 "FALSE" 1 "TRUE" ;
VAL_ 1864 DTCI_SDM_CnfrmdDTC 0 "FALSE" 1 "TRUE" ;
VAL_ 1864 DTCI_SDM_DTCFaultType 0 "Not Supported" 1 "Type A" 2 "Type B" 3 "Type C" ;
VAL_ 1864 DTCI_SDM_TstNCmpltdOpCyc 0 "FALSE" 1 "TRUE" ;
VAL_ 1864 DTCI_SDM_TstNCmpltdLstClr 0 "FALSE" 1 "TRUE" ;
VAL_ 1864 DTCI_SDM_TstFldOpCyc 0 "FALSE" 1 "TRUE" ;
VAL_ 1864 DTCI_SDM_TstFldLstClr 0 "FALSE" 1 "TRUE" ;
VAL_ 1864 DTCI_SDM_TstFld 0 "FALSE" 1 "TRUE" ;
VAL_ 1864 DTCI_SDM_PndngDTC 0 "FALSE" 1 "TRUE" ;
VAL_ 1864 DTCI_SDM_DTCTriggered 0 "FALSE" 1 "TRUE" ;
VAL_ 1864 DTCI_SDM_WrnIndTrggrd 0 "FALSE" 1 "TRUE" ;
VAL_ 1864 DTCI_SDM_WrnIndRqd 0 "FALSE" 1 "TRUE" ;
VAL_ 1201 DTCI_SIB_CnfrmdDTC 0 "FALSE" 1 "TRUE" ;
VAL_ 1201 DTCI_SIB_DTCFaultType 0 "Not Supported" 1 "Type A" 2 "Type B" 3 "Type C" ;
VAL_ 1201 DTCI_SIB_TstNCmpltdOpCyc 0 "FALSE" 1 "TRUE" ;
VAL_ 1201 DTCI_SIB_TstNCmpltdLstClr 0 "FALSE" 1 "TRUE" ;
VAL_ 1201 DTCI_SIB_TstFldOpCyc 0 "FALSE" 1 "TRUE" ;
VAL_ 1201 DTCI_SIB_TstFldLstClr 0 "FALSE" 1 "TRUE" ;
VAL_ 1201 DTCI_SIB_TstFld 0 "FALSE" 1 "TRUE" ;
VAL_ 1201 DTCI_SIB_PndngDTC 0 "FALSE" 1 "TRUE" ;
VAL_ 1201 DTCI_SIB_DTCTriggered 0 "FALSE" 1 "TRUE" ;
VAL_ 1201 DTCI_SIB_WrnIndTrggrd 0 "FALSE" 1 "TRUE" ;
VAL_ 1201 DTCI_SIB_WrnIndRqd 0 "FALSE" 1 "TRUE" ;
VAL_ 1865 DTCI_SRR_LF_CnfrmdDTC 0 "FALSE" 1 "TRUE" ;
VAL_ 1865 DTCI_SRR_LF_DTCFaultType 0 "Not Supported" 1 "Type A" 2 "Type B" 3 "Type C" ;
VAL_ 1865 DTCI_SRR_LF_TstNCmpltdOpCyc 0 "FALSE" 1 "TRUE" ;
VAL_ 1865 DTCI_SRR_LF_TstNCmpltdLstClr 0 "FALSE" 1 "TRUE" ;
VAL_ 1865 DTCI_SRR_LF_TstFldOpCyc 0 "FALSE" 1 "TRUE" ;
VAL_ 1865 DTCI_SRR_LF_TstFldLstClr 0 "FALSE" 1 "TRUE" ;
VAL_ 1865 DTCI_SRR_LF_TstFld 0 "FALSE" 1 "TRUE" ;
VAL_ 1865 DTCI_SRR_LF_PndngDTC 0 "FALSE" 1 "TRUE" ;
VAL_ 1865 DTCI_SRR_LF_DTCTriggered 0 "FALSE" 1 "TRUE" ;
VAL_ 1865 DTCI_SRR_LF_WrnIndTrggrd 0 "FALSE" 1 "TRUE" ;
VAL_ 1865 DTCI_SRR_LF_WrnIndRqd 0 "FALSE" 1 "TRUE" ;
VAL_ 1200 DTCI_SRR_LR_CR_CnfrmdDTC 0 "FALSE" 1 "TRUE" ;
VAL_ 1200 DTCI_SRR_LR_CR_DTCFaultType 0 "Not Supported" 1 "Type A" 2 "Type B" 3 "Type C" ;
VAL_ 1200 DTCI_SRR_LR_CR_TstNCmpltdOpCyc 0 "FALSE" 1 "TRUE" ;
VAL_ 1200 DTCI_SRR_LR_CR_TstNCmpltdLstClr 0 "FALSE" 1 "TRUE" ;
VAL_ 1200 DTCI_SRR_LR_CR_TstFldOpCyc 0 "FALSE" 1 "TRUE" ;
VAL_ 1200 DTCI_SRR_LR_CR_TstFldLstClr 0 "FALSE" 1 "TRUE" ;
VAL_ 1200 DTCI_SRR_LR_CR_TstFld 0 "FALSE" 1 "TRUE" ;
VAL_ 1200 DTCI_SRR_LR_CR_PndngDTC 0 "FALSE" 1 "TRUE" ;
VAL_ 1200 DTCI_SRR_LR_CR_DTCTriggered 0 "FALSE" 1 "TRUE" ;
VAL_ 1200 DTCI_SRR_LR_CR_WrnIndTrggrd 0 "FALSE" 1 "TRUE" ;
VAL_ 1200 DTCI_SRR_LR_CR_WrnIndRqd 0 "FALSE" 1 "TRUE" ;
VAL_ 1866 DTCI_SRR_RF_CnfrmdDTC 0 "FALSE" 1 "TRUE" ;
VAL_ 1866 DTCI_SRR_RF_DTCFaultType 0 "Not Supported" 1 "Type A" 2 "Type B" 3 "Type C" ;
VAL_ 1866 DTCI_SRR_RF_TstNCmpltdOpCyc 0 "FALSE" 1 "TRUE" ;
VAL_ 1866 DTCI_SRR_RF_TstNCmpltdLstClr 0 "FALSE" 1 "TRUE" ;
VAL_ 1866 DTCI_SRR_RF_TstFldOpCyc 0 "FALSE" 1 "TRUE" ;
VAL_ 1866 DTCI_SRR_RF_TstFldLstClr 0 "FALSE" 1 "TRUE" ;
VAL_ 1866 DTCI_SRR_RF_TstFld 0 "FALSE" 1 "TRUE" ;
VAL_ 1866 DTCI_SRR_RF_PndngDTC 0 "FALSE" 1 "TRUE" ;
VAL_ 1866 DTCI_SRR_RF_DTCTriggered 0 "FALSE" 1 "TRUE" ;
VAL_ 1866 DTCI_SRR_RF_WrnIndTrggrd 0 "FALSE" 1 "TRUE" ;
VAL_ 1866 DTCI_SRR_RF_WrnIndRqd 0 "FALSE" 1 "TRUE" ;
